VERSION ""

NS_ :

BS_:

BU_: TCM_Diesel ECM_Diesel BECMB_EPM TCM ECM Generic_BCM GWM _delete APIM BCM DCDC_VQM PAM TSTR PCM
VAL_TABLE_ TrlrAidSetup_D_Rq 3 "NotUsed" 2 "EndSetup" 1 "BeginSetup" 0 "Inactive" ;
VAL_TABLE_ IsaOffst_D_Stat 15 "Faulty" 14 "Null" 13 "Thirteen" 12 "Twelve" 11 "Eleven" 10 "Ten" 9 "Nine" 8 "Eight" 7 "Seven" 6 "Six" 5 "Five" 4 "Four" 3 "Three" 2 "Two" 1 "One" 0 "Zero" ;
VAL_TABLE_ IsaVLimUnit_D_Rq 3 "NoDataExists" 2 "Mph" 1 "Kph" 0 "Null" ;
VAL_TABLE_ ApaChime_D_Rq 7 "NotUsed2" 6 "NotUsed1" 5 "Warning_Chime" 4 "Finish_Chime" 3 "Stop_Now_Chime" 2 "Spot_Ready_Chime" 1 "Spot_Found_Chime" 0 "No_Chime" ;
VAL_TABLE_ IsaVLim_D_Rq 183 "NotUsed_3_to_72_toHexFC" 2 "LimitSpeed2_to_178_toHexB2" 255 "Faulty" 254 "NoDataExists" 253 "NotUsed_73" 182 "NotUsed_2" 181 "NotUsed_1" 180 "LimitSpeed_180_kph_mph" 179 "LimitSpeed_179_kph_mph" 1 "LimitSpeed_1_kph_mph" 0 "LimitSpeed_0_kph_mph" ;
VAL_TABLE_ SlMde_D_Stat 3 "NotUsed" 2 "Manual_Mode" 1 "Auto_Mode" 0 "Null" ;
VAL_TABLE_ SlMde_D_RqDsply 3 "NotUsed" 2 "ManualSpeed_LimiterSymbol" 1 "AutoSpeed_LimiterSymbol" 0 "NoSpeed_LimiterSymbol" ;
VAL_TABLE_ SlMde_D_Rq 3 "NotUsed" 2 "Manual_Mode" 1 "Auto_Mode" 0 "Null" ;
VAL_TABLE_ Faulty_FF 255 "Faulty" ;
VAL_TABLE_ TrnIpcDsplyRng_D_Stat 3 "NotUsed" 2 "Flash" 1 "On" 0 "Blank_No_Display" ;
VAL_TABLE_ NoYesNoDataFaulty 3 "Faulty" 2 "NoDataExists" 1 "Yes" 0 "No" ;
VAL_TABLE_ SidePrkSnsR4_D_Stat 15 "NotUsed" 14 "NotFullyScannedYet" 13 "NoObjectInSector" 12 "Zone12" 11 "Zone11" 10 "Zone10" 9 "Zone9" 8 "Zone8" 7 "Zone7" 6 "Zone6" 5 "Zone5" 4 "Zone4" 3 "Zone3" 2 "Zone2" 1 "Zone1" 0 "Off" ;
VAL_TABLE_ PtDrvMde_D_Rq 15 "Faulty" 14 "NotUsed11" 13 "NotUsed10" 12 "NotUsed9" 11 "NotUsed8" 10 "NotUsed7" 9 "NotUsed6" 8 "NotUsed5" 7 "NotUsed4" 6 "NotUsed3" 5 "NotUsed2" 4 "NotUsed1" 3 "TowHaulGradeAssist" 2 "SnowWet" 1 "Sport" 0 "Normal" ;
VAL_TABLE_ SteEffort_D_Stat 7 "NotUsed5" 6 "NotUsed4" 5 "NotUsed3" 4 "NotUsed2" 3 "NotUsed1" 2 "Comfort" 1 "Sport" 0 "Normal" ;
VAL_TABLE_ Null_Off_On 3 "NotUsed" 2 "On" 1 "Off" 0 "Null" ;
VAL_TABLE_ TrlrAidMsgTxt_D_Rq 31 "Message31" 30 "Message30" 29 "Message29" 28 "Message28" 27 "Message27" 26 "Message26" 25 "Message25" 24 "Message24" 23 "Message23" 22 "Message22" 21 "Message21" 20 "Message20" 19 "Message19" 18 "Message18" 17 "Message17" 16 "Message16" 15 "Message15" 14 "Message14" 13 "Message13" 12 "Message12" 11 "Message11" 10 "Message10" 9 "Message9" 8 "Message8" 7 "Message7" 6 "Message6" 5 "Message5" 4 "Message4" 3 "Message3" 2 "Message2" 1 "Message1" 0 "NoMessage" ;
VAL_TABLE_ Invalid_7F 127 "Invalid" ;
VAL_TABLE_ Faulty_1FFF 8191 "Faulty" ;
VAL_TABLE_ VehStab_D_Stat 15 "Faulty" 14 "NotUsed7" 13 "NotUsed6" 12 "NotUsed5" 11 "NotUsed4" 10 "NotUsed3" 9 "NotUsed2" 8 "NotUsed1" 7 "High_SSRA_no_OS" 6 "Straight" 5 "Post_Oversteer" 4 "Post_Transition" 3 "Countersteer" 2 "Understeer" 1 "Oversteer" 0 "Linear" ;
VAL_TABLE_ FohEng_D_Rq 3 "AutoEnable_ParkEnable" 2 "AutoDisable_ParkEnable" 1 "AutoEnable_ParkDisable" 0 "Disable_Stop" ;
VAL_TABLE_ DieslPrtc2_D_RqDsply 15 "NotUsed4" 14 "NotUsed3" 13 "NotUsed2" 12 "NotUsed1" 11 "OCR_ExhFilterClean_Stopped" 10 "OCR_ExhFilterCleaned" 9 "RgnOff_AtLimit" 8 "RgnOff_Overloaded" 7 "RgnOff_Loaded" 6 "Exhaust_Filter_Full" 5 "DPF_Overlimit" 4 "DPF_AtLimit" 3 "ExhFilter_Drive_Completed" 2 "Cleaning_Exhaust_Filter" 1 "DPF_Overloaded" 0 "DPF_Normal_Operation" ;
VAL_TABLE_ Null_Pers1_4_Vehicle 7 "Unused_2" 6 "Unused_1" 5 "Vehicle" 4 "PERS_4" 3 "PERS_3" 2 "PERS_2" 1 "PERS_1" 0 "Null" ;
VAL_TABLE_ PrkLckCtlEnbl_D_RqIpc 3 "Rq_Towing" 2 "Rq_Enable" 1 "Rq_Disable" 0 "Null" ;
VAL_TABLE_ PrkLckCtlUnlck_D_Stat 3 "Trans_And_Steer_Unlckd" 2 "Steering_Unlckd" 1 "Transmission_Unlckd" 0 "Null" ;
VAL_TABLE_ VehKeyActv_D_Stat 15 "NotUsed7" 14 "NotUsed6" 13 "NotUsed5" 12 "NotUsed4" 11 "NotUsed3" 10 "NotUsed2" 9 "NotUsed1" 8 "Key8Active" 7 "Key7Active" 6 "Key6Active" 5 "Key5Active" 4 "Key4Active" 3 "Key3Active" 2 "Key2Active" 1 "Key1Active" 0 "NoKeyActive" ;
VAL_TABLE_ VehLckInd_D_Rq 3 "NotUsed" 2 "On_Day" 1 "On_Night" 0 "Off" ;
VAL_TABLE_ PrkBrkDynmc_D_Allw 3 "NotUsed" 2 "EPB_ECD_NotPossible" 1 "EPB_ECD_Possible" 0 "Used_at_Start_Up" ;
VAL_TABLE_ TrnGearMsgTxt_D_Rq 31 "Message_31" 30 "Message_30" 29 "Message_29" 28 "Message_28" 27 "Message_27" 26 "Message_26" 25 "Message_25" 24 "Message_24" 23 "Message_23" 22 "Message_22" 21 "Message_21" 20 "Message_20" 19 "Message_19" 18 "Message_18" 17 "Message_17" 16 "Message_16" 15 "Message_15" 14 "Message_14" 13 "Message_13" 12 "Message_12" 11 "Message_11" 10 "Message_10" 9 "Message_9" 8 "Message_8" 7 "Message_7" 6 "Message_6" 5 "Message_5" 4 "Message_4" 3 "Message_3" 2 "Message_2" 1 "Message_1" 0 "NoMessage" ;
VAL_TABLE_ Off_On_Unknown_Invalid 3 "Invalid" 2 "Unknown" 1 "On" 0 "Off" ;
VAL_TABLE_ AutoLghtMde_D_Stat 3 "Not_Used" 2 "GFHB" 1 "AHBC" 0 "Manual" ;
VAL_TABLE_ GfhbDistr_D_Stat 7 "High_Beam_Classis" 6 "High_Beam_GFHB" 5 "GFHB_with_Vert_Adjustment" 4 "GFHB_with_Spot" 3 "Motorway" 2 "Low_Beam_GFHB" 1 "Low_Beam_Classic" 0 "Symmetric" ;
VAL_TABLE_ GfhbV_D 3 "Immediately" 2 "Fast" 1 "Medium" 0 "Slow" ;
VAL_TABLE_ GfhbLamp_D_Stat 3 "Both_On" 2 "Left_On_Right_Off" 1 "Right_On_Left_Off" 0 "Both_Off" ;
VAL_TABLE_ GfhbDistrChng_D_Stat 3 "Both_in_Transition" 2 "Left_in_Transition" 1 "Right_in_Transition" 0 "Both_Static" ;
VAL_TABLE_ NoData_Faulty_3E_3F 63 "Faulty" 62 "NoDataExists" ;
VAL_TABLE_ Unknown_Invalid_1FE_1FF 511 "Invalid" 510 "Unknown" ;
VAL_TABLE_ Invalid_0x0 0 "Invalid" ;
VAL_TABLE_ Unknown_Invalid_3E_3F 63 "Invalid" 62 "Unknown" ;
VAL_TABLE_ Faulty_1FF 511 "Faulty" ;
VAL_TABLE_ NoData_Faulty_1FFF_1FFE 8191 "Faulty" 8190 "NoDataExists" ;
VAL_TABLE_ AwdSys_D_Stat 3 "Faulty" 2 "NotUsed" 1 "_4x4_L_H_Active" 0 "_4x4_L_H_Inactive" ;
VAL_TABLE_ EmotiveType_D_Dsply 3 "EmotiveDisplay_3" 2 "EmotiveDisplay_2" 1 "EmotiveDisplay_1" 0 "Null" ;
VAL_TABLE_ AutoRgenTxt_B_RqDsply 1 "AutExhFilterCleanOFF" 0 "AutExhFilterCleanON" ;
VAL_TABLE_ AutoRgen_D_Rq 3 "NotUsed" 2 "AutExhFilterCleanOFF" 1 "AutExhFilterCleanON" 0 "No_Mode_Selected" ;
VAL_TABLE_ TrnSrvcRqd_B_Rq 1 "On" 0 "Off" ;
VAL_TABLE_ PlgOvrrdStrt_D_Cmd 3 "NotUsed" 2 "Override_Plug_Status" 1 "Dont_Override_Plug_Status" 0 "Null_State" ;
VAL_TABLE_ immoSecureIdleMode 3 "NotUsed2" 2 "NotUsed1" 1 "Active" 0 "Inactive" ;
VAL_TABLE_ SteMdule_D_Stat 7 "NotUsed" 6 "EPAS_Failure3" 5 "EPAS_Failure2" 4 "System_Failure" 3 "EPAS_Shutdown" 2 "Normal_Op_Full_Assist" 1 "Normal_Op_Limited_Assist" 0 "EPAS_Initialization" ;
VAL_TABLE_ Faulty_3FF 1023 "Faulty" ;
VAL_TABLE_ Invalid_F 15 "Invalid" ;
VAL_TABLE_ Invalid_1F 31 "Invalid" ;
VAL_TABLE_ NoData_Faulty_FFFFFE_FFFFFF 16777215 "Faulty" 16777214 "NoDataExists" ;
VAL_TABLE_ NoData_Faulty_FE_FF 255 "Faulty" 254 "NoDataExists" ;
VAL_TABLE_ PtRmtRprt_D_Rq 15 "NotUsed6" 14 "NotUsed5" 13 "NotUsed4" 12 "NotUsed3" 11 "NotUsed2" 10 "NotUsed1" 9 "Rprt_Rq_Chrg_Not_Occur" 8 "Rprt_Rq_SOC_1_Reached" 7 "Rprt_Rq_Battery_Temp" 6 "Rprt_Rq_Reduced_Perf" 5 "Rprt_Rq_Limited_Perf" 4 "Rprt_Rq_Charge_Fault" 3 "Rprt_Rq_Bulk_Charged" 2 "Rprt_Rq_Preconditioned" 1 "Rprt_Rq_Trip_Distance" 0 "No_Report_Request" ;
VAL_TABLE_ Invalid_NotReq_Req 0 "Invalid" 1 "Not_Requested" 2 "Requested" 3 "NotUsed" ;
VAL_TABLE_ Invalid_NoConflict_Conflict 7 "NotUsed5" 6 "NotUsed4" 5 "NotUsed3" 4 "NotUsed2" 3 "NotUsed1" 2 "Clonflict_Exists" 1 "No_Conflict" 0 "Invalid" ;
VAL_TABLE_ Inactive_NotReq_Req 0 "Inactive" 1 "Not_Requested" 2 "Requested" 3 "NotUsed" ;
VAL_TABLE_ PreCondStat_D_Dsply 7 "Reserved3" 6 "Reserved2" 5 "Reserved1" 4 "Faulted" 3 "Complete" 2 "In_Progress" 1 "Scheduled" 0 "Not_Scheduled" ;
VAL_TABLE_ BattElecPerf_D_Actl 7 "NotUsed" 6 "Hot_Batt_Severe_Lim_Perf" 5 "Hot_Batt_Reduced_Perf" 4 "Hot_Batt_Close_to_lim_Per" 3 "Cold_Batt_Severe_Lim_Perf" 2 "Cold_Batt_Reduced_Perf" 1 "Cold_Batt_Close_to_lim_Pe" 0 "Ok_no_message_displayed" ;
VAL_TABLE_ ChkPlgtoStrt_D_Dsply 3 "NotUsed" 2 "Is_VehicleUnplugged_Prompt" 1 "Check_Plug_to_start" 0 "No_Message_Display" ;
VAL_TABLE_ PwrFlowTxt_D_Dsply 15 "NotUsed7" 14 "NotUsed6" 13 "NotUsed5" 12 "NotUsed4" 11 "NotUsed3" 10 "NotUsed2" 9 "NotUsed1" 8 "Disp_Charge_Cmplt_Txt" 7 "Disp_Remote_Start_Txt" 6 "Disp_Eng_Drv_Txt" 5 "Disp_Elec_Drv_Txt" 4 "Disp_Idle_with_Chrg_Txt" 3 "Disp_Idle_Txt" 2 "Disp_Charg_HV_Batt_Txt" 1 "Disp_Hyb_Drive_Txt" 0 "No_Text" ;
VAL_TABLE_ EngOnMsg_D_Dsply 12 "Battery_Temperature" 11 "Hill_Decent_Control" 10 "Fuel_Maintenance" 9 "Oil_Maintenance" 8 "Normal_Operation" 7 "Low_Gear" 6 "Batt_Charging" 5 "Engine_Cold" 4 "Neutral_Gear" 3 "Heater_Setting" 2 "High_Speed" 1 "Acceleration" 0 "No_Display" 13 "Not_Used_States_0xD_0x1F" ;
VAL_TABLE_ PtDataKeyId_D_Stat 15 "NotUsed5" 14 "NotUsed4" 13 "NotUsed3" 12 "NotUsed2" 11 "NotUsed1" 10 "Tot_Veh_NUT" 9 "Cust_4_NUT" 8 "Cust_3_NUT" 7 "Cust_2_NUT" 6 "Cust_1_NUT" 5 "Tot_Veh_Stat" 4 "Cust_4_Stat" 3 "Cust_3_Stat" 2 "Cust_2_Stat" 1 "Cust_1_Stat" 0 "Null" ;
VAL_TABLE_ ChrgStat_D_Dsply 7 "NotUsed" 6 "Complete" 5 "Scheduled" 4 "In_Progress" 3 "Fault_Outside_Car" 2 "Fault_Inside_Car" 1 "Fault_Unknown_Location" 0 "Not_Ready" ;
VAL_TABLE_ TrnLvrV_D_Rq 3 "Full_Speed" 2 "Aggressive" 1 "Normal" 0 "Quiet" ;
VAL_TABLE_ FuelMaintMde_D_Rq 3 "Feature_Not_Present" 2 "Fuel_Maint_Req_Now" 1 "Fuel_Maint_Req_Soon" 0 "NoRequest" ;
VAL_TABLE_ FuelMaintMde_D_Dsply 3 "Feature_Not_Present" 2 "In_Fuel_Maint_Mode" 1 "Close_to_Fuel_Maint" 0 "OK" ;
VAL_TABLE_ DynoMde_B_Cmd 1 "Two_Wheel_Dyno" 0 "Normal_Operation" ;
VAL_TABLE_ HvacPrecondRecirc_D_Rq 3 "Last_User_Setting" 2 "Auto" 1 "Recirc" 0 "Outside" ;
VAL_TABLE_ HvacPrecondAC_D_Rq 3 "Last_User_Setting" 2 "Auto" 1 "On" 0 "Off" ;
VAL_TABLE_ HybMdeStat_D_Dsply 7 "NotUsed2" 6 "NotUsed1" 5 "EV_Override" 4 "Forced_EV_Mode" 3 "Forced_Charge_Sustain_Mode" 2 "Auto_Charge_Sustain_Mode" 1 "Auto_Charge_Deplete_Mode" 0 "Null_State" ;
VAL_TABLE_ PwFlowPlgBatt_D_Dsply 3 "NotUsed" 2 "Flow_from_Plug_to_Batt" 1 "Flow_from_Batt_to_Plug" 0 "No_Flow" ;
VAL_TABLE_ PwFlowEngMtr_D_Dsply 3 "NotUsed" 2 "Flow_from_Eng_to_Mtr" 1 "Flow_from_Mtr_to_Eng" 0 "No_Flow" ;
VAL_TABLE_ PwFlowEngFuel_D_Dsply 3 "NotUsed" 2 "Flow_from_Eng_to_Fuel" 1 "Flow_from_Fuel_to_Eng" 0 "No_Flow" ;
VAL_TABLE_ PwFlowMtrDrv_D_Dsply 3 "NotUsed" 2 "Flow_from_Mtr_to_Axle" 1 "Flow_from_Axle_to_Mtr" 0 "No_FLow" ;
VAL_TABLE_ PwFlowEngDrv_D_Dsply 3 "NotUsed" 2 "Flow_from_Eng_to_Axle" 1 "Flow_from_Axle_to_Eng" 0 "No_Flow" ;
VAL_TABLE_ PwFlowBattMtr_D_Dsply 3 "NotUsed" 2 "Flow_from_Batt_to_Mtr" 1 "Flow_from_Mtr_to_Batt" 0 "No_Flow" ;
VAL_TABLE_ Null_Override_Invalid 3 "NotUsed" 2 "Invalid" 1 "Override" 0 "Null" ;
VAL_TABLE_ HybMdeMsgTxt_D_Rq 7 "NotUsed2" 6 "NotUsed1" 5 "EV_Not_Avail_Message" 4 "EV_Mode_Message" 3 "Delayed_Discharge_Message" 2 "Override_Available_Message" 1 "AutoMode_Message" 0 "Null_NoMessage_Request" ;
VAL_TABLE_ HybMdeLimMsgTxt_D_Rq 3 "Limited_Low_Power_and_SOC" 2 "Limited_Low_SOC" 1 "Limited_Low_Power" 0 "Null" ;
VAL_TABLE_ CenterStackRing_D_Actl 3 "LimitedOn" 2 "On" 1 "Off" 0 "Null" ;
VAL_TABLE_ ConsTipUnitPt_D_Dsply 3 "NotUsed" 2 "FuelEconomy" 1 "Distance" 0 "Percentage" ;
VAL_TABLE_ ConsTipMsg1_D_Dsply 15 "NotUsed10" 14 "NotUsed9" 13 "NotUsed8" 12 "NotUsed7" 11 "NotUsed6" 10 "NotUsed5" 9 "NotUsed4" 8 "NotUsed3" 7 "NotUsed2" 6 "NotUsed1" 5 "ReduceIdleTime" 4 "ClimateUsage" 3 "VehicleSpeed" 2 "Deceleration" 1 "Acceleration" 0 "NoDisplay" ;
VAL_TABLE_ NoData_Faulty_FFFE_FFFF 65535 "Faulty" 65534 "NoDataExists" ;
VAL_TABLE_ NoData_Faulty_FFE_FFF 4095 "Faulty" 4094 "NoDataExists" ;
VAL_TABLE_ NoData_Faulty_3FE_3FF 1023 "Faulty" 1022 "NoDataExists" ;
VAL_TABLE_ ReFuelSysStat_D_Dsply 7 "NotUsed3" 6 "NotUsed2" 5 "NotUsed1" 4 "Refuel_Err" 3 "Close_Fuel_Door" 2 "Refuel_Ready" 1 "Wait_To_Fuel" 0 "Null" ;
VAL_TABLE_ OffOn_NotUsed 3 "NotUsed2" 2 "NotUsed1" 1 "On" 0 "Off" ;
VAL_TABLE_ DrQltyDrv_D_StatGsm 7 "Faulty" 6 "NoDataExists" 5 "NotUsed2" 4 "NotUsed1" 3 "ClosedDegraded" 2 "OpenDegraded" 1 "ClosedOkay" 0 "OpenOkay" ;
VAL_TABLE_ ChrgrInPwType_D_Actl 6 "NotUsed3" 5 "NotUsed2" 4 "NotUsed1" 3 "DC_Fast_Charging" 2 "AC_Level2_240v" 1 "AC_Level1_120v" 0 "EVSE_Not_Detected" ;
VAL_TABLE_ ChrgrSysFalt1_D_Stat 3 "NotUsed" 2 "Pass" 1 "Fail" 0 "NotDiagnoseYet" ;
VAL_TABLE_ PepsKeyActv_D_Stat 15 "NotUsed11" 14 "NotUsed10" 13 "NotUsed9" 12 "NotUsed8" 11 "NotUsed7" 10 "NotUsed6" 9 "NotUsed5" 8 "Key4Active" 7 "NotUsed4" 6 "NotUsed3" 5 "NotUsed2" 4 "Key3Active" 3 "NotUsed1" 2 "Key2Active" 1 "Key1Active" 0 "NoKeyActive" ;
VAL_TABLE_ CellRstrt_D_Rq 3 "NotUsed" 2 "RemoteCancel" 1 "RemoteStart" 0 "NoRequest" ;
VAL_TABLE_ CellChirp_D_Rq 7 "NotUsed3" 6 "NotUsed2" 5 "NotUsed1" 4 "Honk" 3 "ChirpHonk" 2 "Chirp2" 1 "Chirp1" 0 "NoRequest" ;
VAL_TABLE_ CellLock_D_Rq 7 "NotUsed3" 6 "NotUsed2" 5 "NotUsed1" 4 "TrunkRelPopGlassLgCargo" 3 "LockAllDoorsandTailgate" 2 "UnlockDriversDoor" 1 "UnlockAllDoorsandTailgate" 0 "NoRequest" ;
VAL_TABLE_ NoData_Faulty_7FE_7FF 2047 "Faulty" 2046 "NoDataExists" ;
VAL_TABLE_ EngIdlShutDwnTxt_D_Rq 3 "NotUsed" 2 "EngineShutdownOnPrevDrive" 1 "FeatureDisabledDueToFault" 0 "NoMessage" ;
VAL_TABLE_ DrvPerfMde 3 "Sport" 2 "Normal" 1 "NotUsed" 0 "NoModeSelected" ;
VAL_TABLE_ NoData_Fault_1FF_1FE 511 "Fault" 510 "NoDataExists" ;
VAL_TABLE_ NoData_Fault_FFE_FFF 4095 "Fault" 4094 "NoDataExists" ;
VAL_TABLE_ ValetMode_D_Stat 3 "Not used_3" 2 "On" 1 "Off" 0 "Null" ;
VAL_TABLE_ WeekdayEndHR_St 31 "Invalid" 30 "Unknown" 29 "Reserved_29" 28 "Reserved_28" 27 "Reserved_27" 26 "Reserved_26" 25 "Reserved_25" 24 "Reserved_24" ;
VAL_TABLE_ WeekdayEndMin_St 63 "Faulty" 62 "No_data_exists" 61 "Reserverd" 60 "Reserverd" ;
VAL_TABLE_ WeekdayStartHR_St 31 "Invalid" 30 "Unknown" 29 "Reserved_29" 28 "Reserved_28" 27 "Reserved_27" 26 "Reserved_26" 25 "Reserved_25" 24 "Reserved_24" ;
VAL_TABLE_ WeekdayStartMin_St 63 "Faulty" 62 "No_data_exists" 61 "Reserverd" 60 "Reserverd" ;
VAL_TABLE_ EngIdlShutDown_D_Stat 3 "Not_used" 2 "Engine_Shutdown" 1 "Initiated_Countdown" 0 "Normal_Operation" ;
VAL_TABLE_ StopStrtDrvMde_D_Indic 3 "NotUsed" 2 "StartStop_IndirectDeselect" 1 "StopStart_Deselected" 0 "StopStart_Selected" ;
VAL_TABLE_ StopStrtDrvMde_D_RqMnu 3 "NotUsed2" 2 "NotUsed1" 1 "StopStart_Deselected" 0 "StopStart_Selected" ;
VAL_TABLE_ StopStrtStdby_D_Indic 6 "NotUsed2" 5 "Telltale_Struck_Out" 4 "Telltale_Flashing_Amber" 3 "Telltale_On_Amber" 2 "Telltale_Flashing_Green" 1 "Telltale_On_Green" 0 "Telltale_Off" 7 "NotUsed3" ;
VAL_TABLE_ Quality_Faulty 3 "OK" 2 "Degraded" 1 "No_Data_Exists" 0 "Faulty" ;
VAL_TABLE_ TrnDtpCmd_D_Actl 7 "NotUsed4" 6 "NotUsed3" 5 "NotUsed2" 4 "Relatch" 3 "Deploy" 2 "Self_Test" 1 "No_Command" 0 "NotUsed1" ;
VAL_TABLE_ TrnGsmNtmState_D_Actl 3 "Faulty" 2 "Neutral_Tow_Mode" 1 "Car_Wash_Mode" 0 "None" ;
VAL_TABLE_ TrnTrcmPwmSig_D_Actl 15 "Faulty" 14 "NoDataExists" 13 "NotUsed5" 12 "NotUsed4" 11 "NotUsed3" 10 "NotUsed2" 9 "NotUsed1" 8 "Default_To_Park" 7 "Neutral_Tow" 6 "Car_Wash_Mode" 5 "Manual" 4 "Drive" 3 "Neutral" 2 "Reverse" 1 "Park" 0 "No_Gear" ;
VAL_TABLE_ RgenBrkDynoMde_B_Actl 1 "TwoWheelDyno" 0 "NormalOperation" ;
VAL_TABLE_ Fault_3FFF 16383 "Fault" ;
VAL_TABLE_ PrkBrkActv_D_RqTrnGear 3 "NotUsed2" 2 "RequestParkBrakeEngage" 1 "NoRequest" 0 "NotUsed1" ;
VAL_TABLE_ NoRequest_Request 1 "Request" 0 "NoRequest" ;
VAL_TABLE_ Fault_FFF_NoData 4094 "NoDataExists" 4095 "Fault" ;
VAL_TABLE_ Fault_3FF_NoData 1022 "NoDataExists" 1023 "Fault" ;
VAL_TABLE_ Foh_D_Stat 7 "Unused3" 6 "Unused2" 5 "Unused1" 4 "Stopping" 3 "Running" 2 "Starting" 1 "Prestart" 0 "Off" ;
VAL_TABLE_ FohFalt_D_Stat 15 "NotUsed4" 14 "NotUsed3" 13 "NotUsed2" 12 "NotUsed1" 11 "FuelTypeDoesNotMatchFOH" 10 "Lifecycle_ModeNotSet" 9 "AuxElectricCoolantPumpInop" 8 "TimeDelayAvoidExcessCycl" 7 "Fuel_Level_OutofRange" 6 "External_Fault" 5 "Internal_Fault" 4 "Voltage_limitation" 3 "Impact_Event" 2 "CoolantTemp_OutofRange" 1 "AmbientTemp_OutofRange" 0 "No_Disable" ;
VAL_TABLE_ FohRqRun_B_Rq 1 "SubmitRequest_toRun" 0 "DoesNotSubmitRequest_toRun" ;
VAL_TABLE_ OKLowVeryLow 3 "NotUsed" 2 "VeryLow" 1 "Low" 0 "OK" ;
VAL_TABLE_ Fault_1FF 511 "Fault" ;
VAL_TABLE_ NoMessage_DisplayMessage 1 "DisplayMessage" 0 "NoMessage" ;
VAL_TABLE_ EngineBrakeOff_Active 1 "Engine_Braking_Activated" 0 "Engine_Braking_Off" ;
VAL_TABLE_ NoEngineBrake_Brake 1 "Engine_Braking" 0 "No_Engine_Braking" ;
VAL_TABLE_ PlgActv_D_ActlChrgr 3 "Faulty" 2 "Not used_2" 1 "On_Plug__Connected_" 0 "Off_Plug__Disconnected_" ;
VAL_TABLE_ EngSrvcRqd_B_Rq 1 "Engine_Service_Required" 0 "No_engine_service_required" ;
VAL_TABLE_ WeekendEndHR_St 31 "Invalid" 30 "Unknown" 29 "Reserved_29" 28 "Reserved_28" 27 "Reserved_27" 26 "Reserved_26" 25 "Reserved_25" 24 "Reserved_24" ;
VAL_TABLE_ WeekendEndMin_St 63 "Faulty" 62 "No_data_exists" 61 "Reserverd" 60 "Reserverd" ;
VAL_TABLE_ WeekendStartHR_St 31 "Invalid" 30 "Unknown" 29 "Reserved_29" 28 "Reserved_28" 27 "Reserved_27" 26 "Reserved_26" 25 "Reserved_25" 24 "Reserved_24" ;
VAL_TABLE_ WeekendStartMin_St 63 "Faulty" 62 "No_data_exists" 61 "Reserverd" 60 "Reserverd" ;
VAL_TABLE_ NextUsg_Toggle_St 2 "Disabled" 1 "Enabled" 0 "Null" ;
VAL_TABLE_ NxtUsgDay_No_Actl 31 "Invalid" ;
VAL_TABLE_ NxtUsgHr_No_Actl 31 "Invalid" 30 "Unknown" ;
VAL_TABLE_ NxtUsgMin_No_Actl 63 "Invalid" 62 "Unknown" ;
VAL_TABLE_ NxtUsgMnth_No_Actl 15 "Invalid" ;
VAL_TABLE_ NxtUsgPreCndID_No_Actl 0 "Invalid" ;
VAL_TABLE_ NxtUsgYr_No_Actl 31 "Invalid" ;
VAL_TABLE_ PtRmtRprt_D_Stat 9 "In_Progress_Chrg_Not_Occur" 8 "In_Progress_SOC_1_Reached" 7 "In_Progress_Battery_Temp" 6 "In_Progress_Reduced_Perf" 5 "In_Progress_Limited_Perf" 4 "In_Progress_Charge_Fault" 3 "In_Progress_Bulk_Charged" 2 "In_Progress_Preconditioned" 1 "In_Progress_Trip_Distance" 0 "Not_In_Progress" ;
VAL_TABLE_ Allowed_Denied 1 "Denied" 0 "Allowed" ;
VAL_TABLE_ PrkAidMsgTxt_D_Rq 15 "NotUsed7" 14 "NotUsed6" 13 "NotUsed5" 12 "R_Sns_Inactive_Trlr_atch" 11 "Not_Avail_Trlr_attchd" 10 "Fail_Mode_no_Chime" 9 "Fail_Mode_with_Chime" 8 "NotUsed4" 7 "NotUsed3" 6 "Park_Sys_Alternate_Mode" 5 "R_Snsrs_On_F_Snsrs_On" 4 "NotUsed2" 3 "NotUsed1" 2 "R_Snsrs_Off_F_Snsrs_On" 1 "R_Snsrs_On_F_Snsrs_Off" 0 "All_Park_Sensors_Off" ;
VAL_TABLE_ PrkAidSns_D_Stat 15 "Zone_15" 14 "Zone_14" 13 "Zone_13" 12 "Zone_12" 11 "Zone_11" 10 "Zone_10" 9 "Zone_9" 8 "Zone_8" 7 "Zone_7" 6 "Zone_6" 5 "Zone_5" 4 "Zone_4" 3 "Zone_3" 2 "Zone_2" 1 "Zone_1" 0 "Off" ;
VAL_TABLE_ PrkAid_D_Falt 7 "NotUsed2" 6 "NotUsed1" 5 "Failure_Front_PSM_Sensors" 4 "No_Data_Exists" 3 "Failure_Rear_Sensors" 2 "Speaker_Fault" 1 "ECU_Fault" 0 "No_Fault" ;
VAL_TABLE_ OffOnNoDataFault 3 "Fault" 2 "No_Data_Exists" 1 "On" 0 "Off" ;
VAL_TABLE_ ApaSwtch_D_RqDrv 3 "Faulty" 2 "Stuck" 1 "Pressed" 0 "NotPressed" ;
VAL_TABLE_ ApaActvSd_D_Actl 3 "Dirver_Side" 2 "Passenger_Side" 1 "No_Side" 0 "Null" ;
VAL_TABLE_ ApaMdeStat_D_RqDrv 7 "Faulty" 6 "Off" 5 "NotUsed2" 4 "NotUsed1" 3 "POA" 2 "PPA" 1 "SAPP" 0 "Inactive" ;
VAL_TABLE_ ApaMde_D_Avail 15 "NotUsed7" 14 "NotUsed6" 13 "NotUsed5" 12 "NotUsed4" 11 "NotUsed3" 10 "NotUsed2" 9 "NotUsed1" 8 "PPA_POA" 7 "SAPP_POA" 6 "POA" 5 "PPA" 4 "SAPP" 3 "SAPP_PPA_POA" 2 "SAPP_PPA" 1 "None" 0 "Null" ;
VAL_TABLE_ ApaMde_D_Stat 7 "NotUsed3" 6 "NotUsed2" 5 "NotUsed1" 4 "POA" 3 "PPA" 2 "SAPP" 1 "Off" 0 "Null" ;
VAL_TABLE_ FrostWarn_D_Stat 3 "NotUsed" 2 "On_Amber" 1 "On_Red" 0 "Off" ;
VAL_TABLE_ SteWhlLckMsgTxt_D_Rq 3 "NotUsed" 2 "Message_2" 1 "Message_1" 0 "No_Message" ;
VAL_TABLE_ GearRvrse_D_Actl 7 "Fault" 6 "NotUsed_3" 5 "NotUsed_2" 4 "NotUsed_1" 3 "Active_confirmed" 2 "Active_not_confirmed" 1 "Inactive_confirmed" 0 "Inactive_not_confirmed" ;
VAL_TABLE_ DrTGate_D_Rq 3 "NotUsed" 2 "Closing" 1 "Opening" 0 "Not_Moving" ;
VAL_TABLE_ WndwSide_D_Stat 3 "BothWindow_Operating" 2 "RearWindow_Operating" 1 "FrontWindow_Operating" 0 "NoWindows_Operating" ;
VAL_TABLE_ DcacElPw_D_Rq 3 "NotUsed" 2 "AC_HighPower_Requested" 1 "AC_LowPower_Requested" 0 "AC_Power_NotRequested" ;
VAL_TABLE_ Null_Ack_Nack_NotUsed 3 "Not_Used" 2 "Nack" 1 "Ack" 0 "Null" ;
VAL_TABLE_ Null_Reset 1 "Reset" 0 "Null" ;
VAL_TABLE_ Unknown_FFFD_Invalid_NotSup 65535 "Not_Supported" 65534 "Invalid" 65533 "Unknown" ;
VAL_TABLE_ HvacBlwrFront_D_Stat 31 "Not_Used" 20 "Full_On" 19 "95_Percent" 18 "90_Percent" 17 "85_Percent" 16 "80_Percent" 15 "75_Percent" 14 "70_Percent" 13 "65_Percent" 12 "60_Percent" 11 "55_Percent" 10 "50_Percent" 9 "45_Percent" 8 "40_Percent" 7 "35_Percent" 6 "30_Percent" 5 "25_Percent" 4 "20_Percent" 3 "15_Percent" 2 "10_Percent" 1 "5_Percent" 0 "Off" ;
VAL_TABLE_ immoMsgTxt_D_Rq 15 "Immo_Msg_15" 14 "Immo_Msg_14" 13 "Immo_Msg_13" 12 "Immo_Msg_12" 11 "Immo_Msg_11" 10 "Immo_Msg_10" 9 "Immo_Msg_9" 8 "Immo_Msg_8" 7 "Immo_Msg_7" 6 "Immo_Msg_6" 5 "Immo_Msg_5" 4 "Immo_Msg_4" 3 "Immo_Msg_3" 2 "Immo_Msg_2" 1 "Immo_Msg_1" 0 "Immo_Msg_0_Null" ;
VAL_TABLE_ BattTracWarnLamp_B_Rq 1 "On" 0 "Off" ;
VAL_TABLE_ BattTracSrvcRqd_B_Rq 1 "On" 0 "Off" ;
VAL_TABLE_ HtrnWarnLamp_B_Dsply 1 "On" 0 "Off" ;
VAL_TABLE_ HtrnSrvcRqd_B_Dsply 1 "On" 0 "Off" ;
VAL_TABLE_ NtfyDrvTrgtDist_L_Rq 4095 "Trip_dist_alert_disabled" 0 "Inactive" ;
VAL_TABLE_ NtfyDrvSocLvl1_Pc_Rq 127 "TargetSOCNotificationAlert" 0 "Inactive" ;
VAL_TABLE_ PtWakeupActv1_B_Rq 1 "Wake_up_Powertrain_via_HW" 0 "Don_t_Wake_Up_Powertrain" ;
VAL_TABLE_ PreCondACSet_D_Actl 3 "Last_User_Setting" 2 "Auto" 1 "On" 0 "Off" ;
VAL_TABLE_ PreCondFanSet_D_Actl 15 "Not_used" 14 "Not_used" 13 "Not_used" 12 "Not_used" 11 "Not_used" 10 "Not_used" 9 "Last_user_setting" 8 "Auto" 7 "Speed_7" 6 "Speed_6" 5 "Speed_5" 4 "Speed_4" 3 "Speed_3" 2 "Speed_2" 1 "Speed_1" 0 "OFF" ;
VAL_TABLE_ PreCondID_No_Actl 0 "Invalid" ;
VAL_TABLE_ PreCondRecrcSet_D_Actl 3 "Last_User_Setting" 2 "Auto" 1 "Recirc" 0 "Outside/Fresh" ;
VAL_TABLE_ PreCondTeSet_Te_Actl 31 "HI" 1 "LO" 0 "Last_driver_setting" ;
VAL_TABLE_ PreCondTPRDef_D_Actl 3 "NotUsed" 2 "On" 1 "Off" 0 "Null" ;
VAL_TABLE_ PreCondModeSet_D_Actl 15 "Not_used" 14 "Not_used" 13 "Not_used" 12 "Not_used" 11 "LastUserSetting" 10 "Auto" 9 "Max_Defrost" 8 "Windshield_Panel_Floor" 7 "Windshield_Panel" 6 "Windshield_(Defrost)" 5 "Windshield_Floor" 4 "Floor" 3 "Panel_Floor" 2 "Panel_(Vent)" 1 "Max_A/C" 0 "Off" ;
VAL_TABLE_ ChargePortPwr_St 2 "LowPower" 1 "HighPower" 0 "Null" ;
VAL_TABLE_ ChargeProfIDPref_St 2 "Value" 1 "ChargeNow" 0 "Null" ;
VAL_TABLE_ ChrgGlobSched_D_Actl 3 "NotUsed" 2 "On" 1 "Off" 0 "Null" ;
VAL_TABLE_ ChrgLocEndHr_No_Actl 31 "Invalid" 30 "Unknown" ;
VAL_TABLE_ ChrgLocEndMin_No_Actl 63 "Invalid" 62 "Unknown" ;
VAL_TABLE_ ChrgLocProgram_D_Actl 7 "Not_used" 6 "Not_used" 5 "Not_used" 4 "Manual" 3 "TimeofUse" 2 "SmMet" 1 "ChargeImm" 0 "Null" ;
VAL_TABLE_ ChrgLocSchedCat_D_Actl 11 "Reserved" 10 "Window_10" 9 "Window_9" 8 "Window_8" 7 "Window_7" 6 "Window_6" 5 "Window_5" 4 "Window_4" 3 "Window_3" 2 "Window_2" 1 "Window_1" 0 "Null" ;
VAL_TABLE_ ChrgLocHsphs_D_Actl 7 "NotUsed3" 6 "NotUsed2" 5 "NotUsed1" 4 "SouthEast_Lat-_Long+" 3 "SouthWest_Lat-_Long-" 2 "NorthEast_Lat+_Long+" 1 "NorthWest_Lat+_Long-" 0 "NoDataExists" ;
VAL_TABLE_ FuelPumpPwr_D_Stat 7 "NotUsed3" 6 "NotUsed2" 5 "NotUsed1" 4 "Power_Off_Default" 3 "Power_Off_Command" 2 "Power_Off_Service" 1 "Power_Off_Impact" 0 "Power_On" ;
VAL_TABLE_ ChrgrRdyStat_D_Actl 7 "NotUsed5" 6 "NotUsed4" 5 "NotUsed3" 4 "NotUsed2" 3 "NotUsed1" 2 "ChargerFault" 1 "ChargerReady" 0 "NotReady" ;
VAL_TABLE_ PrmtrAlrmEvnt_D_Stat 15 "NotUsed" 14 "Trailer" 13 "Shock_Sensor" 12 "Post_Crash" 11 "Panic" 10 "Intrusion" 9 "Inclination" 8 "Ign_Tamper" 7 "LG_Door" 6 "Decklid" 5 "Hood" 4 "PR_Door" 3 "PF_Door" 2 "DR_Door" 1 "DF_Door" 0 "Null" ;
VAL_TABLE_ SecurityMsgTxt_D_Rq 3 "Message3" 2 "Message2" 1 "Message1" 0 "NoMessage" ;
VAL_TABLE_ BattChrgInhbt_D_Rq 3 "NotUsed" 2 "Disregard" 1 "Inhibit_Charging" 0 "Enable_Charging" ;
VAL_TABLE_ Fault_7FF_NoData 2047 "Fault" 2046 "NoDataExists" ;
VAL_TABLE_ Deactivate_Activate 1 "Activate" 0 "Deactivate" ;
VAL_TABLE_ PtcHtr_D_Cmd 3 "TurnOn" 2 "AutoMode" 1 "TurnOff" 0 "NoDecision_Initializing" ;
VAL_TABLE_ Fault_FFFFFF 16777215 "Fault" ;
VAL_TABLE_ TrnMsgTxt2_D_Rq 7 "NotUsed3" 6 "NotUsed2" 5 "NotUsed1" 4 "TransTooHot_LoudChime" 3 "PressBrake_LoudChime" 2 "PressBrake_SoftChime" 1 "PressBrake_NoChime" 0 "NoText_NoChime" ;
VAL_TABLE_ NoData_Fault_FFFE_FFFF 65535 "Fault" 65534 "NoDataExists" ;
VAL_TABLE_ EngOffTe_B_Dsply 1 "Eng_warm_engh_for_pd" 0 "Eng_not_warm_engh_for_pd" ;
VAL_TABLE_ DrvEffLvlIncDec_D_Cmd 3 "NotUsed" 2 "Decrease_Level_by_1" 1 "Increase_Level_by_1" 0 "Null_State" ;
VAL_TABLE_ Fault_FFFF_NoData_FFFE 65535 "Fault" 65534 "NoDataExists" ;
VAL_TABLE_ Fault_1FFF 8191 "Fault" ;
VAL_TABLE_ ElPw_D_StatStrtStop 15 "NotUsed6" 14 "NotUsed5" 13 "NotUsed4" 12 "NotUsed3" 11 "NotUsed2" 10 "NotUsed1" 9 "Supported_Level_4" 8 "Supported_Level_3" 7 "Supported_Level_2" 6 "Supported_Level_1" 5 "Limited_Support" 4 "Fault_Limited" 3 "LV_Event_in_Progress" 2 "Not_Supported_Imminent" 1 "Supported_All" 0 "Not_Supported" ;
VAL_TABLE_ ImpactEvntFdbck_D_Stat 3 "NotUsed" 2 "EventComplete" 1 "EventInProgress" 0 "Normal" ;
VAL_TABLE_ StopStrtIODTxt_D_Rq 31 "Message31" 30 "Message30" 29 "Message29" 28 "Message28" 27 "Message27" 26 "Message26" 25 "Message25" 24 "Message24" 23 "Message23" 22 "Message22" 21 "Message21" 20 "Message20" 19 "Message19" 18 "Message18" 17 "Message17" 16 "Message16" 15 "Message15" 14 "Message14" 13 "Message13" 12 "Message12" 11 "Message11" 10 "Message10" 9 "Message9" 8 "Message8" 7 "Message7" 6 "Message6" 5 "Message5" 4 "Message4" 3 "Message3" 2 "Message2" 1 "Message1" 0 "NoMessage" ;
VAL_TABLE_ NoData_Fault_7FFE_7FFF 32767 "Fault" 32766 "NoDataExists" ;
VAL_TABLE_ NoData_Fault_3E_3F 63 "Fault" 62 "NoDataExists" ;
VAL_TABLE_ DrvSte_D_Stat 15 "NotUsed10" 14 "NotUsed9" 13 "NotUsed8" 12 "NotUsed7" 11 "NotUsed6" 10 "NotUsed5" 9 "NotUsed4" 8 "NotUsed3" 7 "NotUsed2" 6 "NotUsed1" 5 "Request_Active" 4 "Ignition_Off" 3 "DSR_in_Normal_Idle_Mode" 2 "EPAS_Comm_Disturbed" 1 "DSR_Request_Not_Applicable" 0 "DSR_Deactivated" ;
VAL_TABLE_ Null_Open 1 "Open" 0 "Null" ;
VAL_TABLE_ HeadLghtHiFdbck_D_Stat 3 "NotUsed" 2 "Cancel" 1 "Hold" 0 "Allow_Change" ;
VAL_TABLE_ Backlit_LED_Status 15 "Unused3" 14 "Unused2" 13 "Unused1" 12 "Night_12" 11 "Night_11" 10 "Night_10" 9 "Night_9" 8 "Night_8" 7 "Night_7" 6 "Night_6" 5 "Night_5" 4 "Night_4" 3 "Night_3" 2 "Night_2" 1 "Night_1" 0 "Off" ;
VAL_TABLE_ Veh_Lock_Status 3 "UNLOCK_DRV" 2 "UNLOCK_ALL" 1 "LOCK_ALL" 0 "LOCK_DBL" ;
VAL_TABLE_ PrkLckCtlMsgTxt_D_Rq 3 "BTSI_DI_3" 2 "BTSI_DI_2" 1 "BTSI_DI_1" 0 "Null_BTSI_DI" ;
VAL_TABLE_ NoShift_Shift 1 "Shift" 0 "NoShift" ;
VAL_TABLE_ CcdMsgTxt_D_RqDsply 15 "Unused8" 14 "Unused7" 13 "Unused6" 12 "Unused5" 11 "Unused4" 10 "Unused3" 9 "Unused2" 8 "Unused1" 7 "Mode_Change_Unavailable" 6 "CCD_Temporarily_Off" 5 "CCD_Service_Required" 4 "Fault" 3 "Sport" 2 "Normal" 1 "Comfort" 0 "No_Mode_Selected" ;
VAL_TABLE_ CrashEvnt_D_Stat 3 "Invalid" 2 "Fuel_Cutoff_Event" 1 "Deploy_Event" 0 "No_Event" ;
VAL_TABLE_ ReducedGuard_D_Stat 3 "NotUsed" 2 "Alarm_On" 1 "Alarm_Off_Previously_On" 0 "Alarm_Off" ;
VAL_TABLE_ HvacPrecondBlwr_D_Rq 15 "NotUsed6" 14 "NotUsed5" 13 "NotUsed4" 12 "NotUsed3" 11 "NotUsed2" 10 "NotUsed1" 9 "Last_User_Setting" 8 "Auto" 7 "Speed7" 6 "Speed6" 5 "Speed5" 4 "Speed4" 3 "Speed3" 2 "Speed2" 1 "Speed1" 0 "Off" ;
VAL_TABLE_ HvacPrecondMode_D_Rq 15 "NotUsed4" 14 "NotUsed3" 13 "NotUsed2" 12 "NotUsed1" 11 "Last_User_Settings" 10 "Auto" 9 "Max_Defrost" 8 "Windshield_Panel_Floor" 7 "Windshield_Panel" 6 "Windshield" 5 "Windshield_Floor" 4 "Floor" 3 "Panel_Floor" 2 "Panel" 1 "MAX_AC" 0 "Off" ;
VAL_TABLE_ ButtonNotPressed 1 "Button_Pressed" 0 "Button_Not_Pressed" ;
VAL_TABLE_ Null_Pressed 1 "Pressed" 0 "Null" ;
VAL_TABLE_ FobComm_D_Stat 3 "NotUsed" 2 "RemEngStartOK" 1 "RemEngStartFail" 0 "Null" ;
VAL_TABLE_ PudLamp_D_Rq 3 "RAMP_DOWN" 2 "RAMP_UP" 1 "ON" 0 "OFF" ;
VAL_TABLE_ WndwGlbl_D_Cmd 7 "NotUsed3" 6 "NotUsed2" 5 "NotUsed1" 4 "GLEARN" 3 "GCLOSE" 2 "GOPEN" 1 "GSTOP" 0 "Null" ;
VAL_TABLE_ LockMsg 7 "MSG7" 6 "MSG6" 5 "MSG5" 4 "MSG4" 3 "MSG3" 2 "MSG2" 1 "MSG1" 0 "NO_WARNING" ;
VAL_TABLE_ ChildLockDisplay 3 "NOT_SUPPORTED" 2 "ERROR" 1 "CHILD_UNLOCK" 0 "CHILD_LOCK" ;
VAL_TABLE_ Null_Lock_Unlock 3 "Not Used" 2 "Unlock" 1 "Lock" 0 "Null" ;
VAL_TABLE_ NotDown_Down 1 "Down" 0 "Not_Down" ;
VAL_TABLE_ NotUp_Up 1 "Up" 0 "Not_Up" ;
VAL_TABLE_ Wiper 15 "NO_DATA_EXISTS" 14 "STALLED" 13 "RESERVED" 12 "AUTO_ADJUST" 11 "COURTESYWIPE" 10 "AUTO_HIGH" 9 "AUTO_LOW" 8 "WASH" 7 "MIST_FLICK" 6 "MAN_HIGH" 5 "MAN_LOW" 4 "MAN_INT_ON" 3 "MAN_INT_OFF" 2 "OFF_MOVING" 1 "AUTO_OFF" 0 "OFF" ;
VAL_TABLE_ Turn_switch 3 "Unused_Treat_As_Off" 2 "Right" 1 "Left" 0 "Off" ;
VAL_TABLE_ PrkLght_D_Stat 3 "Park_Both" 2 "Park_Right" 1 "Park_Left" 0 "Off" ;
VAL_TABLE_ LghtAmb_D_Sns 7 "No_Data_Exists" 6 "Unused2" 5 "Unused1" 4 "Tunnel_Off" 3 "Tunnel_On" 2 "Twilight" 1 "Light" 0 "Dark" ;
VAL_TABLE_ HeadLghtSwtch_D_Stat 3 "Autolamp" 2 "Headlamp" 1 "Parklamp" 0 "Off" ;
VAL_TABLE_ EmgcyBrkLamp_D_Rq 3 "NotUsed" 2 "Active_at_standstill" 1 "Active_at_speed" 0 "Inactive" ;
VAL_TABLE_ OpenPressedFault 3 "Fault" 2 "Unused" 1 "Pressed" 0 "Open" ;
VAL_TABLE_ GrllShtrPos_D_Cmd 15 "Fully_Open" 14 "Position14" 13 "Position13" 12 "Position12" 11 "Position11" 10 "Position10" 9 "Position9" 8 "Position8" 7 "Position7" 6 "Position6" 5 "Position5" 4 "Position4" 3 "Position3" 2 "Position2" 1 "Position1" 0 "Fully_Closed" ;
VAL_TABLE_ LifeCycMde_D_Actl 3 "Transport" 2 "NotUsed" 1 "Factory" 0 "Normal" ;
VAL_TABLE_ TrnMsgTxt_D_Rq 15 "Message_15" 14 "Message_14" 13 "Message_13" 12 "Message_12" 11 "Message_11" 10 "Message_10" 9 "Message_9" 8 "Message_8" 7 "Message_7" 6 "Message_6" 5 "Message_5" 4 "Message_4" 3 "Message_3" 2 "Message_2" 1 "Message_1" 0 "NoMessage" ;
VAL_TABLE_ DieslPrtcRgen_D_Rq 7 "Unused_2" 6 "Unused_1" 5 "Full_Regen_2" 4 "Full_Regen_1" 3 "HeatUp_3" 2 "HeatUp_2" 1 "HeatUp_1" 0 "Normal_Mode_NoRegen" ;
VAL_TABLE_ ClimtHeat_D_Rq 7 "NotUsed4" 6 "NotUsed3" 5 "NotUsed2" 4 "NotUsed1" 3 "Defrost_Defog" 2 "FastTempPullDownHeatingReq" 1 "OpportunisticHeatingReq" 0 "NoHeatingRequest" ;
VAL_TABLE_ TrnCapHlth_Actl 3 "Capacitor_OK" 2 "Degraded_Capacitor" 1 "Capacitor_State_Unknown" 0 "Capacitor_Fault" ;
VAL_TABLE_ TrnSecPrkStat_D_Actl 7 "Faulty" 6 "Fault_Released" 5 "Fault_Latched" 4 "Recouple_in_Progress" 3 "Mechanism_Released" 2 "RTP_in_Progress" 1 "Pending" 0 "Latched" ;
VAL_TABLE_ TrnGear_D_Actl 7 "Fault" 6 "NotUsed" 5 "Manual" 4 "Drive" 3 "Neutral" 2 "Reverse" 1 "Park" 0 "Transition_State" ;
VAL_TABLE_ TrnNtrlTowCmd_D_Actl 3 "NotUsed" 2 "Neutral_Tow_Entry" 1 "Car_Wash_Mode" 0 "Normal_Mode" ;
VAL_TABLE_ TrnValidGear_D_Cnfm 3 "Accept" 2 "Reject" 1 "Internal_Request" 0 "No_Command" ;
VAL_TABLE_ TrnGear_D_RqPt 7 "Fault" 6 "NotUsed" 5 "Manual" 4 "Drive" 3 "Neutral" 2 "Reverse" 1 "Park" 0 "No_Gear" ;
VAL_TABLE_ TrnValidGearRq_D_Stat 3 "Valid_Request" 2 "Valid_Degraded_Request" 1 "Invalid_Request" 0 "No_Request" ;
VAL_TABLE_ NoData_Fault_3FE_3FF 1023 "Fault" 1022 "NoDataExists" ;
VAL_TABLE_ ClimtCool_D_Rq 7 "NotUsed4" 6 "NotUsed3" 5 "NotUsed2" 4 "NotUsed1" 3 "Defrost_Defog" 2 "FastTempPullDownCoolReq" 1 "OpportunisticCoolingReq" 0 "NoCoolingRequest" ;
VAL_TABLE_ HtrnHvilOpen_B_Actl 1 "HVIL_is_Open" 0 "Normal_Operation" ;
VAL_TABLE_ EngFuelCutFull_B_Inhbt 1 "Inhibit_DFSO" 0 "Normal" ;
VAL_TABLE_ EngFuelCutFull_B_Rq 1 "FuelCutRequest" 0 "NormalOperation" ;
VAL_TABLE_ Fault_7FF 2047 "Fault" ;
VAL_TABLE_ EngStopFst_B_Rq 1 "FastEngineShutdown" 0 "NormalOperation" ;
VAL_TABLE_ EngStrtCold_B_Rq 1 "ExtremeColdStart" 0 "NormalStart" ;
VAL_TABLE_ Fault_FFF 4095 "Fault" ;
VAL_TABLE_ PrkBrkMsgTxt_D_Rq 15 "Message15" 14 "Message14" 13 "Message13" 12 "Message12" 11 "Message11" 10 "Message10" 9 "Message9" 8 "Message8" 7 "Message7" 6 "Message6" 5 "Message5" 4 "Message4" 3 "Message3" 2 "Message2" 1 "Message1" 0 "No_Message" ;
VAL_TABLE_ VehStrtStop_D_Rq 3 "NotUsed" 2 "Vehicle_Start_Request" 1 "Vehicle_Stop_Request" 0 "NoRequest" ;
VAL_TABLE_ HvacRec_D_RqMxBatt 15 "NotUsed5" 14 "NotUsed4" 13 "NotUsed3" 12 "NotUsed2" 11 "NotUsed1" 10 "No_Override" 9 "90Percent_RecircMax" 8 "80Percent_RecircMax" 7 "70Percent_RecircMax" 6 "60Percent_RecircMax" 5 "50Percent_RecircMax" 4 "40Percent_RecircMax" 3 "30Percent_RecircMax" 2 "20Percent_RecircMax" 1 "10Percent_RecircMax" 0 "0Percent_RecircFullOpen" ;
VAL_TABLE_ PrkBrkStatus 7 "GeneralFault_MaintenceMode" 6 "ECD_by_Brake_ECU_Active" 5 "EPB_Limphome_Active" 4 "Rear_Caliper_Open" 3 "RWU_By_EPB_Active" 2 "Rear_Caliper_Transition" 1 "Rear_Caliper_Closed" 0 "Not_Supported" ;
VAL_TABLE_ ElLoadCtl_D_Rq 7 "Unused3" 6 "Unused2" 5 "Unused1" 4 "HoldAllDrvrInvisibleLoads" 3 "StdDriverInvisibleLoadsOn" 2 "AllDriverInvisibleLoadsOn" 1 "All_Possible_Loads_Off" 0 "No_Request" ;
VAL_TABLE_ BattTracCool 3 "NotUsed" 2 "DCDC_Overtemperature" 1 "CoolingRequiredbyDCDC" 0 "NoCoolingRequiredbyDCDC" ;
VAL_TABLE_ NotReady_Active_Fault 3 "Fault" 2 "Active" 1 "Ready" 0 "Not_Ready" ;
VAL_TABLE_ Quality_Data 3 "OK" 2 "Not_Within_Specifications" 1 "Eval_In_Progress" 0 "Fault" ;
VAL_TABLE_ PwSrcULoFalt_D_Stat 3 "Fault_No_Output" 2 "Fault_Reduced_Output" 1 "Fault_NonSpecific" 0 "No_Fault" ;
VAL_TABLE_ Connect_Discon_Loose 1 "Loose_or_Disconnected" 0 "Connected" ;
VAL_TABLE_ DontCare_StartInhibit 1 "Start_Inhibit" 0 "Dont_Care" ;
VAL_TABLE_ BattULoChrg_D_Rq 3 "Not_Used" 2 "Charging_Requested" 1 "Chrg_Requested_HighCurrent" 0 "No_Request" ;
VAL_TABLE_ PwSysULoFalt_D_Stat 15 "Not_Used_6" 14 "LowBatterySOC" 13 "PSS_Shed2_Contin" 12 "Not_Used_4" 11 "Not_Used_3" 10 "Not_Used_2" 9 "BattMonitoringSensorFault" 8 "LowBattVoltDuringPwSrcOn" 7 "LowBatt2_PowerSaveMode" 6 "LowBatt1_Warning" 5 "Overvoltage" 4 "Fault_NoOutput" 3 "Fault_ReducedOutput" 2 "Fault_Nonspecific" 1 "Cluster_Proveout" 0 "No_Fault" ;
VAL_TABLE_ AccStopMde_D_Rq 3 "Stop_Mode_Active" 2 "EPBApplyOrBrakeReleaseWarn" 1 "Limit_Rolling_Speed" 0 "Stop_Mode_Not_Active" ;
VAL_TABLE_ EngFuelCutFull_B_Sched 1 "DFSO_Event_Scheduled" 0 "Normal" ;
VAL_TABLE_ Eng_D_Stat 3 "NotUsed" 2 "EngAutoStopped" 1 "EngOn" 0 "EngOff" ;
VAL_TABLE_ ElPw_D_Stat 7 "NotUsed_3" 6 "NotUsed_2" 5 "NotUsed_1" 4 "Fault_Limited" 3 "LV_Event_In_Progress" 2 "Not_Supported_Imminent" 1 "Supported" 0 "Not_Supported" ;
VAL_TABLE_ PwPckTq_D_Stat 3 "PwPckOn_TqAvailable" 2 "StartInPrgrss_TqNotAvail" 1 "PwPckOn_TqNotAvailable" 0 "PwPckOff_TqNotAvailable" ;
VAL_TABLE_ Fault_FF 255 "Fault" ;
VAL_TABLE_ ElCmprOverTe_D_Stat 3 "OverTempStop" 2 "OverTempWarning" 1 "Normal" 0 "Undefined" ;
VAL_TABLE_ Southern_Northern 3 "Fault" 2 "Northern" 1 "Southern" 0 "Invalid" ;
VAL_TABLE_ PsngrFrntDetct_D_Actl 3 "Unknown" 2 "Empty" 0 "Faulty" 1 "Occupied" ;
VAL_TABLE_ Normal_Mode1_2 3 "Undefined" 2 "Mode2" 1 "Mode1" 0 "Normal_Mode" ;
VAL_TABLE_ Fault_3FF 1023 "Fault" ;
VAL_TABLE_ VedsEvnt_6 5 "Unused_3" 4 "Unused_2" 3 "Unused_1" 2 "NotBelted" 1 "Belted" 0 "NoEvent" 7 "Fault" 6 "NotSupported" ;
VAL_TABLE_ VedsEvnt_5 7 "Fault" 6 "NotSupported" 5 "Unused_3" 4 "Unused_2" 3 "Unused_1" 2 "ChildNotDetected" 1 "ChildDetected" 0 "NoEvent" ;
VAL_TABLE_ VedsEvnt_4 7 "Fault" 6 "NotSupported" 5 "Unused_3" 4 "Unused_2" 3 "Unused_1" 2 "NotDeployed" 1 "Deployed" 0 "NoEvent" ;
VAL_TABLE_ VedsEvnt_3 0 "NoEvent" 255 "Fault" 254 "NotSupported" ;
VAL_TABLE_ VedsEvnt_2 7 "Fault" 6 "NotSupported" 5 "Unused_3" 4 "Unused_2" 3 "Unused_1" 2 "Yes" 1 "No" 0 "NoEvent" ;
VAL_TABLE_ VedsEvnt_1 7 "Fault" 6 "NotSupported" 5 "Unused" 4 "Rolllover" 3 "Rear" 2 "Side" 1 "Frontal" 0 "NoEvent" ;
VAL_TABLE_ Fault_F 15 "Fault" ;
VAL_TABLE_ Fault_1F 31 "Fault" ;
VAL_TABLE_ LockInhibit 1 "Inhibit" 0 "No_Inhibit" ;
VAL_TABLE_ DieslFuelBio_B_ActlDrv 1 "Biodiesel_User" 0 "Non_Biodiesel_User" ;
VAL_TABLE_ Invalid_FFF 4095 "Invalid" ;
VAL_TABLE_ Off_0x0 0 "Off" ;
VAL_TABLE_ TrnIpcDsplyRng_D_Actl 7 "Undefined_1" 6 "Range_6" 5 "Range_5" 4 "Range_4" 3 "Range_3" 2 "Range_2" 1 "Range_1" 0 "Undefined" ;
VAL_TABLE_ ParkAid_Chime 15 "Zone15_Chime" 14 "Zone14_Chime" 13 "Zone13_Chime" 12 "Zone12_Chime" 11 "Zone11_Chime" 10 "Zone10_Chime" 9 "Zone9_Chime" 8 "Zone8_Chime" 7 "Zone7_Chime" 6 "Zone6_Chime" 5 "Zone5_Chime" 4 "Zone4_Chime" 3 "Zone3_Chime" 2 "Zone2_Chime" 1 "Zone1_Chime" 0 "No_Chime" ;
VAL_TABLE_ Shed_Feature_Group_ID 14 "HtdMirr" 13 "HvacRearBlwr_Third" 12 "HvacRearBlwr_Second" 11 "HvacRearBlwr_First" 31 "All LSHED1 Features" 10 "Htd_Windscrn" 9 "SpltHtdBcklight_HtdMirr" 8 "HtdBcklight_HtdMirr" 7 "HtdCoolSeat_FrtDriver" 6 "HtdCoolSeat_FrtPass" 5 "HtdCoolSeat_RearPass" 4 "HtdCoolSeat_RearDriver" 3 "SmartTrlrTowBattCharge" 2 "Htd_StrWhl" 1 "Htd_Washer_Fluid" 0 "No_LSHED1_Features" 15 "Engine_Coolant_Fan" ;
VAL_TABLE_ CoolantFanStepAct 31 "Unused7" 30 "Unused6" 29 "Unused5" 28 "Unused4" 27 "Unused3" 26 "Unused2" 25 "Unused1" 23 "Step23" 22 "Step22" 21 "Step21" 20 "Step20" 19 "Step19" 18 "Step18" 17 "Step17" 16 "Step16" 15 "Step15" 14 "Step14" 13 "Step13" 12 "Step12" 11 "Step11" 10 "Step10" 9 "Step9" 8 "Step8" 7 "Step7" 6 "Step6" 5 "Step5" 4 "Step4" 3 "Step3" 2 "Step2" 1 "Step1" 24 "Max_Fan_Speed_Req" 0 "Fan_Cmd_Off" ;
VAL_TABLE_ Veh_Lock_Requestor 31 "Unused8" 30 "Unused7" 29 "Unused6" 28 "Unused5" 27 "Unused4" 26 "Unused3" 25 "Unused2" 24 "Unused1" 23 "Diagnostics" 22 "Console_Lock" 21 "Child_Lock" 20 "Double_Lock" 19 "Passive_Pasenger" 18 "Passive_Driver" 17 "Slam_Lock_Protect" 16 "SYNC" 15 "Passport" 14 "Passive_Smart_Unlock" 13 "Autorelock" 12 "RemoteStart" 0 "Null" 1 "Autolock" 11 "Smart_Unlock" 10 "Sliding_Door" 9 "Passive" 8 "Remote" 7 "Programming" 6 "Powerslide" 5 "Keypad" 4 "Key_Cylinder" 3 "Interior" 2 "Auto_Unlock" ;
VAL_TABLE_ EPAS_FAILURE 3 "SERVICE_POWER_STEERING_NOW" 2 "SERVICE_POWER_STEERING" 1 "POWER_STRG_ASSIST_FAULT" 0 "EPAS_OK_NO_MESSAGE" ;
VAL_TABLE_ Perimeter_Alarm_Mode 3 "Activated" 2 "Armed" 1 "Prearmed" 0 "Disarmed" ;
VAL_TABLE_ Invalid_FFFF 65535 "Invalid" ;
VAL_TABLE_ OilPressureWarning 1 "Low_Pressure_Lamp_On" 0 "Normal_Pressure_Lamp_Off" ;
VAL_TABLE_ MyKey_KeyTypeChangeReq 3 "Search_PE_BackupSlot" 2 "Clear_All_MyKeys" 1 "Request_New_MyKey" 0 "None" ;
VAL_TABLE_ MyKey_Key_Count 13 "Thirteen" 12 "Twelve" 11 "Eleven" 10 "Ten" 9 "Nine" 8 "Eight" 7 "Seven" 6 "Six" 5 "Five" 4 "Four" 3 "Three" 2 "Two" 1 "One" 0 "Zero" 15 "Invalid" 14 "Unlimited" ;
VAL_TABLE_ Shed_Level_Req 7 "Unused_2" 6 "Loads_On" 5 "SHED_ENG_OFF" 4 "SOON_ENG_OFF" 3 "SHED2_CONTIN" 2 "SHED2_TRANS" 1 "SHED1" 0 "NO_SHED" ;
VAL_TABLE_ BpedMove_D_Actl 3 "Unknown" 2 "DriverApplyingBrakePedal" 1 "NoAutonomousBrkPdlMovement" 0 "AutonomousBrkPedalMove" ;
VAL_TABLE_ Eastern_Western 0 "Invalid" 1 "Eastern" 2 "Western" 3 "Fault" ;
VAL_TABLE_ Off_On_Undefined_Fault 3 "Fault" 2 "Undefined" 1 "On" 0 "Off" ;
VAL_TABLE_ Invalid_1FF 511 "Invalid" ;
VAL_TABLE_ ChargeMode 7 "Undefined_2" 6 "Undefined_1" 5 "Battery_Identify" 4 "Battery_Refresh" 3 "SlowRegenAllowNoDischarge" 2 "Fast_Regen_Allowed" 1 "Slow_Regen_Allowed" 0 "Conventional_Charging" ;
VAL_TABLE_ Unknown_FFFE_Invalid_FFFF 65535 "Invalid" 65534 "Unknown" ;
VAL_TABLE_ eCallNotification 3 "Not_Used" 2 "Active" 1 "Normal" 0 "Not_Supported" ;
VAL_TABLE_ eCallConfirmation 7 "Unused_2" 6 "CallComplete_DTMF_Timeout" 5 "eCall_Configured_Off" 4 "Call_Unsuccessful" 3 "Call_Cancelled" 2 "Call_Completed" 1 "Call_In_Progress" 0 "Normal" ;
VAL_TABLE_ RKE_Filter_Ctrl 3 "Streaming" 2 "Filter" 1 "Not_Used" 0 "Null" ;
VAL_TABLE_ SAPPAngleControlStat5 1 "StrgColTorqueExceed_EAROn" 0 "ExternalSigContentOKforEAC" ;
VAL_TABLE_ Closed_Open_Active_Fault 3 "Fault" 2 "Active" 1 "Open" 0 "Closed" ;
VAL_TABLE_ SAPPAngleControlStat2 1 "Rel_ExtSteeringAngleReqx" 0 "NoRel_ExtSteeringAngleReqx" ;
VAL_TABLE_ SAPPAngleControlStat3 1 "EARactiveNoReverseEngage" 0 "ExternalSigContentOKforEAC" ;
VAL_TABLE_ RstrnImpactEvntStatus 7 "Invalid" 6 "Not_Used_4" 5 "Threshold_2_Exceeded" 4 "Not_Used_3" 3 "Threshold_1_Exceeded" 2 "Not_Used_2" 1 "Not_Used_1" 0 "Normal" ;
VAL_TABLE_ EDRTriggerEvntSync 1 "Threshold_Exceeded" 0 "Normal" ;
VAL_TABLE_ EngTeColdPrtct_D_Stats 3 "Undefined" 2 "OK_to_Drive" 1 "Engine_Warning" 0 "Normal_Operation" ;
VAL_TABLE_ HILL_DESC_MC 7 "Fault_Detected" 6 "Cooling_Down" 5 "Abort_Apply_Brakes" 4 "Active" 3 "Disabled" 2 "Enabled" 1 "Off_Road" 0 "Normal" ;
VAL_TABLE_ Closed_Ajar 1 "Ajar" 0 "Closed" ;
VAL_TABLE_ Quality_Factor 3 "OK" 2 "Not_Within_Specifications" 1 "No_Data_Exists" 0 "Faulty" ;
VAL_TABLE_ Null_Day_Night 3 "NotUsed" 2 "Night" 1 "Day" 0 "Null" ;
VAL_TABLE_ Null_Flash_High 3 "NotUsed" 2 "High" 1 "Flash_to_Pass" 0 "Null" ;
VAL_TABLE_ TrnShifMde_D_RqDrv 7 "Undefined" 6 "Tow_Haul_Range_Select" 5 "Overdrive_Cancel" 4 "Tow_haul" 3 "Sport_Tip" 2 "Sport" 1 "Range_Select" 0 "Normal" ;
VAL_TABLE_ GearPos_D_Actl 15 "Unknown" 14 "Reverse" 13 "Undefined_5" 12 "Undefined_4" 11 "Undefined_3" 10 "Undefined_2" 9 "Undefined_1" 8 "Eighth" 7 "Seventh" 6 "Sixth" 5 "Fifth" 4 "Fourth" 3 "Third" 2 "Second" 1 "First" 0 "Neutral" ;
VAL_TABLE_ OffOn_SlowFast_Flash 3 "Fast_Flash" 2 "Slow_Flash" 1 "On" 0 "Off" ;
VAL_TABLE_ AwdStat_D_RqDsply 31 "NotUsed9" 30 "NotUsed8" 29 "NotUsed7" 28 "NotUsed6" 27 "NotUsed5" 26 "NotUsed4" 25 "NotUsed3" 24 "NotUsed2" 23 "Out_of_4Low_Crawl" 22 "AWD_PTU_Oil_Changed" 21 "Change_AWD_PTU_Oil" 20 "Neutral_Tow_Disabled" 19 "Neutral_Tow_Enabled" 18 "AWD_OFF" 17 "_4x4_Off_Road_Speed" 16 "_4x4_Extreme_Off_Road_Mode" 15 "_4x4_Exiting_Off_Road" 14 "_4x4_Off_Road_Mode" 10 "_4x4_Locked_Temporarily" 9 "Shift_In_Progress" 13 "Blocked_Shift_Assist" 12 "_4x4_Auto_Restored" 11 "_4x4_Disabled_Temporarily" 7 "Out_of_4Low__Neutral" 6 "Out_of_4Low__Brake" 5 "Out_of_4Low__Speed" 4 "Into_4Low__Clutch" 3 "Into_4Low__Neutral" 2 "Into_4Low__Brake" 1 "Into_4Low__Speed" 0 "Normal__No_Message" 8 "Out_of_4Low__Clutch" ;
VAL_TABLE_ AngleReached 1 "RequestedAngleNotReached" 0 "RequestedAngleCanBeReached" ;
VAL_TABLE_ WhlDir 3 "Failed" 2 "Unknown" 1 "Backward" 0 "Forward" ;
VAL_TABLE_ VehVLimStat_D_Actl 7 "Undefined_3" 6 "Undefined_2" 5 "Undefined_1" 4 "ASL_Fault_Condition" 3 "Active_and_Limiting" 2 "Active_but_Not_Limiting" 1 "Standby" 0 "Off" ;
VAL_TABLE_ Unknown_Fault_1FE_1FF 511 "Fault" 510 "Unknown" ;
VAL_TABLE_ Fault_NoFault 1 "Fault" 0 "No_Fault" ;
VAL_TABLE_ TrnIpcDsplyMde_D_Actl 7 "Manual_3" 6 "Manual_2" 5 "Manual_1_Low" 4 "Sport" 3 "Drive" 2 "Neutral" 1 "Reverse" 0 "Park" ;
VAL_TABLE_ TrnIpcDsplyMde_D_Stat 3 "Reserved_Blank_No_Display" 2 "Flash" 1 "On" 0 "Blank_No_Display" ;
VAL_TABLE_ TrnIpcDsplyGear_D_Actl 9 "Reserved" 8 "_8th_Gear" 7 "_7th_Gear" 6 "_6th_Gear" 5 "_5th_Gear" 4 "_4th_Gear" 3 "_3rd_Gear" 2 "_2nd_Gear" 1 "_1st_Gear" 0 "Neutral" ;
VAL_TABLE_ Unknown_Fault_7FE_7FF 2047 "Fault" 2046 "Unknown" ;
VAL_TABLE_ TerrMde_D_Actl 7 "Fail_Safe_Default" 6 "Dynamic_Mode" 5 "Rock_Crawl_Mode" 4 "Mud_Ruts_Mode" 3 "Sand_Mode" 2 "Undefined" 1 "Low_Mu_Mode" 0 "Special_Operating_Mode_Off" ;
VAL_TABLE_ TerrMdeChng_D_Rdy 7 "Fault" 6 "Undefined_2" 5 "Undefined_1" 4 "ModeUnavailDrInputRqd" 3 "SpOpModes_NotSupported" 2 "ModeUnavailDynamicCond" 1 "Module_In_Initialization" 0 "Mode_Change_Available" ;
VAL_TABLE_ Unknown_Fault_FFFE_FFFF 65535 "Fault" 65534 "Unknown" ;
VAL_TABLE_ Invalid_FFFFFF 16777215 "Invalid" ;
VAL_TABLE_ AutoParkSpdExitCond 1 "SpeedLimitExceededEAROn" 0 "ExternalSigContentOKforEAC" ;
VAL_TABLE_ EngOilLvlDsply_D_Rq 15 "EngOil_LevelSys_CheckFault" 14 "Reserved_2" 13 "Reserved_1" 12 "Conditions_Unsuitable" 11 "Dipstick_Below_Minimum" 10 "Dipstick_Above_Maximum" 9 "Dipstick_Minimum" 8 "Dipstick_12_5_MinMaxRange" 7 "Dipstick_25_MinMaxRange" 6 "Dipstick_37_5_MinMaxRange" 5 "Dipstick_50_MinMaxRange" 4 "Dipstick_62_5_MinMaxRange" 3 "Dipstick_75_MinMaxRange" 2 "Dipstick_87_5_MinMaxRange" 1 "Dipstick_Maximum_Displayed" 0 "No_Message" ;
VAL_TABLE_ HdcMde_D_Actl 7 "Fault" 6 "Temporarily_Unavailable" 5 "NotEnabled_WrongGearSel" 4 "NotEnabled_SpdLimitExceed" 3 "Active_Braking" 2 "Not_Active_Braking" 1 "Off" 0 "Undefined" ;
VAL_TABLE_ GearLvrPos_D_Actl 15 "Fault" 14 "Unknown_Position" 13 "Undefined_Treat_as__Fault" 12 "Undefined_Treat_as_Fault" 11 "sixth" 10 "fifth" 9 "fourth" 8 "third" 7 "second" 6 "first" 5 "Low" 4 "Sport_DriveSport" 3 "Drive" 2 "Neutral" 1 "Reverse" 0 "Park" ;
VAL_TABLE_ EngTurboMde_D_Actl 3 "Fault" 2 "One_Turbo_Active" 1 "Two_Turbos_Active" 0 "Initializing" ;
VAL_TABLE_ EngPullUpPullDown 15 "Undefined_7" 14 "Undefined_6" 13 "Undefined_5" 12 "Undefined_4" 8 "Force_Pull_Down" 7 "Force_Pull_Up" 6 "PullDown_Inhibit_PullUp" 5 "Inhibit_Change" 4 "Inhibit_Pull_Up" 3 "Pull_Down" 2 "Inhibit_Pull_Down" 1 "Pull_Up" 0 "No_Request" 11 "Undefined_3" 10 "Undefined_2" 9 "Undefined_1" ;
VAL_TABLE_ EngMde_D_Rq 8 "VSC_Sets_Speed_Type_3" 7 "VSC_Sets_Speed_Type_2" 6 "VSC_Sets_Torque_Type_2" 5 "Dependability_Shutdown" 4 "Dependability_Follow" 3 "Start" 2 "VSC_Sets_Torque_Type_1" 1 "VSC_Sets_Speed_Type_1" 0 "Off" 15 "Undefined_7" 14 "Undefined_6" 13 "Undefined_5" 12 "Undefined_4" 11 "Undefined_3" 10 "Undefined_2" 9 "Undefined_1" ;
VAL_TABLE_ DrvHdcMsg_D_Rq 7 "Undefined" 6 "Speed_too_High" 5 "Temporarily_Unavailable" 4 "System_Fault" 3 "Select_Gear" 2 "Off" 1 "On" 0 "No_Message" ;
VAL_TABLE_ CcStat_D_Actl 7 "Undefined_2" 6 "Undefined_1" 5 "Active" 4 "Active_Que_Assist" 3 "Standby" 2 "Standby_Denied" 1 "Denied" 0 "Off" ;
VAL_TABLE_ BpedDrvAppl_D_Actl 3 "_Not_Allowed" 2 "Driver_Braking" 1 "Driver_Not_Braking" 0 "Not_Allowed" ;
VAL_TABLE_ AslIconDsply_D_Rq 3 "Not_Used" 2 "On_Active" 1 "On_Passive" 0 "Off" ;
VAL_TABLE_ Unknown_Fault_3E_3F 63 "Fault" 62 "Unknown" ;
VAL_TABLE_ AccEngStat_D_Actl 7 "Undefined_2" 6 "Undefined_1" 5 "ACCSoonCancel_due_Low_Spd" 4 "Shift_Down_Recommendation" 3 "Shift_Up_Recommendation" 2 "ACCNotAllowedToBeActivated" 1 "ACCStandby_due_Auto_Cancel" 0 "Normal_Operation" ;
VAL_TABLE_ NotPressed_Pressed 1 "Pressed" 0 "Not_Pressed" ;
VAL_TABLE_ TrnGear_D_RqDrv 31 "Fault" 30 "NotUsed_25" 29 "NotUsed_24" 28 "NotUsed_23" 27 "NotUsed_22" 26 "Return_to_Park" 25 "NotUsed_20" 24 "NotUsed_19" 23 "NotUsed_18" 22 "NotUsed_17" 21 "Return_To_Park" 20 "NotUsed_15" 19 "NotUsed_14" 18 "NotUsed_13" 17 "NotUsed_12" 16 "Manual" 15 "Not_Used11" 14 "Not_Used10" 13 "NotUsed_9" 12 "NotUsed_8" 11 "NotUsed_7" 10 "NotUsed_6" 9 "NotUsed_5" 8 "Drive" 7 "NotUsed_4" 6 "NotUsed_3" 5 "NotUsed_2" 4 "Neutral" 3 "NotUsed_1" 2 "Reverse" 1 "Park" 0 "No_Gear" ;
VAL_TABLE_ Open_Close 1 "Close" 0 "Open" ;
VAL_TABLE_ No_Crank_Req 1 "Crank_Request" 0 "No_Crank_Request" ;
VAL_TABLE_ DrvSlipCtlMde_D_Rq 3 "App_Specific_Off_Mode_3" 2 "App_Specific_Off_Mode_2" 1 "App_Specific_Off_Mode_1" 0 "Default_Mode" ;
VAL_TABLE_ NotQuiet_Quiet 1 "Quiet" 0 "Not_Quiet" ;
VAL_TABLE_ Remote_Device_Feedback 7 "Unused3" 6 "Unused2" 5 "Unused1" 4 "Shutdown" 3 "Running" 2 "Starting" 1 "Acknowledge" 0 "Null" ;
VAL_TABLE_ Remote_Start_Req 3 "Not_Used" 2 "Remote_Cancel" 1 "Remote_Start" 0 "No_Request" ;
VAL_TABLE_ Modulation_Ctrl 3 "Unused" 2 "FSK" 1 "ASK_FSK" 0 "ASK" ;
VAL_TABLE_ TrnManShif_D_IndDrv 7 "Undefined_3" 6 "Undefined_2" 5 "Shift_to_Neutral" 4 "Downshift_Recommendation" 3 "Upshift_Warning" 2 "Upshift_Performance" 1 "Upshift_Fuel_Economy" 0 "No_Indication" ;
VAL_TABLE_ Unlock_Lock 1 "Locked" 0 "Unlock" ;
VAL_TABLE_ DieslPrtc_D_RqDsply 7 "Unused_2" 6 "Unused_1" 5 "DPF_SOOT_Level3_Blocked" 4 "DPFSootLvl2_SevereOverload" 3 "DPFRegen_ExhFilterComplete" 2 "DPFRegen_CleanExhFilter" 1 "DPF_Soot_Level1_Overloaded" 0 "DPF_OK_Normal_Operation" ;
VAL_TABLE_ PE_BackupSlot_Status 3 "No_Valid_FOB_In_Slot" 2 "MyKey_FOB_In_Slot" 1 "Standard_FOB_In_Slot" 0 "Null" ;
VAL_TABLE_ Unknown_Fault_FFE_FFF 4095 "Fault" 4094 "Unknown" ;
VAL_TABLE_ Unknown_Fault_1FFE_1FFF 8191 "Fault" 8190 "Unknown" ;
VAL_TABLE_ TrnCnvtClu_D_Actl 3 "Transition_or_Micro_Slip" 2 "Lock_Up_Fixed" 1 "Lock_Up_Slip" 0 "No_Lock_Up" ;
VAL_TABLE_ InhibitNoinhibit 1 "Inhibit" 0 "No_Inibit" ;
VAL_TABLE_ DisableEnable 1 "Enable" 0 "Disable" ;
VAL_TABLE_ Unknown_Fault_7FFE_7FFF 32767 "Fault" 32766 "Unknown" ;
VAL_TABLE_ Litval_values 255 "Invalid" 254 "Unknown" 5 "Day" 4 "Twilight_4" 3 "Twilight_3" 2 "Twilight_2" 1 "Twilight_1" 0 "Night" ;
VAL_TABLE_ Dimming_Lvl 255 "Invalid" 254 "Unknown" 18 "Day_6" 17 "Day_5" 16 "Day_4" 15 "Day_3" 14 "Day_2" 13 "Day_1" 12 "Night_12" 11 "Night_11" 10 "Night_10" 9 "Night_9" 8 "Night_8" 7 "Night_7" 6 "Night_6" 5 "Night_5" 4 "Night_4" 3 "Night_3" 2 "Night_2" 1 "Night_1" 0 "Off" ;
VAL_TABLE_ NotOperating 1 "Operating" 0 "Not_Operating" ;
VAL_TABLE_ NotReady_Ready_Invalid 3 "Invalid" 2 "Not_Used" 1 "Ready" 0 "Not_Ready" ;
VAL_TABLE_ EngPtoMde_D_Actl 7 "Undefined" 6 "Split_Shaft_Stationary" 5 "Not_Used_2" 4 "PTO_Mobile" 3 "Not_Used_1" 2 "PTO_Stationary" 1 "BCP" 0 "Off" ;
VAL_TABLE_ ManRgen_D_Rq 3 "NotUsed2" 2 "NotUsed1" 1 "CustInitManExhFilterClean" 0 "No_Customer_Request" ;
VAL_TABLE_ Remote_Start_Status 3 "Invalid" 2 "Unknown" 1 "Remote" 0 "Null" ;
VAL_TABLE_ Lock_Subld 15 "Unused7" 14 "Unused6" 13 "Unused5" 12 "Unused4" 11 "Unused3" 10 "Unused2" 9 "Unused1" 8 "Customer_8" 7 "Customer_7" 6 "Customer_6" 5 "Customer_5" 4 "Customer_4" 3 "Customer_3" 2 "Customer_2" 1 "Customer_1" 0 "Null" ;
VAL_TABLE_ OFF_ON_Unknown_Invalid 1 "On" 0 "Off" 3 "Invalid" 2 "Unknown" ;
VAL_TABLE_ Brake_Fluid 3 "Invalid" 2 "Unknown" 1 "Low" 0 "OK" ;
VAL_TABLE_ Unknown_Invalid_FE_FF 255 "Invalid" 254 "Unknown" ;
VAL_TABLE_ Invalid_FF 255 "Invalid" ;
VAL_TABLE_ NotLow_Low 1 "Low" 0 "Not_Low" ;
VAL_TABLE_ Disabled_Enabled_Status 2 "Status" 3 "NotUsed" 1 "Enabled" 0 "Disabled" ;
VAL_TABLE_ Key_In_Ignition_Status 1 "In" 0 "Out" ;
VAL_TABLE_ Ignition_Status 0 "Unknown" 1 "Off" 15 "Invalid" 8 "Start" 4 "Run" 2 "Accessory" ;
VAL_TABLE_ Disabled_Enabled_Faulted 3 "Faulted" 2 "Unused" 1 "Enabled" 0 "Disabled" ;
VAL_TABLE_ Unknown_Fault_FE_FF 255 "Fault" 254 "Unknown" ;
VAL_TABLE_ Null_Unlock 1 "Unlock" 0 "Null" ;
VAL_TABLE_ Null_Active 1 "Active" 0 "Null" ;
VAL_TABLE_ HsaStat_D_Actl 7 "Undefined" 6 "Failed" 5 "SlowRelease" 4 "FastRelease" 3 "ActiveBrakePedalReleased" 2 "ActiveBrakePedalPressed" 1 "FindingGradient" 0 "Inactive" ;
VAL_TABLE_ Off_Auto_Manual 3 "Undefined" 2 "Manual" 1 "Automatic" 0 "Off" ;
VAL_TABLE_ HsaStat_D_Dsply 7 "NotUsed3" 6 "NotUsed2" 5 "NotUsed1" 4 "NotAvailable" 3 "SlowReleaseWithChime" 2 "SlowReleaseWithoutChime" 1 "Active" 0 "Inactive" ;
VAL_TABLE_ EngMsgTxt_D_Rq 3 "Undefined_2" 2 "Undefined_1" 1 "Power_Reduced_to_LowerTemp" 0 "No_Message" ;
VAL_TABLE_ PassRstrnInd_Req 3 "ABOnNotIllum_OffNotIllum" 2 "AirbagOnNot_Illum_OffIllum" 1 "AirbagOn_Illum_OffNotIllum" 0 "AirbagOn_Illum_Off_Illum" ;
VAL_TABLE_ GPS_dimension 2 "_3D" 1 "_2D" 0 "No_Fix" ;
VAL_TABLE_ GPS_Compass_dirctn 7 "NorthWest" 6 "West" 5 "SouthWest" 4 "South" 3 "SouthEast" 2 "East" 1 "NorthEast" 0 "North" ;
VAL_TABLE_ GPS_Actual_Infer 1 "Inferred_Position" 0 "Actual_Postition" ;
VAL_TABLE_ DrvHdcWarnInfo_D_Rq 3 "Undefined" 2 "Lamp_On_Continuously" 1 "Lamp_Flashing" 0 "Lamp_Off_Continuously" ;
VAL_TABLE_ DieslPrtcRgen_D_Actl 3 "Undefined" 2 "Regen_Level_2" 1 "Regen_Level_1" 0 "No_regen" ;
VAL_TABLE_ Off_On 1 "On" 0 "Off" ;
VAL_TABLE_ CcMde_D_Actl 7 "TapDownWaiting" 6 "TapUpWaiting" 5 "Resuming_Low" 4 "Resuming_High" 3 "Decelerating" 2 "Accelerating" 1 "Keeping_Speed" 0 "Not_Active" ;
VAL_TABLE_ InactiveActive 1 "Active" 0 "Inactive" ;
VAL_TABLE_ ManRgenTxt_D_RqDsply 7 "NotUsed3" 6 "NotUsed2" 5 "NotUsed1" 4 "Cleaning_Aborted_Stopped" 3 "Cleaning_Completed" 2 "Cleaning_In_Progress" 1 "Cleaning_Allowed" 0 "Cleaning_Not_Allowed" ;
VAL_TABLE_ Fault_FFFF 65535 "Fault" ;
VAL_TABLE_ Fault_7F 127 "Fault" ;
VAL_TABLE_ EngOilLvlWarn_D_Rq 7 "Undefined_3" 6 "Undefined_2" 5 "Undefined_1" 3 "Engine_Oil_High" 2 "Engine_Oil_Critical_Low" 1 "Engine_Oil_Low" 0 "No_Message" 4 "Engine_Oil_Critical_High" ;
VAL_TABLE_ UreaQltySys_D_RqDsply 7 "Undefined" 6 "ZZ_Overrides" 5 "EngineIdled" 4 "Engine_Idle_Upon_Refuel" 3 "SPEED_LIMITED_to_YY_mph" 2 "YY_MPH_MAX_UPON_Restart" 1 "CONTAMINATED_ExhFluid" 0 "NoQualityProblem" ;
VAL_TABLE_ Unknown_Invalid_1E_1F 31 "Invalid" 30 "Unknown" ;
VAL_TABLE_ Unknown_Invalid_3FFE_3FFF 16383 "Invalid" 16382 "Unknown" ;
VAL_TABLE_ NoYes 1 "Yes" 0 "No" ;
VAL_TABLE_ AwdRnge_D_Actl 7 "Unknown" 6 "High_Range_2wd" 5 "High_Range_Auto" 4 "High_Range_Locked" 3 "Neutral" 2 "Low_Range_2wd" 1 "Low_Range_Auto" 0 "Low_Range_Locked" ;
VAL_TABLE_ AwdLck_D_Stat 9 "Undefined" 8 "Under_External_Torque_Ctrl" 7 "Torque_Limited_by_Cmd" 6 "Fully_Locked_by_Cmd" 5 "Disabled" 4 "Warning" 3 "Fault" 2 "Inactive" 1 "Completely_Opened_by_Cmd" 0 "OK" ;
VAL_TABLE_ Unknown_Fault_3FE_3FF 1023 "Fault" 1022 "Unknown" ;
VAL_TABLE_ LockSwStat 3 "Invalid" 2 "Unlock" 1 "Lock" 0 "Null" ;
VAL_TABLE_ Null_Override 1 "Override" 0 "Null" ;
VAL_TABLE_ SAPPErrorCoding 32 "Error_32" 31 "Error_31" 30 "Error_30" 29 "Error_29" 28 "Error_28" 27 "Error_27" 26 "Error_26" 25 "Error_25" 24 "Error_24" 23 "Error_23" 22 "Error_22" 21 "Error_21" 20 "Error_20" 19 "Error_19" 18 "Error_18" 17 "Error_17" 16 "Error_16" 15 "Error_15" 14 "Error_14" 13 "Error_13" 12 "Error_12" 11 "Error_11" 10 "Error_10" 9 "Error_9" 8 "Error_8" 7 "Error_7" 6 "Error_6" 5 "Error_5" 4 "Error_4" 3 "Error_3" 2 "Error_2" 1 "Error_1" 0 "Not_Used" ;
VAL_TABLE_ Off_On_Flash 3 "Not_Used" 2 "Flash" 1 "On" 0 "Off" ;
VAL_TABLE_ immoTargetStatCoding 7 "Unused4" 6 "Unused3" 5 "Unused2" 4 "Unused1" 3 "DISABLED_RESET   " 2 "ENABLED_NONMOTIVE_START" 1 "ENABLED_MOTIVE_START" 0 "DISABLED" ;
VAL_TABLE_ BeltBuckle 3 "Unknown" 2 "Unbelted" 1 "Belted" 0 "Faulty" ;
VAL_TABLE_ RILReqCoding 3 "Not_Used" 2 "Plant_Mode" 1 "On" 0 "Off" ;
VAL_TABLE_ Update_Bit 1 "Fresh_data" 0 "Unchanged_data" ;
VAL_TABLE_ Tire_Pressure_Stat 4 "Alert" 15 "Not_Supported" 3 "Fault" 2 "Low" 1 "Normal" 0 "Unknown" ;
VAL_TABLE_ Tire_Pressure_System2 13 "Training_Complete" 12 "Train_InsideLeftRear_tire" 11 "Train_OutsideLeftRear_tire" 10 "Train_LeftRear_tire" 9 "Train_InsideRtRear_tire" 8 "Train_OutsideRtRear_tire" 7 "Train_RightRear_tire" 14 "Tires_not_trained" 6 "Train_RightFront_tire" 5 "Train_LeftFront_tire" 4 "Systm_Activ_Composite_Stat" 3 "Low_Composite_Stat" 2 "Sensr_Fault_Composite_Stat" 1 "Systm_Fault_Composite_Stat" 0 "Unknown_Composite_Stat" ;
VAL_TABLE_ EONV_CVS_MODE 4 "Ramp_Closed_Value_Position" 3 "Ramp_Open_Value_Position" 2 "Step_Closed_Value_Position" 1 "Step_Open_Value_Position" 0 "Hold_Value_Position" ;
VAL_TABLE_ Unknown_7FFF_7FFE_zzz 32767 "Invalid" 32766 "Unknown" ;
VAL_TABLE_ Turn_Seq 3 "Seq" 2 "On" 1 "Off" 0 "Null" ;
VAL_TABLE_ immoTarget2CmdCoding 7 "Unused4" 6 "Unused3" 5 "Unused2" 4 "Unused1" 3 "TARGET2_IDBLOCK2" 2 "TARGET2_IDBLOCK1" 1 "CHALLENGE" 0 "IDLE" ;
VAL_TABLE_ immoTargetCmdCoding 7 "Unused4" 6 "Unused3" 5 "Unused2" 4 "Unused1" 3 "TARGET1_IDBLOCK2" 2 "TARGET1_IDBLOCK1" 1 "CHALLENGE" 0 "IDLE" ;
VAL_TABLE_ immoSubTargetCmdCoding 7 "Unused3" 6 "Unused2" 5 "ECHO_TARGET1_IDBLOCK2" 4 "Unused1" 3 "RQST_TARGET1_IDBLOCK2" 2 "RQST_TARGET1_IDBLOCK1" 1 "RESPONSE" 0 "IDLE" ;
VAL_TABLE_ immoCtrlCmd2Coding 0 "IDLE" 1 "MOTIVE_START_RQST" 2 "NONMOTIVE_START_RQST" 3 "RQST_TARGET2_IDBLOCK1" 4 "RQST_TARGET2_IDBLOCK2" 5 "Unused" 6 "ECHO_TARGET2_IDBLOCK2" 7 "SHUTDOWN" ;
VAL_TABLE_ immoCtrlCmdCoding 0 "IDLE" 1 "MOTIVE_START_RQST" 2 "NONMOTIVE_START_RQST" 3 "RQST_TARGET1_IDBLOCK1" 4 "RQST_TARGET1_IDBLOCK2" 5 "Unused" 6 "ECHO_TARGET1_IDBLOCK2" 7 "SHUTDOWN" ;
VAL_TABLE_ Invalid_Active_Inactive 3 "Not_Used" 2 "Inactive" 1 "Active" 0 "Invalid" ;
VAL_TABLE_ Rvc_Zoom 7 "Unknown" 6 "Invalid" 5 "Zoom_Level_V" 4 "Zoom_Level_IV" 3 "Zoom_Level_III" 2 "Zoom_Level_II" 1 "Zoom_Level_I" 0 "Off" ;
VAL_TABLE_ NotPark 1 "Park" 0 "Not_Park" ;
VAL_TABLE_ PersOptIn 1 "OPTED_IN" 0 "NOT_OPTED_IN" ;
VAL_TABLE_ PersonalSetUp 3 "Non_Moveable_Person" 2 "Moveable_Person" 1 "Vehicle" 0 "Factory" ;
VAL_TABLE_ Full_Limited 1 "Limited" 0 "Full" ;
VAL_TABLE_ NoConflict_Conflict 1 "Conflict" 0 "No_Conflict" ;
VAL_TABLE_ Assoc_Confirm 0 "None" 7 "Associate" 6 "Keycode_Rejected" 5 "Keycode_Accepted" 4 "In_Progress" 3 "Erase" 2 "Duplicate" 1 "Disassociate" ;
VAL_TABLE_ Check_KeyCode 7 "Unused_2" 6 "Unused_1" 5 "Set_Keycode" 4 "RKE" 3 "Null" 2 "Key" 1 "Erase_KeyCode" 0 "Check_KeyCode" ;
VAL_TABLE_ Complete_Inprogress 3 "Unused" 2 "Null" 1 "InProgress" 0 "Complete" ;
VAL_TABLE_ Null_Pers1_4 7 "Unused_3" 6 "Unused_2" 5 "Unused_1" 4 "PERS_4" 3 "PERS_3" 2 "PERS_2" 1 "PERS_1" 0 "Null" ;
VAL_TABLE_ Pers1_4 7 "Unused_3" 6 "Unused_2" 5 "Unused_1" 4 "Vehicle" 3 "PERS_4" 2 "PERS_3" 1 "PERS_2" 0 "PERS_1" ;
VAL_TABLE_ Null_Query 7 "Unused_2" 6 "Unused_1" 5 "Copy" 4 "Restore" 3 "Upload" 2 "Set" 1 "Query" 0 "Null" ;
VAL_TABLE_ EngExhBrkMde_D_Actl 6 "ExhBrkDisable_NoError" 5 "ExhBrkActive_AUTO" 4 "ExhBrkActive_ON" 3 "ExhBrkRequest_AUTO" 2 "ExhBrkRequest_ON" 1 "ExhBrkNoRequest_OFF" 0 "ExhBrkUnavailable_Error" ;
VAL_TABLE_ UreaLvlTxt_D_RqDsply 11 "System_Error" 10 "Engine_Idled_See_Manual" 9 "Engine_Idled_Upon_Refuel" 8 "Speed_Limited_To_YY_mph" 7 "YYmph_Max_Upon_Restart" 6 "Speed_Limited_To_YY_mph" 5 "YYmph_Max_Upon_Restart" 4 "SpdLimtd_YYmph_In_XXmiles" 3 "ExFlRange_XXMiles_ScndWarn" 2 "Exh_Fluid_Range_XX_Miles" 1 "Exh_Fluid_Under_Half_Full" 0 "Exh_Fluid_Over_Half_Full" ;
VAL_TABLE_ CCOverridden 1 "Cruise_Overridden" 0 "Cruise_Req_Not_Overridden" ;
VAL_TABLE_ Ign_Key_Device_Type 15 "Invalid" 14 "Unknown" 3 "Key_Not_Prgrm_Read_Failure" 2 "Key_In_Ign_My_Key" 1 "Key_In_Ign_Standard_Key" 0 "Key_Read_In_Progress" ;
VAL_TABLE_ Off_No_Eff_Unknown_Invalid 3 "Invalid" 2 "Unknown" 1 "No_Effect" 0 "Off" ;
VAL_TABLE_ Null_Out 1 "Out" 0 "Null" ;
VAL_TABLE_ FUEL_SENSORS 1 "Dual_Sensors" 0 "Single_Sensor" ;

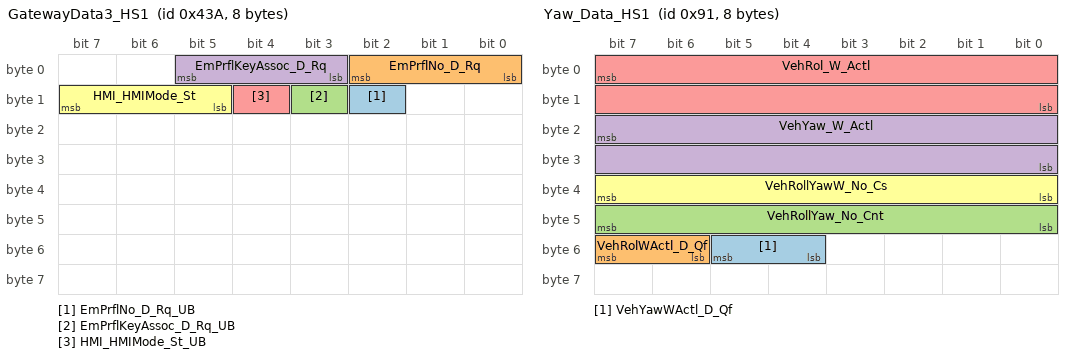
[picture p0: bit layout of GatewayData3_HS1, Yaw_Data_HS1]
BO_ 1082 GatewayData3_HS1: 8 GWM
 SG_ EmPrflNo_D_Rq_UB : 10|1@0+ (1,0) [0|1] "SED"  BCM
 SG_ EmPrflNo_D_Rq : 2|3@0+ (1,0) [0|7] "SED"  BCM
 SG_ EmPrflKeyAssoc_D_Rq_UB : 11|1@0+ (1,0) [0|1] "SED"  BCM
 SG_ EmPrflKeyAssoc_D_Rq : 5|3@0+ (1,0) [0|7] "SED"  BCM
 SG_ HMI_HMIMode_St_UB : 12|1@0+ (1,0) [0|1] "SED"  BCM
 SG_ HMI_HMIMode_St : 15|3@0+ (1,0) [0|7] "SED"  BCM

BO_ 1100 PowertrainData_9: 8 ECM_Diesel
 SG_ GrossTrainWeight_M_Est : 7|8@0+ (100,0) [0|25300] "kilogram"  GWM

BO_ 145 Yaw_Data_HS1: 8 GWM
 SG_ VehYawWActl_D_Qf : 53|2@0+ (1,0) [0|3] "SED" Vector__XXX
 SG_ VehRolWActl_D_Qf : 55|2@0+ (1,0) [0|3] "SED" Vector__XXX
 SG_ VehRollYaw_No_Cnt : 47|8@0+ (1,0) [0|255] "Unitless" Vector__XXX
 SG_ VehYaw_W_Actl : 23|16@0+ (0.0002,-6.5) [-6.5|6.6066] "rad/s"  APIM
 SG_ VehRol_W_Actl : 7|16@0+ (0.0002,-6.5) [-6.5|6.6066] "rad/s" Vector__XXX
 SG_ VehRollYawW_No_Cs : 39|8@0+ (1,0) [0|255] "Unitless" Vector__XXX

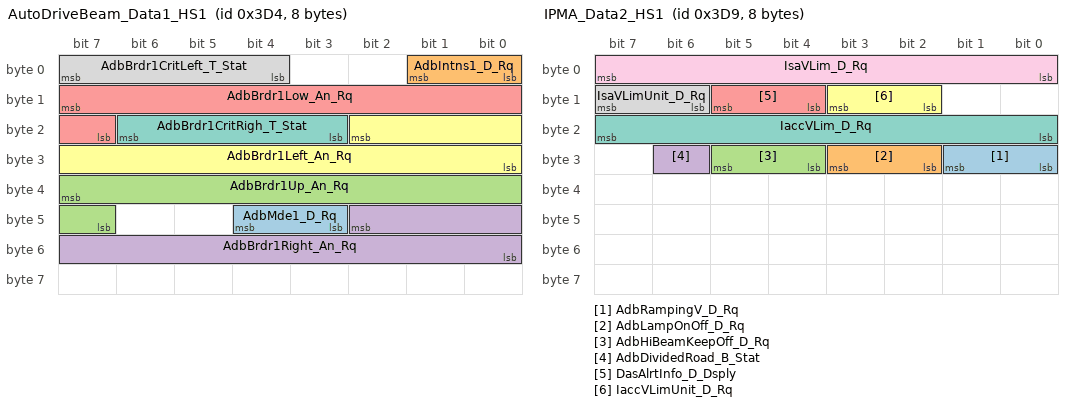
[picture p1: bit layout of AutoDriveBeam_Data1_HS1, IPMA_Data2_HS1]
BO_ 980 AutoDriveBeam_Data1_HS1: 8 GWM
 SG_ AdbMde1_D_Rq : 44|2@0+ (1,0) [0|3] "SED" Vector__XXX
 SG_ AdbIntns1_D_Rq : 1|2@0+ (1,0) [0|3] "SED" Vector__XXX
 SG_ AdbBrdr1Up_An_Rq : 39|9@0+ (0.02,-8) [-8|2.18] "degrees" Vector__XXX
 SG_ AdbBrdr1Right_An_Rq : 42|11@0+ (0.02,-20) [-20|20.9] "degrees" Vector__XXX
 SG_ AdbBrdr1Low_An_Rq : 15|9@0+ (0.02,-8) [-8|2.18] "degrees" Vector__XXX
 SG_ AdbBrdr1Left_An_Rq : 18|11@0+ (0.02,-20) [-20|20.9] "degrees" Vector__XXX
 SG_ AdbBrdr1CritRigh_T_Stat : 22|4@0+ (100,0) [0|1500] "millisecond" Vector__XXX
 SG_ AdbBrdr1CritLeft_T_Stat : 7|4@0+ (100,0) [0|1500] "millisecond" Vector__XXX

BO_ 985 IPMA_Data2_HS1: 8 GWM
 SG_ AdbRampingV_D_Rq : 25|2@0+ (1,0) [0|3] "SED" Vector__XXX
 SG_ AdbLampOnOff_D_Rq : 27|2@0+ (1,0) [0|3] "SED" Vector__XXX
 SG_ AdbHiBeamKeepOff_D_Rq : 29|2@0+ (1,0) [0|3] "SED" Vector__XXX
 SG_ AdbDividedRoad_B_Stat : 30|1@0+ (1,0) [0|1] "SED" Vector__XXX
 SG_ DasAlrtInfo_D_Dsply : 13|2@0+ (1,0) [0|3] "SED" Vector__XXX
 SG_ IaccVLimUnit_D_Rq : 11|2@0+ (1,0) [0|3] "SED" Vector__XXX
 SG_ IaccVLim_D_Rq : 23|8@0+ (1,0) [0|255] "SED" Vector__XXX
 SG_ IsaVLimUnit_D_Rq : 15|2@0+ (1,0) [0|3] "SED" Vector__XXX
 SG_ IsaVLim_D_Rq : 7|8@0+ (1,0) [0|255] "SED" Vector__XXX

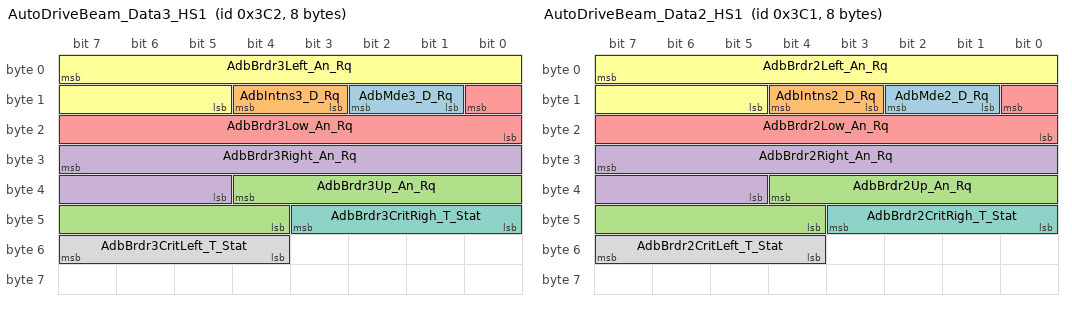
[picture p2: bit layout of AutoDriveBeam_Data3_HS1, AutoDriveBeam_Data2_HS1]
BO_ 962 AutoDriveBeam_Data3_HS1: 8 GWM
 SG_ AdbMde3_D_Rq : 10|2@0+ (1,0) [0|3] "SED" Vector__XXX
 SG_ AdbIntns3_D_Rq : 12|2@0+ (1,0) [0|3] "SED" Vector__XXX
 SG_ AdbBrdr3Up_An_Rq : 36|9@0+ (0.02,-8) [-8|2.18] "degrees" Vector__XXX
 SG_ AdbBrdr3Right_An_Rq : 31|11@0+ (0.02,-20) [-20|20.9] "degrees" Vector__XXX
 SG_ AdbBrdr3Low_An_Rq : 8|9@0+ (0.02,-8) [-8|2.18] "degrees" Vector__XXX
 SG_ AdbBrdr3Left_An_Rq : 7|11@0+ (0.02,-20) [-20|20.9] "degrees" Vector__XXX
 SG_ AdbBrdr3CritRigh_T_Stat : 43|4@0+ (100,0) [0|1500] "millisecond" Vector__XXX
 SG_ AdbBrdr3CritLeft_T_Stat : 55|4@0+ (100,0) [0|1500] "millisecond" Vector__XXX

BO_ 961 AutoDriveBeam_Data2_HS1: 8 GWM
 SG_ AdbMde2_D_Rq : 10|2@0+ (1,0) [0|3] "SED" Vector__XXX
 SG_ AdbIntns2_D_Rq : 12|2@0+ (1,0) [0|3] "SED" Vector__XXX
 SG_ AdbBrdr2Up_An_Rq : 36|9@0+ (0.02,-8) [-8|2.18] "degrees" Vector__XXX
 SG_ AdbBrdr2Right_An_Rq : 31|11@0+ (0.02,-20) [-20|20.9] "degrees" Vector__XXX
 SG_ AdbBrdr2Low_An_Rq : 8|9@0+ (0.02,-8) [-8|2.18] "degrees" Vector__XXX
 SG_ AdbBrdr2Left_An_Rq : 7|11@0+ (0.02,-20) [-20|20.9] "degrees" Vector__XXX
 SG_ AdbBrdr2CritRigh_T_Stat : 43|4@0+ (100,0) [0|1500] "millisecond" Vector__XXX
 SG_ AdbBrdr2CritLeft_T_Stat : 55|4@0+ (100,0) [0|1500] "millisecond" Vector__XXX

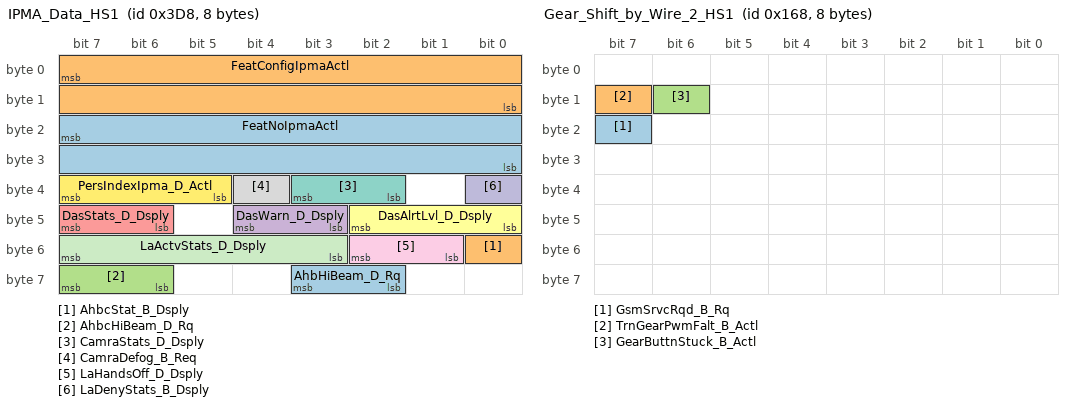
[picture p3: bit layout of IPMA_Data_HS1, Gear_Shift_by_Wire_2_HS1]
BO_ 984 IPMA_Data_HS1: 8 GWM
 SG_ AhbHiBeam_D_Rq : 59|2@0+ (1,0) [0|3] "SED" Vector__XXX
 SG_ AhbcStat_B_Dsply : 48|1@0+ (1,0) [0|1] "SED" Vector__XXX
 SG_ AhbcHiBeam_D_Rq : 63|2@0+ (1,0) [0|3] "SED" Vector__XXX
 SG_ DasWarn_D_Dsply : 44|2@0+ (1,0) [0|3] "SED" Vector__XXX
 SG_ DasStats_D_Dsply : 47|2@0+ (1,0) [0|3] "SED" Vector__XXX
 SG_ DasAlrtLvl_D_Dsply : 42|3@0+ (1,0) [0|7] "SED" Vector__XXX
 SG_ CamraStats_D_Dsply : 35|2@0+ (1,0) [0|3] "SED" Vector__XXX
 SG_ CamraDefog_B_Req : 36|1@0+ (1,0) [0|1] "SED" Vector__XXX
 SG_ LaHandsOff_D_Dsply : 50|2@0+ (1,0) [0|3] "SED" Vector__XXX
 SG_ LaDenyStats_B_Dsply : 32|1@0+ (1,0) [0|1] "SED" Vector__XXX
 SG_ LaActvStats_D_Dsply : 55|5@0+ (1,0) [0|31] "SED" Vector__XXX
 SG_ PersIndexIpma_D_Actl : 39|3@0+ (1,0) [0|7] "SED" Vector__XXX
 SG_ FeatNoIpmaActl : 23|16@0+ (1,0) [0|65535] "Number" Vector__XXX
 SG_ FeatConfigIpmaActl : 7|16@0+ (1,0) [0|65535] "Undefined" Vector__XXX

BO_ 945 Body_Info_7: 8 BCM
 SG_ KeyOffMde_D_Actl : 7|4@0+ (1,0) [0|15] "SED"  GWM

BO_ 523 Engine_Data_18: 8 ECM_Diesel
 SG_ VehUreaRnge3_L_DsplyMx : 31|16@0+ (1,0) [0|65535] "unitless"  GWM

BO_ 360 Gear_Shift_by_Wire_2_HS1: 8 Generic_BCM
 SG_ GsmSrvcRqd_B_Rq : 23|1@0+ (1,0) [0|1] "SED"  TCM,TCM_Diesel
 SG_ TrnGearPwmFalt_B_Actl : 15|1@0+ (1,0) [0|1] "SED"  TCM,TCM_Diesel
 SG_ GearButtnStuck_B_Actl : 14|1@0+ (1,0) [0|1] "SED"  TCM,TCM_Diesel

BO_ 1053 Torque_Request_HS1: 8 GWM
 SG_ VehStab_D_Stat : 23|4@0+ (1,0) [0|15] "SED" Vector__XXX

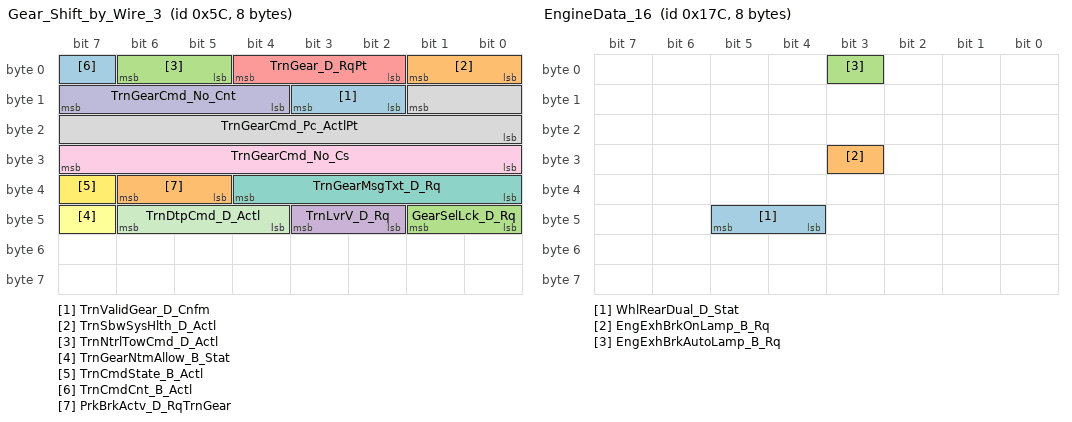
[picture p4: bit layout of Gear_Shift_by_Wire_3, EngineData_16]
BO_ 92 Gear_Shift_by_Wire_3: 8 TCM_Diesel
 SG_ TrnValidGear_D_Cnfm : 11|2@0+ (1,0) [0|3] "SED"  Generic_BCM
 SG_ TrnSbwSysHlth_D_Actl : 1|2@0+ (1,0) [0|3] "SED"  Generic_BCM
 SG_ TrnNtrlTowCmd_D_Actl : 6|2@0+ (1,0) [0|3] "SED"  Generic_BCM
 SG_ TrnLvrV_D_Rq : 43|2@0+ (1,0) [0|3] "SED"  Generic_BCM
 SG_ TrnGear_D_RqPt : 4|3@0+ (1,0) [0|7] "SED"  Generic_BCM
 SG_ TrnGearNtmAllow_B_Stat : 47|1@0+ (1,0) [0|1] "SED"  Generic_BCM
 SG_ TrnGearMsgTxt_D_Rq : 36|5@0+ (1,0) [0|31] "SED"  Generic_BCM
 SG_ TrnGearCmd_Pc_ActlPt : 9|10@0+ (0.1,0) [0|102.2] "percent duty cycle"  Generic_BCM
 SG_ TrnGearCmd_No_Cs : 31|8@0+ (1,0) [0|255] "Unitless"  Generic_BCM
 SG_ TrnGearCmd_No_Cnt : 15|4@0+ (1,0) [0|15] "Unitless"  Generic_BCM
 SG_ TrnDtpCmd_D_Actl : 46|3@0+ (1,0) [0|7] "SED"  Generic_BCM
 SG_ TrnCmdState_B_Actl : 39|1@0+ (1,0) [0|1] "SED"  Generic_BCM
 SG_ TrnCmdCnt_B_Actl : 7|1@0+ (1,0) [0|1] "unitless"  Generic_BCM
 SG_ PrkBrkActv_D_RqTrnGear : 38|2@0+ (1,0) [0|3] "SED"  Generic_BCM
 SG_ GearSelLck_D_Rq : 41|2@0+ (1,0) [0|3] "SED"  Generic_BCM

BO_ 381 EngineData_17: 8 ECM_Diesel
 SG_ WaterInFuel : 52|1@0+ (1,0) [0|1] "SED"  GWM
 SG_ GlowIndication : 51|1@0+ (1,0) [0|1] "SED"  GWM

BO_ 380 EngineData_16: 8 ECM_Diesel
 SG_ WhlRearDual_D_Stat : 45|2@0+ (1,0) [0|3] "SED"  GWM
 SG_ EngExhBrkOnLamp_B_Rq : 27|1@0+ (1,0) [0|1] "SED"  GWM
 SG_ EngExhBrkAutoLamp_B_Rq : 3|1@0+ (1,0) [0|1] "SED"  GWM

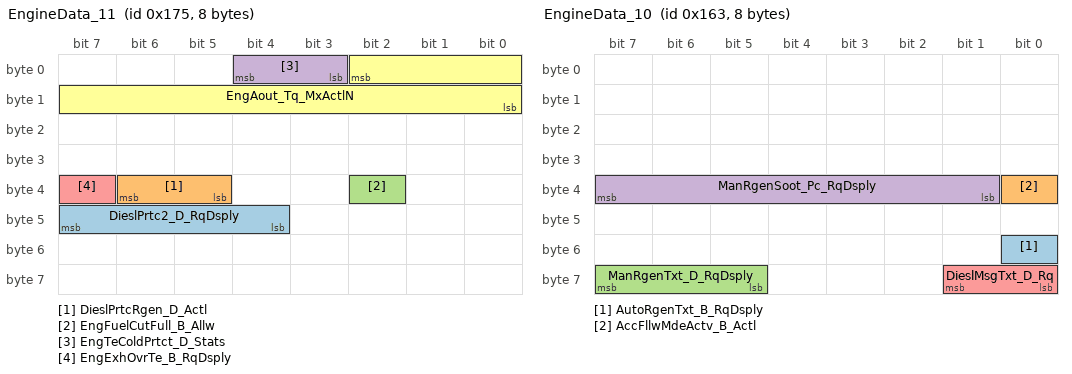
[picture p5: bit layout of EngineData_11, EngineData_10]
BO_ 373 EngineData_11: 8 ECM_Diesel
 SG_ DieslPrtc2_D_RqDsply : 47|4@0+ (1,0) [0|15] "SED"  GWM
 SG_ DieslPrtcRgen_D_Actl : 38|2@0+ (1,0) [0|3] "SED"  GWM
 SG_ EngFuelCutFull_B_Allw : 34|1@0+ (1,0) [0|1] "SED"  GWM
 SG_ EngTeColdPrtct_D_Stats : 4|2@0+ (1,0) [0|3] "SED"  GWM
 SG_ EngExhOvrTe_B_RqDsply : 39|1@0+ (1,0) [0|1] "SED"  GWM
 SG_ EngAout_Tq_MxActlN : 2|11@0+ (1,-500) [-500|1547] "Nm"  GWM

BO_ 355 EngineData_10: 8 ECM_Diesel
 SG_ AutoRgenTxt_B_RqDsply : 48|1@0+ (1,0) [0|1] "SED"  GWM
 SG_ AccFllwMdeActv_B_Actl : 32|1@0+ (1,0) [0|1] "SED"  GWM
 SG_ ManRgenTxt_D_RqDsply : 63|3@0+ (1,0) [0|7] "SED"  GWM
 SG_ ManRgenSoot_Pc_RqDsply : 39|7@0+ (1,0) [0|126] "%"  GWM
 SG_ DieslMsgTxt_D_Rq : 57|2@0+ (1,0) [0|3] "SED"  GWM

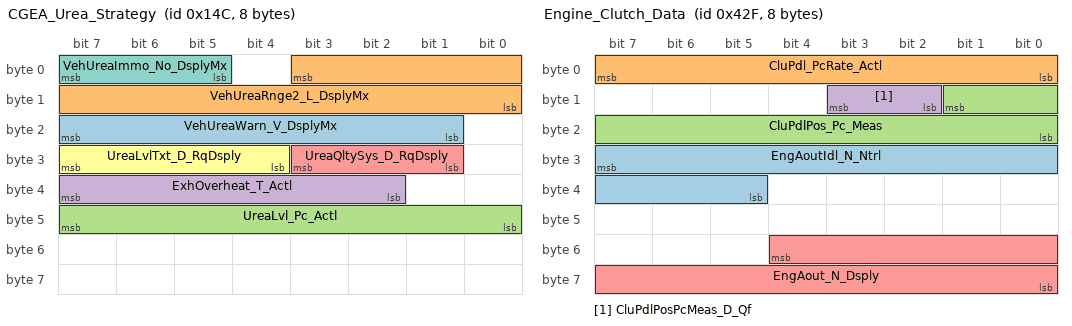
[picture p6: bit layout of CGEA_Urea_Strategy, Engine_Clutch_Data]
BO_ 332 CGEA_Urea_Strategy: 8 ECM_Diesel
 SG_ VehUreaWarn_V_DsplyMx : 23|7@0+ (1,0) [0|127] "km/h"  GWM
 SG_ VehUreaRnge2_L_DsplyMx : 3|12@0+ (1,0) [0|4095] "km"  GWM
 SG_ UreaLvl_Pc_Actl : 47|8@0+ (0.4,0) [0|102] "percent"  GWM
 SG_ ExhOverheat_T_Actl : 39|6@0+ (1,0) [0|63] "minute"  GWM
 SG_ UreaQltySys_D_RqDsply : 27|3@0+ (1,0) [0|7] "SED"  GWM
 SG_ UreaLvlTxt_D_RqDsply : 31|4@0+ (1,0) [0|15] "SED"  GWM
 SG_ VehUreaImmo_No_DsplyMx : 7|3@0+ (1,0) [0|7] "Counts"  GWM

BO_ 1827 TesterPhysicalReqBECMB_EPM: 8 TSTR
 SG_ TesterPhysicalReqBECMB_EPM : 7|64@0+ (1,0) [0|1.84467E+019] "unitless"  BECMB_EPM

BO_ 1458 BECMB_AutoSar_Network_Mgmt: 8 BECMB_EPM
 SG_ BECMB_AutoSar_Network_Mgmt : 7|64@0+ (1,0) [0|1.844674407371E+019] "unitless"  TCM_Diesel,APIM,BCM,ECM,PCM,TCM

BO_ 1110 Power_Stat: 8 BECMB_EPM
 SG_ RstrnMdulePw_D_Falt : 7|2@0+ (1,0) [0|3] "SED"  GWM

BO_ 1835 TesterPhysicalResBECMB_EPM: 8 BECMB_EPM
 SG_ TesterPhysicalResBECMB_EPM : 7|64@0+ (1,0) [0|1.84467E+019] "unitless"  TSTR

BO_ 1071 Engine_Clutch_Data: 8 ECM
 SG_ EngAoutIdl_N_Ntrl : 31|11@0+ (2,0) [0|4094] "rpm"  GWM
 SG_ CluPdl_PcRate_Actl : 7|8@0+ (0.04,-5) [-5|5.2] "%/ms"  GWM
 SG_ CluPdlPos_Pc_Meas : 9|10@0+ (0.1,0) [0|102.3] "%"  GWM
 SG_ CluPdlPosPcMeas_D_Qf : 11|2@0+ (1,0) [0|3] "SED"  GWM
 SG_ EngAout_N_Dsply : 52|13@0+ (2,0) [0|16382] "rpm"  GWM

BO_ 2017 TesterPhysicalReqTCM: 8 TSTR
 SG_ TesterPhysicalReqTCM : 7|64@0+ (1,0) [0|1.84467E+019] "unitless"  TCM_Diesel,TCM

BO_ 2025 TesterPhysicalResTCM: 8 TCM
 SG_ TesterPhysicalResTCM : 7|64@0+ (1,0) [0|1.84467E+019] "unitless"  TSTR

BO_ 1701 TCM_Rapid_Data_Response_2: 8 TCM
 SG_ UUDTTCMResponse2 : 7|64@0+ (1,0) [0|1.844674407371E+019] "unitless"  TSTR

BO_ 1700 TCM_Rapid_Data_Response_1: 8 TCM
 SG_ UUDTTCMResponse1 : 7|64@0+ (1,0) [0|1.844674407371E+019] "unitless"  TSTR

BO_ 561 TransGearData_2: 8 TCM
 SG_ TrnMsgTxt2_D_Rq : 39|3@0+ (1,0) [0|7] "SED"  GWM
 SG_ TrnMsgTxt_D_Rq : 23|4@0+ (1,0) [0|15] "SED"  GWM

BO_ 370 TransData_2: 8 TCM
 SG_ GearPos_D_Actl : 55|4@0+ (1,0) [0|15] "SED"  GWM

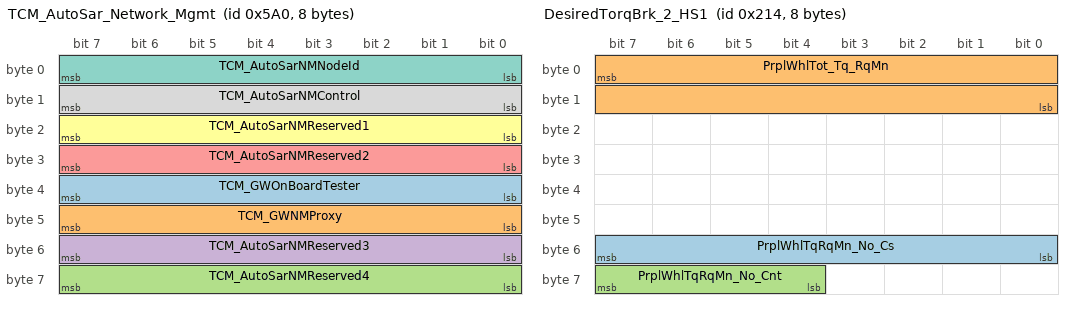
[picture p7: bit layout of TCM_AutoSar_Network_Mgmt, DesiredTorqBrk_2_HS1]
BO_ 1440 TCM_AutoSar_Network_Mgmt: 8 TCM
 SG_ TCM_GWOnBoardTester : 39|8@0+ (1,0) [0|255] "unitless"  APIM,BCM,ECM,GWM,BECMB_EPM
 SG_ TCM_GWNMProxy : 47|8@0+ (1,0) [0|255] "unitless"  APIM,BCM,ECM,GWM,BECMB_EPM
 SG_ TCM_AutoSarNMReserved4 : 63|8@0+ (1,0) [0|255] "unitless"  APIM,BCM,ECM,GWM,BECMB_EPM
 SG_ TCM_AutoSarNMReserved3 : 55|8@0+ (1,0) [0|255] "unitless"  APIM,BCM,ECM,GWM,BECMB_EPM
 SG_ TCM_AutoSarNMReserved2 : 31|8@0+ (1,0) [0|255] "unitless"  APIM,BCM,ECM,GWM,BECMB_EPM
 SG_ TCM_AutoSarNMReserved1 : 23|8@0+ (1,0) [0|255] "unitless"  APIM,BCM,ECM,GWM,BECMB_EPM
 SG_ TCM_AutoSarNMNodeId : 7|8@0+ (1,0) [0|255] "unitless"  APIM,BCM,ECM,GWM,BECMB_EPM
 SG_ TCM_AutoSarNMControl : 15|8@0+ (1,0) [0|255] "unitless"  GWM,APIM,BCM,ECM,BECMB_EPM

BO_ 330 TransData_3: 8 TCM
 SG_ TrnAout_W_ActlUnfilt : 22|15@0+ (0.1,0) [0|3276.5] "rad/s"  ECM_Diesel,GWM,ECM

BO_ 532 DesiredTorqBrk_2_HS1: 8 GWM
 SG_ PrplWhlTqRqMn_No_Cs : 55|8@0+ (1,0) [0|255] "Unitless"  ECM_Diesel,ECM,PCM
 SG_ PrplWhlTot_Tq_RqMn : 7|16@0+ (4,-131072) [-131072|131068] "Nm"  ECM_Diesel,ECM,PCM
 SG_ PrplWhlTqRqMn_No_Cnt : 63|4@0+ (1,0) [0|15] "Unitless"  ECM_Diesel,ECM,PCM

BO_ 1060 Powertrain_Data_4: 8 PCM
 SG_ SelDrvMdePt_D_Stat : 25|2@0+ (1,0) [0|3] "SED"  GWM
 SG_ BpedDrvMsgTxt_B_Dsply : 0|1@0+ (1,0) [0|1] "SED"  GWM

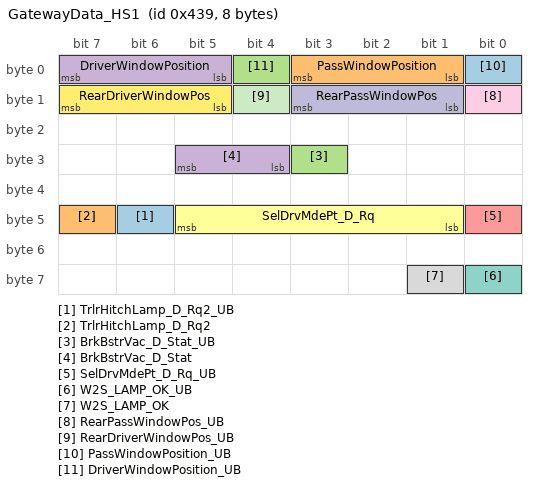
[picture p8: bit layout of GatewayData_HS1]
BO_ 1081 GatewayData_HS1: 8 GWM
 SG_ TrlrHitchLamp_D_Rq2_UB : 46|1@0+ (1,0) [0|1] "SED"  BCM
 SG_ TrlrHitchLamp_D_Rq2 : 47|1@0+ (1,0) [0|1] "SED"  BCM
 SG_ BrkBstrVac_D_Stat_UB : 27|1@0+ (1,0) [0|1] "SED" Vector__XXX
 SG_ BrkBstrVac_D_Stat : 29|2@0+ (1,0) [0|3] "SED" Vector__XXX
 SG_ SelDrvMdePt_D_Rq_UB : 40|1@0+ (1,0) [0|1] "SED"  ECM_Diesel,ECM,PCM
 SG_ SelDrvMdePt_D_Rq : 45|5@0+ (1,0) [0|31] "SED"  ECM_Diesel,ECM,PCM
 SG_ W2S_LAMP_OK_UB : 56|1@0+ (1,0) [0|1] "SED"  ECM_Diesel
 SG_ W2S_LAMP_OK : 57|1@0+ (1,0) [0|1] "SED"  ECM_Diesel
 SG_ RearPassWindowPos_UB : 8|1@0+ (1,0) [0|1] "SED"  BCM
 SG_ RearPassWindowPos : 11|3@0+ (1,0) [0|7] "SED"  BCM
 SG_ RearDriverWindowPos_UB : 12|1@0+ (1,0) [0|1] "SED"  BCM
 SG_ RearDriverWindowPos : 15|3@0+ (1,0) [0|7] "SED"  BCM
 SG_ PassWindowPosition_UB : 0|1@0+ (1,0) [0|1] "SED"  BCM
 SG_ PassWindowPosition : 3|3@0+ (1,0) [0|7] "SED"  BCM
 SG_ DriverWindowPosition_UB : 4|1@0+ (1,0) [0|1] "SED"  BCM
 SG_ DriverWindowPosition : 7|3@0+ (1,0) [0|7] "SED"  BCM

BO_TX_BU_ 92 : TCM,TCM_Diesel;
BO_TX_BU_ 1071 : ECM_Diesel,PCM,ECM;
BO_TX_BU_ 2025 : TCM_Diesel,TCM;
BO_TX_BU_ 1701 : TCM_Diesel,TCM;
BO_TX_BU_ 1700 : TCM_Diesel,TCM;
BO_TX_BU_ 561 : TCM_Diesel,TCM;
BO_TX_BU_ 370 : TCM_Diesel,TCM;
BO_TX_BU_ 1440 : TCM_Diesel,TCM;
BO_TX_BU_ 330 : TCM_Diesel,TCM;
BO_TX_BU_ 1060 : ECM,ECM_Diesel,PCM;

CM_ BU_ BECMB_EPM "EPM (Extended Power Module) ";
CM_ BU_ TCM "Transmission Control Module";
CM_ BU_ ECM "Diesel PCM";
CM_ BU_ GWM "Gateway Module CGEA1.3(Star Architecture)";
CM_ BU_ APIM "Accessory Protocol Interface Module, also known as MGM (Multimedia Gateway Module)
Note: Using CPM node id, Must be updated to GMRDB id's in 2007' (5/1/07)";
CM_ BU_ BCM "Body Ctrl. Mod., Smart Junction Box, SPDJB, GEM(Generic Electronic Mod.)";
CM_ BU_ DCDC_VQM "DC-DC Converter Ctrl. Mod. VSM Voltage Stability Mod.   Europe uses this module and it is called VQM.";
CM_ BU_ PAM "Parking Assist Control Module";
CM_ BU_ TSTR "Diagnostic Tester";
CM_ BU_ PCM "Powertrain Control Module";
CM_ SG_ 1082 HMI_HMIMode_St "Object ACU System Master.HMIMode
OR
Object NAV System Master.HMIMode

Refer Method HMIAudioMode in the SPSS";
CM_ SG_ 145 VehYaw_W_Actl "CCMGenSigTimeoutTime=1000";
CM_ SG_ 360 GsmSrvcRqd_B_Rq "Signal not transmitted on vehicles that do not have shift by wire.";
CM_ SG_ 360 TrnGearPwmFalt_B_Actl "Signal not transmitted on vehicles that do not have shift by wire.";
CM_ SG_ 360 GearButtnStuck_B_Actl "Signal not transmitted on vehicles that do not have shift by wire.";
CM_ SG_ 92 TrnValidGear_D_Cnfm "Signal not transmitted on vehicles that do not have shift by wire.";
CM_ SG_ 92 TrnSbwSysHlth_D_Actl "Signal not transmitted on vehicles that do not have shift by wire.";
CM_ SG_ 92 TrnNtrlTowCmd_D_Actl "Signal not transmitted on vehicles that do not have shift by wire.";
CM_ SG_ 92 TrnGear_D_RqPt "Signal not transmitted on vehicles that do not have shift by wire.";
CM_ SG_ 92 TrnGearNtmAllow_B_Stat "Signal not transmitted on vehicles that do not have shift by wire.";
CM_ SG_ 92 TrnGearMsgTxt_D_Rq "Signal not transmitted on vehicles that do not have shift by wire.";
CM_ SG_ 92 TrnGearCmd_Pc_ActlPt "Signal not transmitted on vehicles that do not have shift by wire.";
CM_ SG_ 92 TrnGearCmd_No_Cs "Signal not transmitted on vehicles that do not have shift by wire.";
CM_ SG_ 92 TrnGearCmd_No_Cnt "Signal not transmitted on vehicles that do not have shift by wire.";
CM_ SG_ 92 TrnDtpCmd_D_Actl "Signal not transmitted on vehicles that do not have shift by wire.";
CM_ SG_ 92 TrnCmdState_B_Actl "Signal not transmitted on vehicles that do not have shift by wire.";
CM_ SG_ 92 TrnCmdCnt_B_Actl "Signal not transmitted on vehicles that do not have shift by wire.";
CM_ SG_ 92 PrkBrkActv_D_RqTrnGear "Signal not transmitted on vehicles that do not have shift by wire.";
CM_ SG_ 373 EngFuelCutFull_B_Allw "Signal not transmitted on diesel variances.";
CM_ SG_ 373 EngAout_Tq_MxActlN "Signal not transmitted on diesel variances.";
CM_ SG_ 1071 EngAoutIdl_N_Ntrl "Signal Listed as Tx by ECM_D on P552
";
CM_ SG_ 1071 CluPdl_PcRate_Actl "Signal only transmitted by ECM_Diesel on P552";
CM_ SG_ 1071 CluPdlPos_Pc_Meas "Signal only transmitted by ECM_Diesel on P552.";
CM_ SG_ 1071 CluPdlPosPcMeas_D_Qf "Signal only transmitted by ECM_Diesel on P552
";
CM_ BO_ 532 "IC is NOT to use data in this message for displays, Used data from 415 instead.";
BA_DEF_ SG_  "U_UP375_MY19_Gas_Rx" ENUM  "No","Yes";
BA_DEF_ SG_  "U_UP375_MY19_Diesel_Rx" ENUM  "No","Yes";
BA_DEF_ SG_  "U_D568C_MY19_Gas_Rx" ENUM  "No","Yes";
BA_DEF_ SG_  "U_CD4_MY19_Diesel_Rx" ENUM  "No","Yes";
BA_DEF_ SG_  "U_CD4_MY19_Gas_Rx" ENUM  "No","Yes";
BA_DEF_ SG_  "U_CD4_MY19_Hev_Rx" ENUM  "No","Yes";
BA_DEF_ SG_  "U_CD4_MY19_Phev_Rx" ENUM  "No","Yes";
BA_DEF_ SG_  "U_V36X_MY19_Rx" ENUM  "No","Yes";
BA_DEF_ SG_  "U_UP375_MY19_Diesel_Tx" ENUM  "No","Yes";
BA_DEF_ SG_  "U_D568C_MY19_Gas_Tx" ENUM  "No","Yes";
BA_DEF_ SG_  "U_CD4_MY19_Diesel_Tx" ENUM  "No","Yes";
BA_DEF_ SG_  "U_CD4_MY19_Gas_Tx" ENUM  "No","Yes";
BA_DEF_ SG_  "U_CD4_MY19_Hev_Tx" ENUM  "No","Yes";
BA_DEF_ SG_  "U_CD4_MY19_Phev_Tx" ENUM  "No","Yes";
BA_DEF_ SG_  "U_V36X_MY19_Tx" ENUM  "No","Yes";
BA_DEF_ SG_  "GenSigTimeoutTime_ECM_HEVDSL" INT 0 100000;
BA_DEF_ SG_  "GenSigTimeoutTime_GFM2_DCGM" INT 0 100000;
BA_DEF_ SG_  "MetaData" ENUM  "No","Yes";
BA_DEF_ SG_  "U_UP375_MY18_Gas_Rx" ENUM  "No","Yes";
BA_DEF_ SG_  "U_UP375_MY18_Diesel_Rx" ENUM  "No","Yes";
BA_DEF_ SG_  "U_V36X_MY18_5_Gas_Rx" ENUM  "No","Yes";
BA_DEF_ SG_  "U_V36X_MY18_5_Hev_Rx" ENUM  "No","Yes";
BA_DEF_ SG_  "U_V36X_MY18_5_Gas_Tx" ENUM  "No","Yes";
BA_DEF_ SG_  "U_V36X_MY18_5_Hev_Tx" ENUM  "No","Yes";
BA_DEF_ SG_  "U_V36X_MY19_5_Diesel_Rx" ENUM  "No","Yes";
BA_DEF_ SG_  "U_V363E_N_MY19_5_20_Gas_Rx" ENUM  "No","Yes";
BA_DEF_ SG_  "U_V363E_N_MY19_5_20_Diesel_Rx" ENUM  "No","Yes";
BA_DEF_ SG_  "U_CD42_MY19_Diesel_Rx" ENUM  "No","Yes";
BA_DEF_ SG_  "U_V36X_MY19_5_Diesel_Tx" ENUM  "No","Yes";
BA_DEF_ SG_  "U_V363E_N_MY19_5_20_Gas_Tx" ENUM  "No","Yes";
BA_DEF_ SG_  "U_V363E_N_MY19_5_20_Diesel_Tx" ENUM  "No","Yes";
BA_DEF_ SG_  "U_CD42_MY19_Diesel_Tx" ENUM  "No","Yes";
BA_DEF_ SG_  "U_CD42_MY19_Gas_Tx" ENUM  "No","Yes";
BA_DEF_ SG_  "GenSigTimeoutTime_AWD_DLCM" INT 0 100000;
BA_DEF_ SG_  "U_U502_MY17_Gas_Rx" ENUM  "No","Yes";
BA_DEF_ SG_  "U_CD4_MY18_Diesel_Rx" ENUM  "No","Yes";
BA_DEF_ SG_  "U_CD4_MY18_Gas_Rx" ENUM  "No","Yes";
BA_DEF_ SG_  "U_CD4_MY18_Hev_Rx" ENUM  "No","Yes";
BA_DEF_ SG_  "U_CD4_MY18_Phev_Rx" ENUM  "No","Yes";
BA_DEF_ SG_  "U_S550_MY18_Gas_Rx" ENUM  "No","Yes";
BA_DEF_ SG_  "U_V408_MY18_Gas_Rx" ENUM  "No","Yes";
BA_DEF_ SG_  "U_V408_MY18_Diesel_Rx" ENUM  "No","Yes";
BA_DEF_ SG_  "U_V36X_MY18_5_Diesel_Rx" ENUM  "No","Yes";
BA_DEF_ SG_  "U_P552_MY18_5_Gas_Rx" ENUM  "No","Yes";
BA_DEF_ SG_  "U_P552_MY18_5_Diesel_Rx" ENUM  "No","Yes";
BA_DEF_ SG_  "U_U502_MY17_Gas_Tx" ENUM  "No","Yes";
BA_DEF_ SG_  "U_CD4_MY18_Diesel_Tx" ENUM  "No","Yes";
BA_DEF_ SG_  "U_CD4_MY18_Gas_Tx" ENUM  "No","Yes";
BA_DEF_ SG_  "U_CD4_MY18_Hev_Tx" ENUM  "No","Yes";
BA_DEF_ SG_  "U_CD4_MY18_Phev_Tx" ENUM  "No","Yes";
BA_DEF_ SG_  "U_S550_MY18_Gas_Tx" ENUM  "No","Yes";
BA_DEF_ SG_  "U_V408_MY18_Gas_Tx" ENUM  "No","Yes";
BA_DEF_ SG_  "U_V408_MY18_Diesel_Tx" ENUM  "No","Yes";
BA_DEF_ SG_  "U_V36X_MY18_5_Diesel_Tx" ENUM  "No","Yes";
BA_DEF_ SG_  "U_P552_MY18_5_Gas_Tx" ENUM  "No","Yes";
BA_DEF_ SG_  "U_P552_MY18_5_Diesel_Tx" ENUM  "No","Yes";
BA_DEF_ SG_  "GenSigTimeoutTime_ECM_Diesel" INT 0 100000;
BA_DEF_ SG_  "GenSigTimeoutTime_DCMR_ELSD" INT 0 100000;
BA_DEF_ SG_  "GenSigTimeoutTime_TCM_Diesel" INT 0 100000;
BA_DEF_ SG_  "U_P552_MY18_Gas_Rx" ENUM  "No","Yes";
BA_DEF_ SG_  "U_U55x_MY18_Gas_Rx" ENUM  "No","Yes";
BA_DEF_ SG_  "U_P552_MY18_Gas_Tx" ENUM  "No","Yes";
BA_DEF_ SG_  "U_U55x_MY18_Gas_Tx" ENUM  "No","Yes";
BA_DEF_ BO_  "FrameGatewayNetwork" STRING ;
BA_DEF_ SG_  "U_C489_MY17_Gas_Rx" ENUM  "No","Yes";
BA_DEF_ SG_  "U_CD43_MY17_Gas_Rx" ENUM  "No","Yes";
BA_DEF_ SG_  "U_P552_MY17_Gas_Rx" ENUM  "No","Yes";
BA_DEF_ SG_  "U_B515_MCA_MY17_Diesel_Rx" ENUM  "No","Yes";
BA_DEF_ SG_  "U_B515_MCA_MY17_Gas_Rx" ENUM  "No","Yes";
BA_DEF_ SG_  "U_C489_MY17_Gas_Tx" ENUM  "No","Yes";
BA_DEF_ SG_  "U_CD43_MY17_Gas_Tx" ENUM  "No","Yes";
BA_DEF_ SG_  "U_P552_MY17_Gas_Tx" ENUM  "No","Yes";
BA_DEF_ SG_  "U_B515_MCA_MY17_Diesel_Tx" ENUM  "No","Yes";
BA_DEF_ SG_  "U_B515_MCA_MY17_Gas_Tx" ENUM  "No","Yes";
BA_DEF_ SG_  "GenSigTimeoutTime_SOBDMD_AHCM_P" INT 0 100000;
BA_DEF_ SG_  "GenSigTimeoutTime_PACM" INT 0 100000;
BA_DEF_ SG_  "GenSigTimeoutTime_BECMB_EPM" INT 0 100000;
BA_DEF_ SG_  "U_B562LC_MY15_Diesel_Rx" ENUM  "No","Yes";
BA_DEF_ SG_  "U_B562LC_MY15_Gas_Rx" ENUM  "No","Yes";
BA_DEF_ SG_  "U_B479_MY17_Gas_Rx" ENUM  "No","Yes";
BA_DEF_ SG_  "U_CD4_MY17_Diesel_Rx" ENUM  "No","Yes";
BA_DEF_ SG_  "U_CD4_MY17_Gas_Rx" ENUM  "No","Yes";
BA_DEF_ SG_  "U_CD4_MY17_Hev_Rx" ENUM  "No","Yes";
BA_DEF_ SG_  "U_CD4_MY17_Phev_Rx" ENUM  "No","Yes";
BA_DEF_ SG_  "U_C489_MY16_Gas_Rx" ENUM  "No","Yes";
BA_DEF_ SG_  "U_CD42_MY16_Diesel_Rx" ENUM  "No","Yes";
BA_DEF_ SG_  "U_CD42_MY16_Gas_Rx" ENUM  "No","Yes";
BA_DEF_ SG_  "U_B562LC_MY15_Diesel_Tx" ENUM  "No","Yes";
BA_DEF_ SG_  "U_B562LC_MY15_Gas_Tx" ENUM  "No","Yes";
BA_DEF_ SG_  "U_CD4_MY17_Diesel_Tx" ENUM  "No","Yes";
BA_DEF_ SG_  "U_CD4_MY17_Gas_Tx" ENUM  "No","Yes";
BA_DEF_ SG_  "U_CD4_MY17_Hev_Tx" ENUM  "No","Yes";
BA_DEF_ SG_  "U_CD4_MY17_Phev_Tx" ENUM  "No","Yes";
BA_DEF_ SG_  "U_C489_MY16_Gas_Tx" ENUM  "No","Yes";
BA_DEF_ SG_  "U_CD42_MY16_Diesel_Tx" ENUM  "No","Yes";
BA_DEF_ SG_  "U_CD42_MY16_Gas_Tx" ENUM  "No","Yes";
BA_DEF_ SG_  "GenSigTimeoutTime_GFM2_UIM" INT 0 100000;
BA_DEF_ SG_  "U_CD42_MY15_Diesel_Rx" ENUM  "No","Yes";
BA_DEF_ SG_  "U_CD42_MY15_Gas_Rx" ENUM  "No","Yes";
BA_DEF_ SG_  "U_U502_MY16_Gas_Rx" ENUM  "No","Yes";
BA_DEF_ SG_  "U_CD4_MY15_Diesel_Rx" ENUM  "No","Yes";
BA_DEF_ SG_  "U_CD4_MY15_Gas_Rx" ENUM  "No","Yes";
BA_DEF_ SG_  "U_CD4_MY15_Hev_Rx" ENUM  "No","Yes";
BA_DEF_ SG_  "U_CD4_MY15_Phev_Rx" ENUM  "No","Yes";
BA_DEF_ SG_  "U_P558_MY17_Gas_Rx" ENUM  "No","Yes";
BA_DEF_ SG_  "U_P558_MY17_Diesel_Rx" ENUM  "No","Yes";
BA_DEF_ SG_  "U_V36X_MY16_5_Diesel_Rx" ENUM  "No","Yes";
BA_DEF_ SG_  "U_CD42_MY15_Diesel_Tx" ENUM  "No","Yes";
BA_DEF_ SG_  "U_CD42_MY15_Gas_Tx" ENUM  "No","Yes";
BA_DEF_ SG_  "U_U502_MY16_Gas_Tx" ENUM  "No","Yes";
BA_DEF_ SG_  "U_CD4_MY15_Diesel_Tx" ENUM  "No","Yes";
BA_DEF_ SG_  "U_CD4_MY15_Gas_Tx" ENUM  "No","Yes";
BA_DEF_ SG_  "U_CD4_MY15_Hev_Tx" ENUM  "No","Yes";
BA_DEF_ SG_  "U_CD4_MY15_Phev_Tx" ENUM  "No","Yes";
BA_DEF_ SG_  "U_P558_MY17_Gas_Tx" ENUM  "No","Yes";
BA_DEF_ SG_  "U_P558_MY17_Diesel_Tx" ENUM  "No","Yes";
BA_DEF_ SG_  "U_V36X_MY16_5_Diesel_Tx" ENUM  "No","Yes";
BA_DEF_ SG_  "GenSigTimeoutTime_HCM" INT 0 100000;
BA_DEF_ SG_  "GenSigTimeoutTime_TCM" INT 0 100000;
BA_DEF_ SG_  "GenSigTimeoutTime_ECM" INT 0 100000;
BA_DEF_ SG_  "GenSigTimeoutTime_AHCM_PTC" INT 0 100000;
BA_DEF_ SG_  "GenSigTimeoutTime_EONV" INT 0 100000;
BA_DEF_ SG_  "GenSigTimeoutTime_GENERIC" INT 0 100000;
BA_DEF_ SG_  "GenSigTimeoutTime_BECM" INT 0 100000;
BA_DEF_ SG_  "GenSigTimeoutTime_ECM_HEV" INT 0 100000;
BA_DEF_ SG_  "GenSigTimeoutTime_DCDC_HEV" INT 0 100000;
BA_DEF_ SG_  "GenSigTimeoutTime_SOBDMC_HPCM" INT 0 100000;
BA_DEF_ SG_  "GenSigTimeoutTime_DCDC_VSM" INT 0 100000;
BA_DEF_ SG_  "GenSigTimeoutTime_ICM" INT 0 100000;
BA_DEF_ SG_  "GenSigTimeoutTime_ACCM" INT 0 100000;
BA_DEF_ SG_  "GenSigTimeoutTime_GFM_CPLR" INT 0 100000;
BA_DEF_ SG_  "GenSigTimeoutTime_SOBDM_BCCM" INT 0 100000;
BA_DEF_ SG_  "GenSigTimeoutTime_AWD" INT 0 100000;
BA_DEF_ SG_  "Gateway_ID" INT 0 0;
BA_DEF_ SG_  "GenSigTimeoutTime_Generic_BCM" INT 0 100000;
BA_DEF_ SG_  "GenSigTimeoutTime_DCDC_VQM" INT 0 100000;
BA_DEF_ SG_  "GenSigTimeoutTime__delete" INT 0 100000;
BA_DEF_ SG_  "GenSigTimeoutTime_PAM" INT 0 100000;
BA_DEF_ SG_  "GenSigTimeoutTime_APIM" INT 0 100000;
BA_DEF_ SG_  "GenSigTimeoutTime_PCM" INT 0 100000;
BA_DEF_ SG_  "GenSigTimeoutTime_BCM" INT 0 100000;
BA_DEF_ SG_  "GenSigTimeoutTime_TSTR" INT 0 100000;
BA_DEF_ SG_  "GenSigTimeoutTime_GWM" INT 0 100000;
BA_DEF_  "BusType" STRING ;
BA_DEF_ BO_  "FrameGatewayMS1" HEX 0 1407;
BA_DEF_ BO_  "FrameGatewayHS3" HEX 0 1407;
BA_DEF_ BO_  "FrameGatewayHS2" HEX 0 1407;
BA_DEF_ BO_  "FrameGatewayHS1" HEX 0 1407;
BA_DEF_ BO_  "NetworkInitialization" ENUM  "No","Yes";
BA_DEF_ BO_  "FrameGatewayId" HEX 0 1407;
BA_DEF_ BO_  "EventRateOfChange" INT 10 10000;
BA_DEF_ BO_  "GenMsgStartDelayTime" INT 0 10000;
BA_DEF_ BO_  "GenMsgNrOfRepetition" INT 0 100;
BA_DEF_ BO_  "GenMsgDelayTime" INT 0 1000;
BA_DEF_ BO_  "GenMsgCycleTime" INT 0 100000;
BA_DEF_ BO_  "GenMsgSendType" ENUM  "FixedPeriodic","Event","EnabledPeriodic","NotUsed","NotUsed","EventPeriodic","NotUsed","NotUsed","NoMsgSendType";
BA_DEF_ SG_  "U_CD4_MY14_Phev_Tx" ENUM  "No","Yes";
BA_DEF_ SG_  "U_CD4_MY14_Hev_Tx" ENUM  "No","Yes";
BA_DEF_ SG_  "U_CD4_MY14_Gas_Tx" ENUM  "No","Yes";
BA_DEF_ SG_  "U_CD4_MY14_Diesel_Tx" ENUM  "No","Yes";
BA_DEF_ SG_  "U_CD43_MY16_Gas_Tx" ENUM  "No","Yes";
BA_DEF_ SG_  "U_UP375_MY15_Diesel_Tx" ENUM  "No","Yes";
BA_DEF_ SG_  "U_UP375_MY15_Gas_Tx" ENUM  "No","Yes";
BA_DEF_ SG_  "U_U502_MY15_Gas_Tx" ENUM  "No","Yes";
BA_DEF_ SG_  "U_B562LC_MY14_Gas_Tx" ENUM  "No","Yes";
BA_DEF_ SG_  "U_B562LC_MY14_Diesel_Tx" ENUM  "No","Yes";
BA_DEF_ SG_  "U_C489_MY14_Gas_Tx" ENUM  "No","Yes";
BA_DEF_ SG_  "U_S550_MY15_Gas_Tx" ENUM  "No","Yes";
BA_DEF_ SG_  "U_P552_MY15_Gas_Tx" ENUM  "No","Yes";
BA_DEF_ SG_  "U_CD42_MY14_Gas_Tx" ENUM  "No","Yes";
BA_DEF_ SG_  "U_CD42_MY14_Diesel_Tx" ENUM  "No","Yes";
BA_DEF_ SG_  "U_CD4_MY13_Phev_Tx" ENUM  "No","Yes";
BA_DEF_ SG_  "U_CD4_MY13_Hev_Tx" ENUM  "No","Yes";
BA_DEF_ SG_  "U_CD4_MY13_Gas_Tx" ENUM  "No","Yes";
BA_DEF_ SG_  "U_CD4_MY13_Diesel_Tx" ENUM  "No","Yes";
BA_DEF_ SG_  "U_CD4_MY14_Phev_Rx" ENUM  "No","Yes";
BA_DEF_ SG_  "U_CD4_MY14_Hev_Rx" ENUM  "No","Yes";
BA_DEF_ SG_  "U_CD4_MY14_Gas_Rx" ENUM  "No","Yes";
BA_DEF_ SG_  "U_CD4_MY14_Diesel_Rx" ENUM  "No","Yes";
BA_DEF_ SG_  "U_CD43_MY16_Gas_Rx" ENUM  "No","Yes";
BA_DEF_ SG_  "U_UP375_MY15_Diesel_Rx" ENUM  "No","Yes";
BA_DEF_ SG_  "U_UP375_MY15_Gas_Rx" ENUM  "No","Yes";
BA_DEF_ SG_  "U_B479_MY15_Gas_Rx" ENUM  "No","Yes";
BA_DEF_ SG_  "U_U502_MY15_Gas_Rx" ENUM  "No","Yes";
BA_DEF_ SG_  "U_B562LC_MY14_Gas_Rx" ENUM  "No","Yes";
BA_DEF_ SG_  "U_B562LC_MY14_Diesel_Rx" ENUM  "No","Yes";
BA_DEF_ SG_  "U_C489_MY14_Gas_Rx" ENUM  "No","Yes";
BA_DEF_ SG_  "U_S550_MY15_Gas_Rx" ENUM  "No","Yes";
BA_DEF_ SG_  "U_P552_MY15_Gas_Rx" ENUM  "No","Yes";
BA_DEF_ SG_  "U_CD42_MY14_Gas_Rx" ENUM  "No","Yes";
BA_DEF_ SG_  "U_CD42_MY14_Diesel_Rx" ENUM  "No","Yes";
BA_DEF_ SG_  "U_CD4_MY13_Phev_Rx" ENUM  "No","Yes";
BA_DEF_ SG_  "U_CD4_MY13_Hev_Rx" ENUM  "No","Yes";
BA_DEF_ SG_  "U_CD4_MY13_Gas_Rx" ENUM  "No","Yes";
BA_DEF_ SG_  "U_CD4_MY13_Diesel_Rx" ENUM  "No","Yes";
BA_DEF_ SG_  "ContentDependant" ENUM  "No","Yes";
BA_DEF_ SG_  "GenSigStartValue" INT 0 1000000000;
BA_DEF_ SG_  "UsedOnPgmDBC" ENUM  "No","Yes";
BA_DEF_ SG_  "CrossOver_LIN" ENUM  "No","Yes";
BA_DEF_ SG_  "CrossOver_InfoCAN" ENUM  "No","Yes";
BA_DEF_ SG_  "WakeupSignal" ENUM  "No","Yes";
BA_DEF_ SG_  "FMC_SIG_SSPEC" STRING ;
BA_DEF_ SG_  "GenSigMissingSourceValue" INT 0 1000000000;
BA_DEF_ SG_  "GenSigInactiveValue" INT 0 100000;
BA_DEF_ SG_  "GenSigSendType" ENUM  "Cyclic","OnWrite","vector_leerstring","OnChange","vector_leerstring","IfActive","vector_leerstring","NoSigSendType";
BA_DEF_ BO_  "NmAsrMessage" ENUM  "No","Yes";
BA_DEF_ BO_  "TpApplType" STRING ;
BA_DEF_ BO_  "DiagState" ENUM  "No","Yes";
BA_DEF_ BO_  "DiagRequest" ENUM  "No","Yes";
BA_DEF_ BO_  "DiagResponse" ENUM  "No","Yes";
BA_DEF_ BO_  "GenMsgILSupport" ENUM  "No","Yes";
BA_DEF_ BU_  "Terminator" ENUM  "No","Yes";
BA_DEF_ BU_  "NodeWakeUpTime" INT 0 1000;
BA_DEF_ BU_  "NodeStartUpTime" INT 0 1000;
BA_DEF_ BU_  "NmAsrNodeIdentifier" HEX 128 255;
BA_DEF_ BU_  "NmAsrNode" ENUM  "No","Yes";
BA_DEF_ BU_  "PowerType" ENUM  "Switched","Latched","Sleep","vector_leerstring","vector_leerstring";
BA_DEF_ BU_  "DiagNode" ENUM  "GGDS","GDS","NONE";
BA_DEF_ BU_  "EOL_SB_Flash" ENUM  "GGDS","GDS","NONE","vector_leerstring";
BA_DEF_ BU_  "NmNode" ENUM  "No","Yes";
BA_DEF_ BU_  "NmStationAddress" INT 0 255;
BA_DEF_ BU_  "ILUsed" ENUM  "No","Yes";
BA_DEF_ BU_  "NosPackage" ENUM  "None","I3_1","I3_2","1.0.1","RP","EuCD","Volcano";
BA_DEF_ BU_  "LIN_Master" ENUM  "No","Yes";
BA_DEF_ BU_  "PackageID" STRING ;
BA_DEF_ BU_  "GatewayECU" ENUM  "No","Yes";
BA_DEF_  "StarNetworkGwType" ENUM  "0=NotDefined","1=HS1","2=HS2","3=HS3","4=HS4","5=HS5","6=MS1";
BA_DEF_  "CMDB_Version" STRING ;
BA_DEF_  "NmType" STRING ;
BA_DEF_  "NetworkSpeed" ENUM  "500kBits/s","125kBit/s";
BA_DEF_  "NmAsrMessageCount" INT 128 128;
BA_DEF_  "NmAsrBaseAddress" HEX 1408 1408;
BA_DEF_  "DBName" STRING ;
BA_DEF_  "VersionDay" INT 1 31;
BA_DEF_  "Manufacturer" STRING ;
BA_DEF_  "VersionNumber" INT 0 10000;
BA_DEF_  "VersionMonth" INT 1 12;
BA_DEF_  "VersionYear" INT 2000 3000;
BA_DEF_  "NmBaseAddress" HEX 1280 1280;
BA_DEF_  "NmMessageCount" INT 0 128;
BA_DEF_DEF_  "U_UP375_MY19_Gas_Rx" "No";
BA_DEF_DEF_  "U_UP375_MY19_Diesel_Rx" "No";
BA_DEF_DEF_  "U_D568C_MY19_Gas_Rx" "No";
BA_DEF_DEF_  "U_CD4_MY19_Diesel_Rx" "No";
BA_DEF_DEF_  "U_CD4_MY19_Gas_Rx" "No";
BA_DEF_DEF_  "U_CD4_MY19_Hev_Rx" "No";
BA_DEF_DEF_  "U_CD4_MY19_Phev_Rx" "No";
BA_DEF_DEF_  "U_V36X_MY19_Rx" "No";
BA_DEF_DEF_  "U_UP375_MY19_Diesel_Tx" "No";
BA_DEF_DEF_  "U_D568C_MY19_Gas_Tx" "No";
BA_DEF_DEF_  "U_CD4_MY19_Diesel_Tx" "No";
BA_DEF_DEF_  "U_CD4_MY19_Gas_Tx" "No";
BA_DEF_DEF_  "U_CD4_MY19_Hev_Tx" "No";
BA_DEF_DEF_  "U_CD4_MY19_Phev_Tx" "No";
BA_DEF_DEF_  "U_V36X_MY19_Tx" "No";
BA_DEF_DEF_  "GenSigTimeoutTime_ECM_HEVDSL" 5000;
BA_DEF_DEF_  "GenSigTimeoutTime_GFM2_DCGM" 5000;
BA_DEF_DEF_  "MetaData" "No";
BA_DEF_DEF_  "U_UP375_MY18_Gas_Rx" "No";
BA_DEF_DEF_  "U_UP375_MY18_Diesel_Rx" "No";
BA_DEF_DEF_  "U_V36X_MY18_5_Gas_Rx" "No";
BA_DEF_DEF_  "U_V36X_MY18_5_Hev_Rx" "No";
BA_DEF_DEF_  "U_V36X_MY18_5_Gas_Tx" "No";
BA_DEF_DEF_  "U_V36X_MY18_5_Hev_Tx" "No";
BA_DEF_DEF_  "U_V36X_MY19_5_Diesel_Rx" "No";
BA_DEF_DEF_  "U_V363E_N_MY19_5_20_Gas_Rx" "No";
BA_DEF_DEF_  "U_V363E_N_MY19_5_20_Diesel_Rx" "No";
BA_DEF_DEF_  "U_CD42_MY19_Diesel_Rx" "No";
BA_DEF_DEF_  "U_V36X_MY19_5_Diesel_Tx" "No";
BA_DEF_DEF_  "U_V363E_N_MY19_5_20_Gas_Tx" "No";
BA_DEF_DEF_  "U_V363E_N_MY19_5_20_Diesel_Tx" "No";
BA_DEF_DEF_  "U_CD42_MY19_Diesel_Tx" "No";
BA_DEF_DEF_  "U_CD42_MY19_Gas_Tx" "No";
BA_DEF_DEF_  "GenSigTimeoutTime_AWD_DLCM" 5000;
BA_DEF_DEF_  "U_U502_MY17_Gas_Rx" "No";
BA_DEF_DEF_  "U_CD4_MY18_Diesel_Rx" "No";
BA_DEF_DEF_  "U_CD4_MY18_Gas_Rx" "No";
BA_DEF_DEF_  "U_CD4_MY18_Hev_Rx" "No";
BA_DEF_DEF_  "U_CD4_MY18_Phev_Rx" "No";
BA_DEF_DEF_  "U_S550_MY18_Gas_Rx" "No";
BA_DEF_DEF_  "U_V408_MY18_Gas_Rx" "No";
BA_DEF_DEF_  "U_V408_MY18_Diesel_Rx" "No";
BA_DEF_DEF_  "U_V36X_MY18_5_Diesel_Rx" "No";
BA_DEF_DEF_  "U_P552_MY18_5_Gas_Rx" "No";
BA_DEF_DEF_  "U_P552_MY18_5_Diesel_Rx" "No";
BA_DEF_DEF_  "U_U502_MY17_Gas_Tx" "No";
BA_DEF_DEF_  "U_CD4_MY18_Diesel_Tx" "No";
BA_DEF_DEF_  "U_CD4_MY18_Gas_Tx" "No";
BA_DEF_DEF_  "U_CD4_MY18_Hev_Tx" "No";
BA_DEF_DEF_  "U_CD4_MY18_Phev_Tx" "No";
BA_DEF_DEF_  "U_S550_MY18_Gas_Tx" "No";
BA_DEF_DEF_  "U_V408_MY18_Gas_Tx" "No";
BA_DEF_DEF_  "U_V408_MY18_Diesel_Tx" "No";
BA_DEF_DEF_  "U_V36X_MY18_5_Diesel_Tx" "No";
BA_DEF_DEF_  "U_P552_MY18_5_Gas_Tx" "No";
BA_DEF_DEF_  "U_P552_MY18_5_Diesel_Tx" "No";
BA_DEF_DEF_  "GenSigTimeoutTime_ECM_Diesel" 5000;
BA_DEF_DEF_  "GenSigTimeoutTime_DCMR_ELSD" 5000;
BA_DEF_DEF_  "GenSigTimeoutTime_TCM_Diesel" 5000;
BA_DEF_DEF_  "U_P552_MY18_Gas_Rx" "No";
BA_DEF_DEF_  "U_U55x_MY18_Gas_Rx" "No";
BA_DEF_DEF_  "U_P552_MY18_Gas_Tx" "No";
BA_DEF_DEF_  "U_U55x_MY18_Gas_Tx" "No";
BA_DEF_DEF_  "FrameGatewayNetwork" "NONE";
BA_DEF_DEF_  "U_C489_MY17_Gas_Rx" "No";
BA_DEF_DEF_  "U_CD43_MY17_Gas_Rx" "No";
BA_DEF_DEF_  "U_P552_MY17_Gas_Rx" "No";
BA_DEF_DEF_  "U_B515_MCA_MY17_Diesel_Rx" "No";
BA_DEF_DEF_  "U_B515_MCA_MY17_Gas_Rx" "No";
BA_DEF_DEF_  "U_C489_MY17_Gas_Tx" "No";
BA_DEF_DEF_  "U_CD43_MY17_Gas_Tx" "No";
BA_DEF_DEF_  "U_P552_MY17_Gas_Tx" "No";
BA_DEF_DEF_  "U_B515_MCA_MY17_Diesel_Tx" "No";
BA_DEF_DEF_  "U_B515_MCA_MY17_Gas_Tx" "No";
BA_DEF_DEF_  "GenSigTimeoutTime_SOBDMD_AHCM_P" 5000;
BA_DEF_DEF_  "GenSigTimeoutTime_PACM" 5000;
BA_DEF_DEF_  "GenSigTimeoutTime_BECMB_EPM" 5000;
BA_DEF_DEF_  "U_B562LC_MY15_Diesel_Rx" "No";
BA_DEF_DEF_  "U_B562LC_MY15_Gas_Rx" "No";
BA_DEF_DEF_  "U_B479_MY17_Gas_Rx" "No";
BA_DEF_DEF_  "U_CD4_MY17_Diesel_Rx" "No";
BA_DEF_DEF_  "U_CD4_MY17_Gas_Rx" "No";
BA_DEF_DEF_  "U_CD4_MY17_Hev_Rx" "No";
BA_DEF_DEF_  "U_CD4_MY17_Phev_Rx" "No";
BA_DEF_DEF_  "U_C489_MY16_Gas_Rx" "No";
BA_DEF_DEF_  "U_CD42_MY16_Diesel_Rx" "No";
BA_DEF_DEF_  "U_CD42_MY16_Gas_Rx" "No";
BA_DEF_DEF_  "U_B562LC_MY15_Diesel_Tx" "No";
BA_DEF_DEF_  "U_B562LC_MY15_Gas_Tx" "No";
BA_DEF_DEF_  "U_CD4_MY17_Diesel_Tx" "No";
BA_DEF_DEF_  "U_CD4_MY17_Gas_Tx" "No";
BA_DEF_DEF_  "U_CD4_MY17_Hev_Tx" "No";
BA_DEF_DEF_  "U_CD4_MY17_Phev_Tx" "No";
BA_DEF_DEF_  "U_C489_MY16_Gas_Tx" "No";
BA_DEF_DEF_  "U_CD42_MY16_Diesel_Tx" "No";
BA_DEF_DEF_  "U_CD42_MY16_Gas_Tx" "No";
BA_DEF_DEF_  "GenSigTimeoutTime_GFM2_UIM" 5000;
BA_DEF_DEF_  "U_CD42_MY15_Diesel_Rx" "No";
BA_DEF_DEF_  "U_CD42_MY15_Gas_Rx" "No";
BA_DEF_DEF_  "U_U502_MY16_Gas_Rx" "No";
BA_DEF_DEF_  "U_CD4_MY15_Diesel_Rx" "No";
BA_DEF_DEF_  "U_CD4_MY15_Gas_Rx" "No";
BA_DEF_DEF_  "U_CD4_MY15_Hev_Rx" "No";
BA_DEF_DEF_  "U_CD4_MY15_Phev_Rx" "No";
BA_DEF_DEF_  "U_P558_MY17_Gas_Rx" "No";
BA_DEF_DEF_  "U_P558_MY17_Diesel_Rx" "No";
BA_DEF_DEF_  "U_V36X_MY16_5_Diesel_Rx" "No";
BA_DEF_DEF_  "U_CD42_MY15_Diesel_Tx" "No";
BA_DEF_DEF_  "U_CD42_MY15_Gas_Tx" "No";
BA_DEF_DEF_  "U_U502_MY16_Gas_Tx" "No";
BA_DEF_DEF_  "U_CD4_MY15_Diesel_Tx" "No";
BA_DEF_DEF_  "U_CD4_MY15_Gas_Tx" "No";
BA_DEF_DEF_  "U_CD4_MY15_Hev_Tx" "No";
BA_DEF_DEF_  "U_CD4_MY15_Phev_Tx" "No";
BA_DEF_DEF_  "U_P558_MY17_Gas_Tx" "No";
BA_DEF_DEF_  "U_P558_MY17_Diesel_Tx" "No";
BA_DEF_DEF_  "U_V36X_MY16_5_Diesel_Tx" "No";
BA_DEF_DEF_  "GenSigTimeoutTime_HCM" 5000;
BA_DEF_DEF_  "GenSigTimeoutTime_TCM" 5000;
BA_DEF_DEF_  "GenSigTimeoutTime_ECM" 5000;
BA_DEF_DEF_  "GenSigTimeoutTime_AHCM_PTC" 5000;
BA_DEF_DEF_  "GenSigTimeoutTime_EONV" 5000;
BA_DEF_DEF_  "GenSigTimeoutTime_GENERIC" 5000;
BA_DEF_DEF_  "GenSigTimeoutTime_BECM" 5000;
BA_DEF_DEF_  "GenSigTimeoutTime_ECM_HEV" 5000;
BA_DEF_DEF_  "GenSigTimeoutTime_DCDC_HEV" 5000;
BA_DEF_DEF_  "GenSigTimeoutTime_SOBDMC_HPCM" 5000;
BA_DEF_DEF_  "GenSigTimeoutTime_DCDC_VSM" 5000;
BA_DEF_DEF_  "GenSigTimeoutTime_ICM" 5000;
BA_DEF_DEF_  "GenSigTimeoutTime_ACCM" 5000;
BA_DEF_DEF_  "GenSigTimeoutTime_GFM_CPLR" 5000;
BA_DEF_DEF_  "GenSigTimeoutTime_SOBDM_BCCM" 5000;
BA_DEF_DEF_  "GenSigTimeoutTime_AWD" 5000;
BA_DEF_DEF_  "Gateway_ID" 0;
BA_DEF_DEF_  "GenSigTimeoutTime_Generic_BCM" 5000;
BA_DEF_DEF_  "GenSigTimeoutTime_DCDC_VQM" 5000;
BA_DEF_DEF_  "GenSigTimeoutTime__delete" 5000;
BA_DEF_DEF_  "GenSigTimeoutTime_PAM" 5000;
BA_DEF_DEF_  "GenSigTimeoutTime_APIM" 5000;
BA_DEF_DEF_  "GenSigTimeoutTime_PCM" 5000;
BA_DEF_DEF_  "GenSigTimeoutTime_BCM" 5000;
BA_DEF_DEF_  "GenSigTimeoutTime_TSTR" 5000;
BA_DEF_DEF_  "GenSigTimeoutTime_GWM" 5000;
BA_DEF_DEF_  "BusType" "";
BA_DEF_DEF_  "FrameGatewayMS1" 0;
BA_DEF_DEF_  "FrameGatewayHS3" 0;
BA_DEF_DEF_  "FrameGatewayHS2" 0;
BA_DEF_DEF_  "FrameGatewayHS1" 0;
BA_DEF_DEF_  "NetworkInitialization" "No";
BA_DEF_DEF_  "FrameGatewayId" 0;
BA_DEF_DEF_  "EventRateOfChange" 10000;
BA_DEF_DEF_  "GenMsgStartDelayTime" 0;
BA_DEF_DEF_  "GenMsgNrOfRepetition" 1;
BA_DEF_DEF_  "GenMsgDelayTime" 20;
BA_DEF_DEF_  "GenMsgCycleTime" 0;
BA_DEF_DEF_  "GenMsgSendType" "NoMsgSendType";
BA_DEF_DEF_  "U_CD4_MY14_Phev_Tx" "No";
BA_DEF_DEF_  "U_CD4_MY14_Hev_Tx" "No";
BA_DEF_DEF_  "U_CD4_MY14_Gas_Tx" "No";
BA_DEF_DEF_  "U_CD4_MY14_Diesel_Tx" "No";
BA_DEF_DEF_  "U_CD43_MY16_Gas_Tx" "No";
BA_DEF_DEF_  "U_UP375_MY15_Diesel_Tx" "No";
BA_DEF_DEF_  "U_UP375_MY15_Gas_Tx" "No";
BA_DEF_DEF_  "U_U502_MY15_Gas_Tx" "No";
BA_DEF_DEF_  "U_B562LC_MY14_Gas_Tx" "No";
BA_DEF_DEF_  "U_B562LC_MY14_Diesel_Tx" "No";
BA_DEF_DEF_  "U_C489_MY14_Gas_Tx" "No";
BA_DEF_DEF_  "U_S550_MY15_Gas_Tx" "No";
BA_DEF_DEF_  "U_P552_MY15_Gas_Tx" "No";
BA_DEF_DEF_  "U_CD42_MY14_Gas_Tx" "No";
BA_DEF_DEF_  "U_CD42_MY14_Diesel_Tx" "No";
BA_DEF_DEF_  "U_CD4_MY13_Phev_Tx" "No";
BA_DEF_DEF_  "U_CD4_MY13_Hev_Tx" "No";
BA_DEF_DEF_  "U_CD4_MY13_Gas_Tx" "No";
BA_DEF_DEF_  "U_CD4_MY13_Diesel_Tx" "No";
BA_DEF_DEF_  "U_CD4_MY14_Phev_Rx" "No";
BA_DEF_DEF_  "U_CD4_MY14_Hev_Rx" "No";
BA_DEF_DEF_  "U_CD4_MY14_Gas_Rx" "No";
BA_DEF_DEF_  "U_CD4_MY14_Diesel_Rx" "No";
BA_DEF_DEF_  "U_CD43_MY16_Gas_Rx" "No";
BA_DEF_DEF_  "U_UP375_MY15_Diesel_Rx" "No";
BA_DEF_DEF_  "U_UP375_MY15_Gas_Rx" "No";
BA_DEF_DEF_  "U_B479_MY15_Gas_Rx" "No";
BA_DEF_DEF_  "U_U502_MY15_Gas_Rx" "No";
BA_DEF_DEF_  "U_B562LC_MY14_Gas_Rx" "No";
BA_DEF_DEF_  "U_B562LC_MY14_Diesel_Rx" "No";
BA_DEF_DEF_  "U_C489_MY14_Gas_Rx" "No";
BA_DEF_DEF_  "U_S550_MY15_Gas_Rx" "No";
BA_DEF_DEF_  "U_P552_MY15_Gas_Rx" "No";
BA_DEF_DEF_  "U_CD42_MY14_Gas_Rx" "No";
BA_DEF_DEF_  "U_CD42_MY14_Diesel_Rx" "No";
BA_DEF_DEF_  "U_CD4_MY13_Phev_Rx" "No";
BA_DEF_DEF_  "U_CD4_MY13_Hev_Rx" "No";
BA_DEF_DEF_  "U_CD4_MY13_Gas_Rx" "No";
BA_DEF_DEF_  "U_CD4_MY13_Diesel_Rx" "No";
BA_DEF_DEF_  "ContentDependant" "No";
BA_DEF_DEF_  "GenSigStartValue" 0;
BA_DEF_DEF_  "UsedOnPgmDBC" "Yes";
BA_DEF_DEF_  "CrossOver_LIN" "No";
BA_DEF_DEF_  "CrossOver_InfoCAN" "No";
BA_DEF_DEF_  "WakeupSignal" "No";
BA_DEF_DEF_  "FMC_SIG_SSPEC" "Unknown";
BA_DEF_DEF_  "GenSigMissingSourceValue" 0;
BA_DEF_DEF_  "GenSigInactiveValue" 0;
BA_DEF_DEF_  "GenSigSendType" "NoSigSendType";
BA_DEF_DEF_  "NmAsrMessage" "No";
BA_DEF_DEF_  "TpApplType" "";
BA_DEF_DEF_  "DiagState" "No";
BA_DEF_DEF_  "DiagRequest" "No";
BA_DEF_DEF_  "DiagResponse" "No";
BA_DEF_DEF_  "GenMsgILSupport" "Yes";
BA_DEF_DEF_  "Terminator" "No";
BA_DEF_DEF_  "NodeWakeUpTime" 10;
BA_DEF_DEF_  "NodeStartUpTime" 250;
BA_DEF_DEF_  "NmAsrNodeIdentifier" 128;
BA_DEF_DEF_  "NmAsrNode" "No";
BA_DEF_DEF_  "PowerType" "Switched";
BA_DEF_DEF_  "DiagNode" "GGDS";
BA_DEF_DEF_  "EOL_SB_Flash" "GGDS";
BA_DEF_DEF_  "NmNode" "No";
BA_DEF_DEF_  "NmStationAddress" 0;
BA_DEF_DEF_  "ILUsed" "Yes";
BA_DEF_DEF_  "NosPackage" "I3_1";
BA_DEF_DEF_  "LIN_Master" "No";
BA_DEF_DEF_  "PackageID" "08.05.00.00.71.xx.xx.rr.00.00";
BA_DEF_DEF_  "GatewayECU" "No";
BA_DEF_DEF_  "StarNetworkGwType" "0=NotDefined";
BA_DEF_DEF_  "CMDB_Version" "v11.01";
BA_DEF_DEF_  "NmType" "Ford-OSEK";
BA_DEF_DEF_  "NetworkSpeed" "500kBits/s";
BA_DEF_DEF_  "NmAsrMessageCount" 128;
BA_DEF_DEF_  "NmAsrBaseAddress" 1408;
BA_DEF_DEF_  "DBName" "";
BA_DEF_DEF_  "VersionDay" 1;
BA_DEF_DEF_  "Manufacturer" "Ford";
BA_DEF_DEF_  "VersionNumber" 1;
BA_DEF_DEF_  "VersionMonth" 1;
BA_DEF_DEF_  "VersionYear" 2011;
BA_DEF_DEF_  "NmBaseAddress" 1280;
BA_DEF_DEF_  "NmMessageCount" 128;
BA_ "VersionDay" 20;
BA_ "BusType" "CAN";
BA_ "VersionYear" 2018;
BA_ "VersionMonth" 3;
BA_ "CMDB_Version" "v13.09";
BA_ "StarNetworkGwType" 1;
BA_ "VersionNumber" 9;
BA_ "DBName" "HS1_CAN";
BA_ "NmStationAddress" BU_ TCM_Diesel 32;
BA_ "PowerType" BU_ TCM_Diesel 2;
BA_ "NmAsrNode" BU_ TCM_Diesel 1;
BA_ "NmAsrNodeIdentifier" BU_ TCM_Diesel 160;
BA_ "NodeStartUpTime" BU_ TCM_Diesel 1000;
BA_ "NodeWakeUpTime" BU_ TCM_Diesel 150;
BA_ "Terminator" BU_ ECM_Diesel 1;
BA_ "NmAsrNodeIdentifier" BU_ ECM_Diesel 149;
BA_ "NmAsrNode" BU_ ECM_Diesel 1;
BA_ "PowerType" BU_ ECM_Diesel 1;
BA_ "NmStationAddress" BU_ ECM_Diesel 21;
BA_ "NodeWakeUpTime" BU_ BECMB_EPM 70;
BA_ "NmStationAddress" BU_ BECMB_EPM 50;
BA_ "PowerType" BU_ BECMB_EPM 2;
BA_ "NmAsrNode" BU_ BECMB_EPM 1;
BA_ "NmAsrNodeIdentifier" BU_ BECMB_EPM 178;
BA_ "NosPackage" BU_ TCM 4;
BA_ "NmStationAddress" BU_ TCM 32;
BA_ "PowerType" BU_ TCM 2;
BA_ "NmAsrNode" BU_ TCM 1;
BA_ "NmAsrNodeIdentifier" BU_ TCM 160;
BA_ "NodeStartUpTime" BU_ TCM 1000;
BA_ "NodeWakeUpTime" BU_ TCM 150;
BA_ "Terminator" BU_ ECM 1;
BA_ "NmAsrNodeIdentifier" BU_ ECM 165;
BA_ "NmAsrNode" BU_ ECM 1;
BA_ "PowerType" BU_ ECM 1;
BA_ "NmStationAddress" BU_ ECM 37;
BA_ "NmStationAddress" BU_ Generic_BCM 1;
BA_ "PowerType" BU_ Generic_BCM 2;
BA_ "NmAsrNode" BU_ Generic_BCM 1;
BA_ "NmAsrNodeIdentifier" BU_ Generic_BCM 129;
BA_ "NodeStartUpTime" BU_ Generic_BCM 1000;
BA_ "NmStationAddress" BU_ GWM 30;
BA_ "PowerType" BU_ GWM 2;
BA_ "NmAsrNode" BU_ GWM 1;
BA_ "NmAsrNodeIdentifier" BU_ GWM 158;
BA_ "NodeStartUpTime" BU_ GWM 100;
BA_ "Terminator" BU_ GWM 1;
BA_ "GatewayECU" BU_ GWM 1;
BA_ "NosPackage" BU_ GWM 4;
BA_ "NmStationAddress" BU_ APIM 98;
BA_ "PowerType" BU_ APIM 2;
BA_ "NmAsrNode" BU_ APIM 1;
BA_ "NmAsrNodeIdentifier" BU_ APIM 226;
BA_ "NodeStartUpTime" BU_ APIM 1000;
BA_ "NodeWakeUpTime" BU_ APIM 200;
BA_ "NosPackage" BU_ APIM 4;
BA_ "NmStationAddress" BU_ BCM 1;
BA_ "PowerType" BU_ BCM 2;
BA_ "NmAsrNode" BU_ BCM 1;
BA_ "NmAsrNodeIdentifier" BU_ BCM 129;
BA_ "NodeStartUpTime" BU_ BCM 1000;
BA_ "NodeWakeUpTime" BU_ BCM 100;
BA_ "PackageID" BU_ BCM "08.06.00.00.81";
BA_ "LIN_Master" BU_ BCM 1;
BA_ "NosPackage" BU_ BCM 4;
BA_ "NmStationAddress" BU_ DCDC_VQM 56;
BA_ "PowerType" BU_ DCDC_VQM 1;
BA_ "NmStationAddress" BU_ PAM 10;
BA_ "NmStationAddress" BU_ PCM 21;
BA_ "PowerType" BU_ PCM 1;
BA_ "NmAsrNode" BU_ PCM 1;
BA_ "NmAsrNodeIdentifier" BU_ PCM 149;
BA_ "Terminator" BU_ PCM 1;
BA_ "NetworkInitialization" BO_ 1082 1;
BA_ "GenMsgSendType" BO_ 1082 5;
BA_ "GenMsgCycleTime" BO_ 1082 1000;
BA_ "NetworkInitialization" BO_ 1100 1;
BA_ "GenMsgSendType" BO_ 1100 5;
BA_ "GenMsgCycleTime" BO_ 1100 1000;
BA_ "GenMsgSendType" BO_ 145 1;
BA_ "FrameGatewayNetwork" BO_ 980 "HS2_CAN";
BA_ "FrameGatewayHS2" BO_ 980 980;
BA_ "FrameGatewayId" BO_ 980 980;
BA_ "FrameGatewayId" BO_ 985 985;
BA_ "FrameGatewayHS2" BO_ 985 985;
BA_ "FrameGatewayNetwork" BO_ 985 "HS2_CAN";
BA_ "NetworkInitialization" BO_ 985 1;
BA_ "FrameGatewayId" BO_ 962 962;
BA_ "FrameGatewayHS2" BO_ 962 962;
BA_ "FrameGatewayNetwork" BO_ 962 "HS2_CAN";
BA_ "FrameGatewayId" BO_ 961 961;
BA_ "FrameGatewayHS2" BO_ 961 961;
BA_ "FrameGatewayNetwork" BO_ 961 "HS2_CAN";
BA_ "FrameGatewayNetwork" BO_ 984 "HS2_CAN";
BA_ "FrameGatewayHS2" BO_ 984 984;
BA_ "FrameGatewayId" BO_ 984 984;
BA_ "NetworkInitialization" BO_ 984 1;
BA_ "GenMsgCycleTime" BO_ 945 1000;
BA_ "GenMsgSendType" BO_ 945 5;
BA_ "GenMsgCycleTime" BO_ 523 1000;
BA_ "GenMsgSendType" BO_ 523 0;
BA_ "FrameGatewayId" BO_ 360 360;
BA_ "FrameGatewayHS2" BO_ 360 360;
BA_ "FrameGatewayNetwork" BO_ 360 "HS2_CAN";
BA_ "FrameGatewayNetwork" BO_ 1053 "HS2_CAN";
BA_ "FrameGatewayHS2" BO_ 1053 1053;
BA_ "FrameGatewayId" BO_ 1053 1053;
BA_ "NetworkInitialization" BO_ 92 1;
BA_ "GenMsgSendType" BO_ 92 5;
BA_ "GenMsgCycleTime" BO_ 92 100;
BA_ "GenMsgCycleTime" BO_ 381 100;
BA_ "GenMsgSendType" BO_ 381 0;
BA_ "GenMsgCycleTime" BO_ 380 100;
BA_ "GenMsgSendType" BO_ 380 0;
BA_ "GenMsgDelayTime" BO_ 373 10;
BA_ "GenMsgCycleTime" BO_ 373 20;
BA_ "GenMsgSendType" BO_ 373 0;
BA_ "GenMsgCycleTime" BO_ 355 100;
BA_ "GenMsgSendType" BO_ 355 0;
BA_ "GenMsgCycleTime" BO_ 332 200;
BA_ "GenMsgSendType" BO_ 332 0;
BA_ "NetworkInitialization" BO_ 332 1;
BA_ "GenMsgILSupport" BO_ 1827 0;
BA_ "DiagRequest" BO_ 1827 1;
BA_ "GenMsgSendType" BO_ 1827 1;
BA_ "GenMsgDelayTime" BO_ 1827 0;
BA_ "GenMsgILSupport" BO_ 1458 0;
BA_ "NmAsrMessage" BO_ 1458 1;
BA_ "GenMsgSendType" BO_ 1458 1;
BA_ "GenMsgSendType" BO_ 1110 0;
BA_ "GenMsgCycleTime" BO_ 1110 1000;
BA_ "GenMsgILSupport" BO_ 1835 0;
BA_ "DiagResponse" BO_ 1835 1;
BA_ "GenMsgSendType" BO_ 1835 1;
BA_ "GenMsgDelayTime" BO_ 1835 0;
BA_ "GenMsgSendType" BO_ 1071 0;
BA_ "GenMsgCycleTime" BO_ 1071 30;
BA_ "GenMsgDelayTime" BO_ 1071 10;
BA_ "NetworkInitialization" BO_ 1071 1;
BA_ "GenMsgDelayTime" BO_ 2017 0;
BA_ "GenMsgSendType" BO_ 2017 1;
BA_ "DiagRequest" BO_ 2017 1;
BA_ "GenMsgILSupport" BO_ 2017 0;
BA_ "GenMsgDelayTime" BO_ 2025 0;
BA_ "GenMsgSendType" BO_ 2025 1;
BA_ "DiagResponse" BO_ 2025 1;
BA_ "GenMsgILSupport" BO_ 2025 0;
BA_ "GenMsgSendType" BO_ 1701 1;
BA_ "TpApplType" BO_ 1701 "DiagUUDTResponse";
BA_ "GenMsgILSupport" BO_ 1701 0;
BA_ "GenMsgSendType" BO_ 1700 1;
BA_ "TpApplType" BO_ 1700 "DiagUUDTResponse";
BA_ "GenMsgILSupport" BO_ 1700 0;
BA_ "GenMsgCycleTime" BO_ 561 100;
BA_ "GenMsgSendType" BO_ 561 0;
BA_ "NetworkInitialization" BO_ 561 1;
BA_ "GenMsgDelayTime" BO_ 370 10;
BA_ "GenMsgCycleTime" BO_ 370 30;
BA_ "GenMsgSendType" BO_ 370 0;
BA_ "GenMsgCycleTime" BO_ 1440 1000;
BA_ "GenMsgSendType" BO_ 1440 0;
BA_ "NmAsrMessage" BO_ 1440 1;
BA_ "GenMsgILSupport" BO_ 1440 0;
BA_ "GenMsgDelayTime" BO_ 330 0;
BA_ "GenMsgCycleTime" BO_ 330 10;
BA_ "GenMsgSendType" BO_ 330 0;
BA_ "NetworkInitialization" BO_ 532 1;
BA_ "FrameGatewayNetwork" BO_ 532 "HS2_CAN";
BA_ "FrameGatewayHS2" BO_ 532 532;
BA_ "FrameGatewayId" BO_ 532 532;
BA_ "GenMsgDelayTime" BO_ 532 10;
BA_ "NetworkInitialization" BO_ 1060 1;
BA_ "GenMsgCycleTime" BO_ 1060 100;
BA_ "GenMsgSendType" BO_ 1060 0;
BA_ "GenMsgCycleTime" BO_ 1081 1000;
BA_ "GenMsgSendType" BO_ 1081 5;
BA_ "NetworkInitialization" BO_ 1081 1;
BA_ "U_U55x_MY18_Gas_Rx" SG_ 1082 EmPrflNo_D_Rq_UB 1;
BA_ "U_CD4_MY19_Diesel_Rx" SG_ 1082 EmPrflNo_D_Rq_UB 1;
BA_ "U_CD4_MY19_Gas_Rx" SG_ 1082 EmPrflNo_D_Rq_UB 1;
BA_ "U_CD4_MY19_Hev_Rx" SG_ 1082 EmPrflNo_D_Rq_UB 1;
BA_ "U_CD4_MY19_Phev_Rx" SG_ 1082 EmPrflNo_D_Rq_UB 1;
BA_ "U_S550_MY18_Gas_Rx" SG_ 1082 EmPrflNo_D_Rq_UB 1;
BA_ "U_V408_MY18_Gas_Rx" SG_ 1082 EmPrflNo_D_Rq_UB 1;
BA_ "U_V408_MY18_Diesel_Rx" SG_ 1082 EmPrflNo_D_Rq_UB 1;
BA_ "U_V36X_MY19_Rx" SG_ 1082 EmPrflNo_D_Rq_UB 1;
BA_ "U_P552_MY18_5_Gas_Rx" SG_ 1082 EmPrflNo_D_Rq_UB 1;
BA_ "U_P552_MY18_5_Diesel_Rx" SG_ 1082 EmPrflNo_D_Rq_UB 1;
BA_ "U_V363E_N_MY19_5_20_Gas_Rx" SG_ 1082 EmPrflNo_D_Rq_UB 1;
BA_ "U_V363E_N_MY19_5_20_Diesel_Rx" SG_ 1082 EmPrflNo_D_Rq_UB 1;
BA_ "GenSigSendType" SG_ 1082 EmPrflNo_D_Rq 3;
BA_ "U_U55x_MY18_Gas_Rx" SG_ 1082 EmPrflNo_D_Rq 1;
BA_ "U_CD4_MY19_Diesel_Rx" SG_ 1082 EmPrflNo_D_Rq 1;
BA_ "U_CD4_MY19_Gas_Rx" SG_ 1082 EmPrflNo_D_Rq 1;
BA_ "U_CD4_MY19_Hev_Rx" SG_ 1082 EmPrflNo_D_Rq 1;
BA_ "U_CD4_MY19_Phev_Rx" SG_ 1082 EmPrflNo_D_Rq 1;
BA_ "U_S550_MY18_Gas_Rx" SG_ 1082 EmPrflNo_D_Rq 1;
BA_ "U_V408_MY18_Gas_Rx" SG_ 1082 EmPrflNo_D_Rq 1;
BA_ "U_V408_MY18_Diesel_Rx" SG_ 1082 EmPrflNo_D_Rq 1;
BA_ "U_V36X_MY19_Rx" SG_ 1082 EmPrflNo_D_Rq 1;
BA_ "U_P552_MY18_5_Gas_Rx" SG_ 1082 EmPrflNo_D_Rq 1;
BA_ "U_P552_MY18_5_Diesel_Rx" SG_ 1082 EmPrflNo_D_Rq 1;
BA_ "U_V363E_N_MY19_5_20_Gas_Rx" SG_ 1082 EmPrflNo_D_Rq 1;
BA_ "U_V363E_N_MY19_5_20_Diesel_Rx" SG_ 1082 EmPrflNo_D_Rq 1;
BA_ "U_U55x_MY18_Gas_Rx" SG_ 1082 EmPrflKeyAssoc_D_Rq_UB 1;
BA_ "U_CD4_MY19_Diesel_Rx" SG_ 1082 EmPrflKeyAssoc_D_Rq_UB 1;
BA_ "U_CD4_MY19_Gas_Rx" SG_ 1082 EmPrflKeyAssoc_D_Rq_UB 1;
BA_ "U_CD4_MY19_Hev_Rx" SG_ 1082 EmPrflKeyAssoc_D_Rq_UB 1;
BA_ "U_CD4_MY19_Phev_Rx" SG_ 1082 EmPrflKeyAssoc_D_Rq_UB 1;
BA_ "U_S550_MY18_Gas_Rx" SG_ 1082 EmPrflKeyAssoc_D_Rq_UB 1;
BA_ "U_V408_MY18_Gas_Rx" SG_ 1082 EmPrflKeyAssoc_D_Rq_UB 1;
BA_ "U_V408_MY18_Diesel_Rx" SG_ 1082 EmPrflKeyAssoc_D_Rq_UB 1;
BA_ "U_V36X_MY19_Rx" SG_ 1082 EmPrflKeyAssoc_D_Rq_UB 1;
BA_ "U_P552_MY18_5_Gas_Rx" SG_ 1082 EmPrflKeyAssoc_D_Rq_UB 1;
BA_ "U_P552_MY18_5_Diesel_Rx" SG_ 1082 EmPrflKeyAssoc_D_Rq_UB 1;
BA_ "U_V363E_N_MY19_5_20_Gas_Rx" SG_ 1082 EmPrflKeyAssoc_D_Rq_UB 1;
BA_ "U_V363E_N_MY19_5_20_Diesel_Rx" SG_ 1082 EmPrflKeyAssoc_D_Rq_UB 1;
BA_ "GenSigSendType" SG_ 1082 EmPrflKeyAssoc_D_Rq 3;
BA_ "U_U55x_MY18_Gas_Rx" SG_ 1082 EmPrflKeyAssoc_D_Rq 1;
BA_ "U_CD4_MY19_Diesel_Rx" SG_ 1082 EmPrflKeyAssoc_D_Rq 1;
BA_ "U_CD4_MY19_Gas_Rx" SG_ 1082 EmPrflKeyAssoc_D_Rq 1;
BA_ "U_CD4_MY19_Hev_Rx" SG_ 1082 EmPrflKeyAssoc_D_Rq 1;
BA_ "U_CD4_MY19_Phev_Rx" SG_ 1082 EmPrflKeyAssoc_D_Rq 1;
BA_ "U_S550_MY18_Gas_Rx" SG_ 1082 EmPrflKeyAssoc_D_Rq 1;
BA_ "U_V408_MY18_Gas_Rx" SG_ 1082 EmPrflKeyAssoc_D_Rq 1;
BA_ "U_V408_MY18_Diesel_Rx" SG_ 1082 EmPrflKeyAssoc_D_Rq 1;
BA_ "U_V36X_MY19_Rx" SG_ 1082 EmPrflKeyAssoc_D_Rq 1;
BA_ "U_P552_MY18_5_Gas_Rx" SG_ 1082 EmPrflKeyAssoc_D_Rq 1;
BA_ "U_P552_MY18_5_Diesel_Rx" SG_ 1082 EmPrflKeyAssoc_D_Rq 1;
BA_ "U_V363E_N_MY19_5_20_Gas_Rx" SG_ 1082 EmPrflKeyAssoc_D_Rq 1;
BA_ "U_V363E_N_MY19_5_20_Diesel_Rx" SG_ 1082 EmPrflKeyAssoc_D_Rq 1;
BA_ "U_U55x_MY18_Gas_Rx" SG_ 1082 HMI_HMIMode_St_UB 1;
BA_ "U_CD4_MY19_Diesel_Rx" SG_ 1082 HMI_HMIMode_St_UB 1;
BA_ "U_CD4_MY19_Gas_Rx" SG_ 1082 HMI_HMIMode_St_UB 1;
BA_ "U_CD4_MY19_Hev_Rx" SG_ 1082 HMI_HMIMode_St_UB 1;
BA_ "U_CD4_MY19_Phev_Rx" SG_ 1082 HMI_HMIMode_St_UB 1;
BA_ "U_S550_MY18_Gas_Rx" SG_ 1082 HMI_HMIMode_St_UB 1;
BA_ "U_V408_MY18_Gas_Rx" SG_ 1082 HMI_HMIMode_St_UB 1;
BA_ "U_V408_MY18_Diesel_Rx" SG_ 1082 HMI_HMIMode_St_UB 1;
BA_ "U_V36X_MY19_Rx" SG_ 1082 HMI_HMIMode_St_UB 1;
BA_ "U_P552_MY18_5_Gas_Rx" SG_ 1082 HMI_HMIMode_St_UB 1;
BA_ "U_P552_MY18_5_Diesel_Rx" SG_ 1082 HMI_HMIMode_St_UB 1;
BA_ "U_V363E_N_MY19_5_20_Gas_Rx" SG_ 1082 HMI_HMIMode_St_UB 1;
BA_ "U_V363E_N_MY19_5_20_Diesel_Rx" SG_ 1082 HMI_HMIMode_St_UB 1;
BA_ "GenSigSendType" SG_ 1082 HMI_HMIMode_St 3;
BA_ "WakeupSignal" SG_ 1082 HMI_HMIMode_St 1;
BA_ "CrossOver_InfoCAN" SG_ 1082 HMI_HMIMode_St 1;
BA_ "U_U55x_MY18_Gas_Rx" SG_ 1082 HMI_HMIMode_St 1;
BA_ "U_CD4_MY19_Diesel_Rx" SG_ 1082 HMI_HMIMode_St 1;
BA_ "U_CD4_MY19_Gas_Rx" SG_ 1082 HMI_HMIMode_St 1;
BA_ "U_CD4_MY19_Hev_Rx" SG_ 1082 HMI_HMIMode_St 1;
BA_ "U_CD4_MY19_Phev_Rx" SG_ 1082 HMI_HMIMode_St 1;
BA_ "U_S550_MY18_Gas_Rx" SG_ 1082 HMI_HMIMode_St 1;
BA_ "U_V408_MY18_Gas_Rx" SG_ 1082 HMI_HMIMode_St 1;
BA_ "U_V408_MY18_Diesel_Rx" SG_ 1082 HMI_HMIMode_St 1;
BA_ "U_V36X_MY19_Rx" SG_ 1082 HMI_HMIMode_St 1;
BA_ "U_P552_MY18_5_Gas_Rx" SG_ 1082 HMI_HMIMode_St 1;
BA_ "U_P552_MY18_5_Diesel_Rx" SG_ 1082 HMI_HMIMode_St 1;
BA_ "U_V363E_N_MY19_5_20_Gas_Rx" SG_ 1082 HMI_HMIMode_St 1;
BA_ "U_V363E_N_MY19_5_20_Diesel_Rx" SG_ 1082 HMI_HMIMode_St 1;
BA_ "GenSigStartValue" SG_ 1100 GrossTrainWeight_M_Est 254;
BA_ "U_CD4_MY17_Diesel_Rx" SG_ 1100 GrossTrainWeight_M_Est 1;
BA_ "U_U55x_MY18_Gas_Rx" SG_ 1100 GrossTrainWeight_M_Est 1;
BA_ "U_V408_MY18_Diesel_Rx" SG_ 1100 GrossTrainWeight_M_Est 1;
BA_ "U_CD42_MY19_Diesel_Rx" SG_ 1100 GrossTrainWeight_M_Est 1;
BA_ "U_U55x_MY18_Gas_Tx" SG_ 1100 GrossTrainWeight_M_Est 1;
BA_ "U_V36X_MY19_Tx" SG_ 1100 GrossTrainWeight_M_Est 1;
BA_ "MetaData" SG_ 145 VehYawWActl_D_Qf 1;
BA_ "GenSigStartValue" SG_ 145 VehYawWActl_D_Qf 1;
BA_ "MetaData" SG_ 145 VehRolWActl_D_Qf 1;
BA_ "GenSigStartValue" SG_ 145 VehRolWActl_D_Qf 1;
BA_ "MetaData" SG_ 145 VehRollYaw_No_Cnt 1;
BA_ "U_UP375_MY18_Gas_Rx" SG_ 145 VehYaw_W_Actl 1;
BA_ "U_UP375_MY18_Diesel_Rx" SG_ 145 VehYaw_W_Actl 1;
BA_ "U_V36X_MY18_5_Gas_Rx" SG_ 145 VehYaw_W_Actl 1;
BA_ "U_V36X_MY18_5_Hev_Rx" SG_ 145 VehYaw_W_Actl 1;
BA_ "U_V36X_MY19_5_Diesel_Rx" SG_ 145 VehYaw_W_Actl 1;
BA_ "U_V408_MY18_Gas_Rx" SG_ 145 VehYaw_W_Actl 1;
BA_ "U_V408_MY18_Diesel_Rx" SG_ 145 VehYaw_W_Actl 1;
BA_ "U_V36X_MY18_5_Diesel_Rx" SG_ 145 VehYaw_W_Actl 1;
BA_ "U_U55x_MY18_Gas_Rx" SG_ 145 VehYaw_W_Actl 1;
BA_ "U_C489_MY17_Gas_Rx" SG_ 145 VehYaw_W_Actl 1;
BA_ "U_CD43_MY17_Gas_Rx" SG_ 145 VehYaw_W_Actl 1;
BA_ "U_CD42_MY16_Diesel_Rx" SG_ 145 VehYaw_W_Actl 1;
BA_ "U_CD42_MY16_Gas_Rx" SG_ 145 VehYaw_W_Actl 1;
BA_ "U_CD42_MY15_Diesel_Rx" SG_ 145 VehYaw_W_Actl 1;
BA_ "U_CD42_MY15_Gas_Rx" SG_ 145 VehYaw_W_Actl 1;
BA_ "U_U502_MY16_Gas_Rx" SG_ 145 VehYaw_W_Actl 1;
BA_ "U_V36X_MY16_5_Diesel_Rx" SG_ 145 VehYaw_W_Actl 1;
BA_ "U_CD4_MY14_Phev_Rx" SG_ 145 VehYaw_W_Actl 1;
BA_ "U_CD4_MY14_Hev_Rx" SG_ 145 VehYaw_W_Actl 1;
BA_ "U_CD4_MY14_Gas_Rx" SG_ 145 VehYaw_W_Actl 1;
BA_ "U_CD4_MY14_Diesel_Rx" SG_ 145 VehYaw_W_Actl 1;
BA_ "U_CD43_MY16_Gas_Rx" SG_ 145 VehYaw_W_Actl 1;
BA_ "U_C489_MY14_Gas_Rx" SG_ 145 VehYaw_W_Actl 1;
BA_ "U_CD4_MY13_Phev_Rx" SG_ 145 VehYaw_W_Actl 1;
BA_ "U_CD4_MY13_Hev_Rx" SG_ 145 VehYaw_W_Actl 1;
BA_ "U_CD4_MY13_Gas_Rx" SG_ 145 VehYaw_W_Actl 1;
BA_ "U_CD4_MY13_Diesel_Rx" SG_ 145 VehYaw_W_Actl 1;
BA_ "GenSigStartValue" SG_ 145 VehYaw_W_Actl 65534;
BA_ "GenSigStartValue" SG_ 145 VehRol_W_Actl 65534;
BA_ "GenSigSendType" SG_ 145 VehRol_W_Actl 1;
BA_ "MetaData" SG_ 145 VehRollYawW_No_Cs 1;
BA_ "GenSigStartValue" SG_ 980 AdbBrdr1Up_An_Rq 510;
BA_ "GenSigStartValue" SG_ 980 AdbBrdr1Right_An_Rq 2046;
BA_ "GenSigStartValue" SG_ 980 AdbBrdr1Low_An_Rq 510;
BA_ "GenSigStartValue" SG_ 980 AdbBrdr1Left_An_Rq 2046;
BA_ "GenSigStartValue" SG_ 985 IaccVLimUnit_D_Rq 3;
BA_ "U_V408_MY18_Diesel_Rx" SG_ 985 IaccVLimUnit_D_Rq 1;
BA_ "GenSigStartValue" SG_ 985 IaccVLim_D_Rq 254;
BA_ "U_V408_MY18_Diesel_Rx" SG_ 985 IaccVLim_D_Rq 1;
BA_ "U_CD4_MY18_Diesel_Rx" SG_ 985 IsaVLimUnit_D_Rq 1;
BA_ "U_V408_MY18_Diesel_Rx" SG_ 985 IsaVLimUnit_D_Rq 1;
BA_ "U_V36X_MY18_5_Diesel_Rx" SG_ 985 IsaVLimUnit_D_Rq 1;
BA_ "U_V36X_MY19_5_Diesel_Rx" SG_ 985 IsaVLimUnit_D_Rq 1;
BA_ "U_V363E_N_MY19_5_20_Gas_Rx" SG_ 985 IsaVLimUnit_D_Rq 1;
BA_ "U_V363E_N_MY19_5_20_Diesel_Rx" SG_ 985 IsaVLimUnit_D_Rq 1;
BA_ "GenSigStartValue" SG_ 985 IsaVLim_D_Rq 254;
BA_ "U_CD4_MY18_Diesel_Rx" SG_ 985 IsaVLim_D_Rq 1;
BA_ "U_V408_MY18_Diesel_Rx" SG_ 985 IsaVLim_D_Rq 1;
BA_ "U_V36X_MY18_5_Diesel_Rx" SG_ 985 IsaVLim_D_Rq 1;
BA_ "U_V36X_MY19_5_Diesel_Rx" SG_ 985 IsaVLim_D_Rq 1;
BA_ "U_V363E_N_MY19_5_20_Gas_Rx" SG_ 985 IsaVLim_D_Rq 1;
BA_ "U_V363E_N_MY19_5_20_Diesel_Rx" SG_ 985 IsaVLim_D_Rq 1;
BA_ "GenSigStartValue" SG_ 962 AdbBrdr3Up_An_Rq 400;
BA_ "GenSigStartValue" SG_ 962 AdbBrdr3Right_An_Rq 1000;
BA_ "GenSigStartValue" SG_ 962 AdbBrdr3Low_An_Rq 400;
BA_ "GenSigStartValue" SG_ 962 AdbBrdr3Left_An_Rq 1000;
BA_ "GenSigStartValue" SG_ 961 AdbBrdr2Up_An_Rq 400;
BA_ "GenSigStartValue" SG_ 961 AdbBrdr2Right_An_Rq 1000;
BA_ "GenSigStartValue" SG_ 961 AdbBrdr2Low_An_Rq 400;
BA_ "GenSigStartValue" SG_ 961 AdbBrdr2Left_An_Rq 1000;
BA_ "CrossOver_InfoCAN" SG_ 984 AhbcHiBeam_D_Rq 1;
BA_ "CrossOver_InfoCAN" SG_ 984 DasWarn_D_Dsply 1;
BA_ "CrossOver_InfoCAN" SG_ 984 DasStats_D_Dsply 1;
BA_ "CrossOver_InfoCAN" SG_ 984 DasAlrtLvl_D_Dsply 1;
BA_ "CrossOver_InfoCAN" SG_ 984 CamraStats_D_Dsply 1;
BA_ "CrossOver_InfoCAN" SG_ 984 CamraDefog_B_Req 1;
BA_ "CrossOver_InfoCAN" SG_ 984 LaHandsOff_D_Dsply 1;
BA_ "CrossOver_InfoCAN" SG_ 984 LaDenyStats_B_Dsply 1;
BA_ "CrossOver_InfoCAN" SG_ 984 LaActvStats_D_Dsply 1;
BA_ "GenSigStartValue" SG_ 984 PersIndexIpma_D_Actl 4;
BA_ "CrossOver_InfoCAN" SG_ 984 PersIndexIpma_D_Actl 1;
BA_ "CrossOver_InfoCAN" SG_ 984 FeatNoIpmaActl 1;
BA_ "CrossOver_InfoCAN" SG_ 984 FeatConfigIpmaActl 1;
BA_ "U_V36X_MY18_5_Hev_Tx" SG_ 945 KeyOffMde_D_Actl 1;
BA_ "U_V36X_MY18_5_Gas_Tx" SG_ 945 KeyOffMde_D_Actl 1;
BA_ "U_V363E_N_MY19_5_20_Diesel_Tx" SG_ 945 KeyOffMde_D_Actl 1;
BA_ "U_V363E_N_MY19_5_20_Gas_Tx" SG_ 945 KeyOffMde_D_Actl 1;
BA_ "U_V36X_MY19_5_Diesel_Tx" SG_ 945 KeyOffMde_D_Actl 1;
BA_ "U_P552_MY18_5_Diesel_Tx" SG_ 945 KeyOffMde_D_Actl 1;
BA_ "U_P552_MY18_5_Gas_Tx" SG_ 945 KeyOffMde_D_Actl 1;
BA_ "U_V36X_MY18_5_Diesel_Tx" SG_ 945 KeyOffMde_D_Actl 1;
BA_ "U_V408_MY18_Diesel_Tx" SG_ 945 KeyOffMde_D_Actl 1;
BA_ "U_V408_MY18_Gas_Tx" SG_ 945 KeyOffMde_D_Actl 1;
BA_ "U_S550_MY18_Gas_Tx" SG_ 945 KeyOffMde_D_Actl 1;
BA_ "U_U55x_MY18_Gas_Tx" SG_ 945 KeyOffMde_D_Actl 1;
BA_ "U_P552_MY18_Gas_Tx" SG_ 945 KeyOffMde_D_Actl 1;
BA_ "GenSigSendType" SG_ 945 KeyOffMde_D_Actl 3;
BA_ "CrossOver_InfoCAN" SG_ 523 VehUreaRnge3_L_DsplyMx 1;
BA_ "CrossOver_InfoCAN" SG_ 360 GsmSrvcRqd_B_Rq 1;
BA_ "ContentDependant" SG_ 360 GsmSrvcRqd_B_Rq 1;
BA_ "U_U55x_MY18_Gas_Rx" SG_ 360 GsmSrvcRqd_B_Rq 1;
BA_ "CrossOver_InfoCAN" SG_ 360 TrnGearPwmFalt_B_Actl 1;
BA_ "ContentDependant" SG_ 360 TrnGearPwmFalt_B_Actl 1;
BA_ "U_CD4_MY13_Hev_Rx" SG_ 360 TrnGearPwmFalt_B_Actl 1;
BA_ "U_CD43_MY16_Gas_Rx" SG_ 360 TrnGearPwmFalt_B_Actl 1;
BA_ "U_CD4_MY14_Gas_Rx" SG_ 360 TrnGearPwmFalt_B_Actl 1;
BA_ "U_CD4_MY14_Hev_Rx" SG_ 360 TrnGearPwmFalt_B_Actl 1;
BA_ "U_CD4_MY17_Gas_Rx" SG_ 360 TrnGearPwmFalt_B_Actl 1;
BA_ "U_CD4_MY17_Hev_Rx" SG_ 360 TrnGearPwmFalt_B_Actl 1;
BA_ "U_C489_MY17_Gas_Rx" SG_ 360 TrnGearPwmFalt_B_Actl 1;
BA_ "U_CD42_MY16_Gas_Rx" SG_ 360 TrnGearPwmFalt_B_Actl 1;
BA_ "U_CD43_MY17_Gas_Rx" SG_ 360 TrnGearPwmFalt_B_Actl 1;
BA_ "U_U55x_MY18_Gas_Rx" SG_ 360 TrnGearPwmFalt_B_Actl 1;
BA_ "U_CD4_MY18_Gas_Rx" SG_ 360 TrnGearPwmFalt_B_Actl 1;
BA_ "U_V408_MY18_Gas_Rx" SG_ 360 TrnGearPwmFalt_B_Actl 1;
BA_ "CrossOver_InfoCAN" SG_ 360 GearButtnStuck_B_Actl 1;
BA_ "ContentDependant" SG_ 360 GearButtnStuck_B_Actl 1;
BA_ "U_CD4_MY13_Hev_Rx" SG_ 360 GearButtnStuck_B_Actl 1;
BA_ "U_CD43_MY16_Gas_Rx" SG_ 360 GearButtnStuck_B_Actl 1;
BA_ "U_CD4_MY14_Gas_Rx" SG_ 360 GearButtnStuck_B_Actl 1;
BA_ "U_CD4_MY14_Hev_Rx" SG_ 360 GearButtnStuck_B_Actl 1;
BA_ "U_CD4_MY17_Gas_Rx" SG_ 360 GearButtnStuck_B_Actl 1;
BA_ "U_CD4_MY17_Hev_Rx" SG_ 360 GearButtnStuck_B_Actl 1;
BA_ "U_C489_MY17_Gas_Rx" SG_ 360 GearButtnStuck_B_Actl 1;
BA_ "U_CD42_MY16_Gas_Rx" SG_ 360 GearButtnStuck_B_Actl 1;
BA_ "U_CD43_MY17_Gas_Rx" SG_ 360 GearButtnStuck_B_Actl 1;
BA_ "U_U55x_MY18_Gas_Rx" SG_ 360 GearButtnStuck_B_Actl 1;
BA_ "U_CD4_MY18_Gas_Rx" SG_ 360 GearButtnStuck_B_Actl 1;
BA_ "U_V408_MY18_Gas_Rx" SG_ 360 GearButtnStuck_B_Actl 1;
BA_ "U_CD42_MY19_Diesel_Rx" SG_ 360 GearButtnStuck_B_Actl 1;
BA_ "U_U55x_MY18_Gas_Rx" SG_ 1053 VehStab_D_Stat 1;
BA_ "U_CD43_MY17_Gas_Rx" SG_ 1053 VehStab_D_Stat 1;
BA_ "U_CD42_MY16_Gas_Rx" SG_ 1053 VehStab_D_Stat 1;
BA_ "U_CD42_MY16_Diesel_Rx" SG_ 1053 VehStab_D_Stat 1;
BA_ "U_CD4_MY17_Gas_Rx" SG_ 1053 VehStab_D_Stat 1;
BA_ "U_CD43_MY16_Gas_Rx" SG_ 1053 VehStab_D_Stat 1;
BA_ "GenSigStartValue" SG_ 1053 VehStab_D_Stat 14;
BA_ "GenSigSendType" SG_ 92 TrnValidGear_D_Cnfm 3;
BA_ "ContentDependant" SG_ 92 TrnValidGear_D_Cnfm 1;
BA_ "U_CD43_MY16_Gas_Tx" SG_ 92 TrnValidGear_D_Cnfm 1;
BA_ "U_CD4_MY14_Gas_Tx" SG_ 92 TrnValidGear_D_Cnfm 1;
BA_ "U_CD4_MY14_Hev_Tx" SG_ 92 TrnValidGear_D_Cnfm 1;
BA_ "U_CD4_MY17_Gas_Tx" SG_ 92 TrnValidGear_D_Cnfm 1;
BA_ "U_CD4_MY17_Hev_Tx" SG_ 92 TrnValidGear_D_Cnfm 1;
BA_ "U_C489_MY17_Gas_Tx" SG_ 92 TrnValidGear_D_Cnfm 1;
BA_ "U_CD42_MY16_Gas_Tx" SG_ 92 TrnValidGear_D_Cnfm 1;
BA_ "U_CD43_MY17_Gas_Tx" SG_ 92 TrnValidGear_D_Cnfm 1;
BA_ "U_P552_MY17_Gas_Tx" SG_ 92 TrnValidGear_D_Cnfm 1;
BA_ "U_P552_MY18_Gas_Tx" SG_ 92 TrnValidGear_D_Cnfm 1;
BA_ "U_U55x_MY18_Gas_Tx" SG_ 92 TrnValidGear_D_Cnfm 1;
BA_ "GenSigSendType" SG_ 92 TrnSbwSysHlth_D_Actl 3;
BA_ "GenSigStartValue" SG_ 92 TrnSbwSysHlth_D_Actl 1;
BA_ "ContentDependant" SG_ 92 TrnSbwSysHlth_D_Actl 1;
BA_ "U_CD4_MY13_Diesel_Rx" SG_ 92 TrnSbwSysHlth_D_Actl 1;
BA_ "U_CD4_MY13_Hev_Rx" SG_ 92 TrnSbwSysHlth_D_Actl 1;
BA_ "U_CD4_MY13_Phev_Rx" SG_ 92 TrnSbwSysHlth_D_Actl 1;
BA_ "U_CD42_MY15_Diesel_Rx" SG_ 92 TrnSbwSysHlth_D_Actl 1;
BA_ "U_CD4_MY14_Diesel_Rx" SG_ 92 TrnSbwSysHlth_D_Actl 1;
BA_ "U_CD4_MY14_Hev_Rx" SG_ 92 TrnSbwSysHlth_D_Actl 1;
BA_ "U_CD4_MY14_Phev_Rx" SG_ 92 TrnSbwSysHlth_D_Actl 1;
BA_ "U_CD4_MY17_Diesel_Rx" SG_ 92 TrnSbwSysHlth_D_Actl 1;
BA_ "U_CD4_MY17_Hev_Rx" SG_ 92 TrnSbwSysHlth_D_Actl 1;
BA_ "U_CD4_MY17_Phev_Rx" SG_ 92 TrnSbwSysHlth_D_Actl 1;
BA_ "U_CD42_MY16_Diesel_Rx" SG_ 92 TrnSbwSysHlth_D_Actl 1;
BA_ "U_CD42_MY16_Gas_Rx" SG_ 92 TrnSbwSysHlth_D_Actl 1;
BA_ "U_P552_MY17_Gas_Tx" SG_ 92 TrnSbwSysHlth_D_Actl 1;
BA_ "U_P552_MY18_Gas_Tx" SG_ 92 TrnSbwSysHlth_D_Actl 1;
BA_ "U_U55x_MY18_Gas_Tx" SG_ 92 TrnSbwSysHlth_D_Actl 1;
BA_ "GenSigSendType" SG_ 92 TrnNtrlTowCmd_D_Actl 3;
BA_ "ContentDependant" SG_ 92 TrnNtrlTowCmd_D_Actl 1;
BA_ "U_CD43_MY16_Gas_Tx" SG_ 92 TrnNtrlTowCmd_D_Actl 1;
BA_ "U_CD4_MY14_Gas_Tx" SG_ 92 TrnNtrlTowCmd_D_Actl 1;
BA_ "U_CD4_MY14_Hev_Tx" SG_ 92 TrnNtrlTowCmd_D_Actl 1;
BA_ "U_CD4_MY17_Gas_Tx" SG_ 92 TrnNtrlTowCmd_D_Actl 1;
BA_ "U_CD4_MY17_Hev_Tx" SG_ 92 TrnNtrlTowCmd_D_Actl 1;
BA_ "U_C489_MY17_Gas_Tx" SG_ 92 TrnNtrlTowCmd_D_Actl 1;
BA_ "U_CD42_MY16_Gas_Tx" SG_ 92 TrnNtrlTowCmd_D_Actl 1;
BA_ "U_CD43_MY17_Gas_Tx" SG_ 92 TrnNtrlTowCmd_D_Actl 1;
BA_ "U_P552_MY17_Gas_Tx" SG_ 92 TrnNtrlTowCmd_D_Actl 1;
BA_ "U_P552_MY18_Gas_Tx" SG_ 92 TrnNtrlTowCmd_D_Actl 1;
BA_ "U_U55x_MY18_Gas_Tx" SG_ 92 TrnNtrlTowCmd_D_Actl 1;
BA_ "GenSigStartValue" SG_ 92 TrnLvrV_D_Rq 1;
BA_ "U_CD4_MY13_Gas_Tx" SG_ 92 TrnLvrV_D_Rq 1;
BA_ "U_CD4_MY13_Hev_Tx" SG_ 92 TrnLvrV_D_Rq 1;
BA_ "U_CD42_MY15_Gas_Tx" SG_ 92 TrnLvrV_D_Rq 1;
BA_ "U_C489_MY14_Gas_Tx" SG_ 92 TrnLvrV_D_Rq 1;
BA_ "U_CD43_MY16_Gas_Tx" SG_ 92 TrnLvrV_D_Rq 1;
BA_ "U_CD4_MY14_Gas_Tx" SG_ 92 TrnLvrV_D_Rq 1;
BA_ "U_CD4_MY14_Hev_Tx" SG_ 92 TrnLvrV_D_Rq 1;
BA_ "U_CD4_MY17_Gas_Tx" SG_ 92 TrnLvrV_D_Rq 1;
BA_ "U_CD4_MY17_Hev_Tx" SG_ 92 TrnLvrV_D_Rq 1;
BA_ "U_C489_MY17_Gas_Tx" SG_ 92 TrnLvrV_D_Rq 1;
BA_ "U_CD42_MY16_Gas_Tx" SG_ 92 TrnLvrV_D_Rq 1;
BA_ "U_CD43_MY17_Gas_Tx" SG_ 92 TrnLvrV_D_Rq 1;
BA_ "U_P552_MY17_Gas_Tx" SG_ 92 TrnLvrV_D_Rq 1;
BA_ "U_P552_MY18_Gas_Tx" SG_ 92 TrnLvrV_D_Rq 1;
BA_ "U_U55x_MY18_Gas_Tx" SG_ 92 TrnLvrV_D_Rq 1;
BA_ "GenSigSendType" SG_ 92 TrnGear_D_RqPt 3;
BA_ "ContentDependant" SG_ 92 TrnGear_D_RqPt 1;
BA_ "U_CD43_MY16_Gas_Tx" SG_ 92 TrnGear_D_RqPt 1;
BA_ "U_CD4_MY14_Gas_Tx" SG_ 92 TrnGear_D_RqPt 1;
BA_ "U_CD4_MY14_Hev_Tx" SG_ 92 TrnGear_D_RqPt 1;
BA_ "U_CD4_MY17_Gas_Tx" SG_ 92 TrnGear_D_RqPt 1;
BA_ "U_CD4_MY17_Hev_Tx" SG_ 92 TrnGear_D_RqPt 1;
BA_ "U_C489_MY17_Gas_Tx" SG_ 92 TrnGear_D_RqPt 1;
BA_ "U_CD42_MY16_Gas_Tx" SG_ 92 TrnGear_D_RqPt 1;
BA_ "U_CD43_MY17_Gas_Tx" SG_ 92 TrnGear_D_RqPt 1;
BA_ "U_P552_MY17_Gas_Tx" SG_ 92 TrnGear_D_RqPt 1;
BA_ "U_P552_MY18_Gas_Tx" SG_ 92 TrnGear_D_RqPt 1;
BA_ "U_U55x_MY18_Gas_Tx" SG_ 92 TrnGear_D_RqPt 1;
BA_ "GenSigSendType" SG_ 92 TrnGearNtmAllow_B_Stat 3;
BA_ "CrossOver_InfoCAN" SG_ 92 TrnGearNtmAllow_B_Stat 1;
BA_ "ContentDependant" SG_ 92 TrnGearNtmAllow_B_Stat 1;
BA_ "U_CD43_MY16_Gas_Tx" SG_ 92 TrnGearNtmAllow_B_Stat 1;
BA_ "U_CD4_MY14_Gas_Tx" SG_ 92 TrnGearNtmAllow_B_Stat 1;
BA_ "U_CD4_MY14_Hev_Tx" SG_ 92 TrnGearNtmAllow_B_Stat 1;
BA_ "U_CD4_MY17_Gas_Tx" SG_ 92 TrnGearNtmAllow_B_Stat 1;
BA_ "U_CD4_MY17_Hev_Tx" SG_ 92 TrnGearNtmAllow_B_Stat 1;
BA_ "U_C489_MY17_Gas_Tx" SG_ 92 TrnGearNtmAllow_B_Stat 1;
BA_ "U_CD42_MY16_Gas_Tx" SG_ 92 TrnGearNtmAllow_B_Stat 1;
BA_ "U_CD43_MY17_Gas_Tx" SG_ 92 TrnGearNtmAllow_B_Stat 1;
BA_ "U_P552_MY17_Gas_Tx" SG_ 92 TrnGearNtmAllow_B_Stat 1;
BA_ "U_P552_MY18_Gas_Tx" SG_ 92 TrnGearNtmAllow_B_Stat 1;
BA_ "U_U55x_MY18_Gas_Tx" SG_ 92 TrnGearNtmAllow_B_Stat 1;
BA_ "GenSigSendType" SG_ 92 TrnGearMsgTxt_D_Rq 3;
BA_ "CrossOver_InfoCAN" SG_ 92 TrnGearMsgTxt_D_Rq 1;
BA_ "ContentDependant" SG_ 92 TrnGearMsgTxt_D_Rq 1;
BA_ "U_CD43_MY16_Gas_Tx" SG_ 92 TrnGearMsgTxt_D_Rq 1;
BA_ "U_CD4_MY14_Gas_Tx" SG_ 92 TrnGearMsgTxt_D_Rq 1;
BA_ "U_CD4_MY14_Hev_Tx" SG_ 92 TrnGearMsgTxt_D_Rq 1;
BA_ "U_CD4_MY17_Gas_Tx" SG_ 92 TrnGearMsgTxt_D_Rq 1;
BA_ "U_CD4_MY17_Hev_Tx" SG_ 92 TrnGearMsgTxt_D_Rq 1;
BA_ "U_C489_MY17_Gas_Tx" SG_ 92 TrnGearMsgTxt_D_Rq 1;
BA_ "U_CD42_MY16_Gas_Tx" SG_ 92 TrnGearMsgTxt_D_Rq 1;
BA_ "U_CD43_MY17_Gas_Tx" SG_ 92 TrnGearMsgTxt_D_Rq 1;
BA_ "U_P552_MY17_Gas_Tx" SG_ 92 TrnGearMsgTxt_D_Rq 1;
BA_ "U_P552_MY18_Gas_Tx" SG_ 92 TrnGearMsgTxt_D_Rq 1;
BA_ "U_U55x_MY18_Gas_Tx" SG_ 92 TrnGearMsgTxt_D_Rq 1;
BA_ "ContentDependant" SG_ 92 TrnGearCmd_Pc_ActlPt 1;
BA_ "U_CD43_MY16_Gas_Tx" SG_ 92 TrnGearCmd_Pc_ActlPt 1;
BA_ "U_CD4_MY14_Gas_Tx" SG_ 92 TrnGearCmd_Pc_ActlPt 1;
BA_ "U_CD4_MY14_Hev_Tx" SG_ 92 TrnGearCmd_Pc_ActlPt 1;
BA_ "U_CD4_MY17_Gas_Tx" SG_ 92 TrnGearCmd_Pc_ActlPt 1;
BA_ "U_CD4_MY17_Hev_Tx" SG_ 92 TrnGearCmd_Pc_ActlPt 1;
BA_ "U_C489_MY17_Gas_Tx" SG_ 92 TrnGearCmd_Pc_ActlPt 1;
BA_ "U_CD42_MY16_Gas_Tx" SG_ 92 TrnGearCmd_Pc_ActlPt 1;
BA_ "U_CD43_MY17_Gas_Tx" SG_ 92 TrnGearCmd_Pc_ActlPt 1;
BA_ "U_P552_MY17_Gas_Tx" SG_ 92 TrnGearCmd_Pc_ActlPt 1;
BA_ "U_P552_MY18_Gas_Tx" SG_ 92 TrnGearCmd_Pc_ActlPt 1;
BA_ "U_U55x_MY18_Gas_Tx" SG_ 92 TrnGearCmd_Pc_ActlPt 1;
BA_ "ContentDependant" SG_ 92 TrnGearCmd_No_Cs 1;
BA_ "U_CD43_MY16_Gas_Tx" SG_ 92 TrnGearCmd_No_Cs 1;
BA_ "U_CD4_MY14_Gas_Tx" SG_ 92 TrnGearCmd_No_Cs 1;
BA_ "U_CD4_MY14_Hev_Tx" SG_ 92 TrnGearCmd_No_Cs 1;
BA_ "U_CD4_MY17_Gas_Tx" SG_ 92 TrnGearCmd_No_Cs 1;
BA_ "U_CD4_MY17_Hev_Tx" SG_ 92 TrnGearCmd_No_Cs 1;
BA_ "U_C489_MY17_Gas_Tx" SG_ 92 TrnGearCmd_No_Cs 1;
BA_ "U_CD42_MY16_Gas_Tx" SG_ 92 TrnGearCmd_No_Cs 1;
BA_ "U_CD43_MY17_Gas_Tx" SG_ 92 TrnGearCmd_No_Cs 1;
BA_ "U_P552_MY17_Gas_Tx" SG_ 92 TrnGearCmd_No_Cs 1;
BA_ "U_P552_MY18_Gas_Tx" SG_ 92 TrnGearCmd_No_Cs 1;
BA_ "U_U55x_MY18_Gas_Tx" SG_ 92 TrnGearCmd_No_Cs 1;
BA_ "ContentDependant" SG_ 92 TrnGearCmd_No_Cnt 1;
BA_ "U_CD43_MY16_Gas_Tx" SG_ 92 TrnGearCmd_No_Cnt 1;
BA_ "U_CD4_MY14_Gas_Tx" SG_ 92 TrnGearCmd_No_Cnt 1;
BA_ "U_CD4_MY14_Hev_Tx" SG_ 92 TrnGearCmd_No_Cnt 1;
BA_ "U_CD4_MY17_Gas_Tx" SG_ 92 TrnGearCmd_No_Cnt 1;
BA_ "U_CD4_MY17_Hev_Tx" SG_ 92 TrnGearCmd_No_Cnt 1;
BA_ "U_C489_MY17_Gas_Tx" SG_ 92 TrnGearCmd_No_Cnt 1;
BA_ "U_CD42_MY16_Gas_Tx" SG_ 92 TrnGearCmd_No_Cnt 1;
BA_ "U_CD43_MY17_Gas_Tx" SG_ 92 TrnGearCmd_No_Cnt 1;
BA_ "U_P552_MY17_Gas_Tx" SG_ 92 TrnGearCmd_No_Cnt 1;
BA_ "U_P552_MY18_Gas_Tx" SG_ 92 TrnGearCmd_No_Cnt 1;
BA_ "U_U55x_MY18_Gas_Tx" SG_ 92 TrnGearCmd_No_Cnt 1;
BA_ "WakeupSignal" SG_ 92 TrnDtpCmd_D_Actl 1;
BA_ "GenSigStartValue" SG_ 92 TrnDtpCmd_D_Actl 1;
BA_ "ContentDependant" SG_ 92 TrnDtpCmd_D_Actl 1;
BA_ "U_CD43_MY16_Gas_Tx" SG_ 92 TrnDtpCmd_D_Actl 1;
BA_ "U_CD4_MY14_Gas_Tx" SG_ 92 TrnDtpCmd_D_Actl 1;
BA_ "U_CD4_MY14_Hev_Tx" SG_ 92 TrnDtpCmd_D_Actl 1;
BA_ "U_CD4_MY17_Gas_Tx" SG_ 92 TrnDtpCmd_D_Actl 1;
BA_ "U_CD4_MY17_Hev_Tx" SG_ 92 TrnDtpCmd_D_Actl 1;
BA_ "U_C489_MY17_Gas_Tx" SG_ 92 TrnDtpCmd_D_Actl 1;
BA_ "U_CD42_MY16_Gas_Tx" SG_ 92 TrnDtpCmd_D_Actl 1;
BA_ "U_CD43_MY17_Gas_Tx" SG_ 92 TrnDtpCmd_D_Actl 1;
BA_ "U_P552_MY17_Gas_Tx" SG_ 92 TrnDtpCmd_D_Actl 1;
BA_ "U_P552_MY18_Gas_Tx" SG_ 92 TrnDtpCmd_D_Actl 1;
BA_ "U_U55x_MY18_Gas_Tx" SG_ 92 TrnDtpCmd_D_Actl 1;
BA_ "GenSigSendType" SG_ 92 TrnCmdState_B_Actl 3;
BA_ "ContentDependant" SG_ 92 TrnCmdState_B_Actl 1;
BA_ "U_CD43_MY16_Gas_Tx" SG_ 92 TrnCmdState_B_Actl 1;
BA_ "U_CD4_MY14_Gas_Tx" SG_ 92 TrnCmdState_B_Actl 1;
BA_ "U_CD4_MY14_Hev_Tx" SG_ 92 TrnCmdState_B_Actl 1;
BA_ "U_CD4_MY17_Gas_Tx" SG_ 92 TrnCmdState_B_Actl 1;
BA_ "U_CD4_MY17_Hev_Tx" SG_ 92 TrnCmdState_B_Actl 1;
BA_ "U_C489_MY17_Gas_Tx" SG_ 92 TrnCmdState_B_Actl 1;
BA_ "U_CD42_MY16_Gas_Tx" SG_ 92 TrnCmdState_B_Actl 1;
BA_ "U_CD43_MY17_Gas_Tx" SG_ 92 TrnCmdState_B_Actl 1;
BA_ "U_P552_MY17_Gas_Tx" SG_ 92 TrnCmdState_B_Actl 1;
BA_ "U_P552_MY18_Gas_Tx" SG_ 92 TrnCmdState_B_Actl 1;
BA_ "U_U55x_MY18_Gas_Tx" SG_ 92 TrnCmdState_B_Actl 1;
BA_ "GenSigSendType" SG_ 92 TrnCmdCnt_B_Actl 3;
BA_ "ContentDependant" SG_ 92 TrnCmdCnt_B_Actl 1;
BA_ "U_CD43_MY16_Gas_Tx" SG_ 92 TrnCmdCnt_B_Actl 1;
BA_ "U_CD4_MY14_Gas_Tx" SG_ 92 TrnCmdCnt_B_Actl 1;
BA_ "U_CD4_MY14_Hev_Tx" SG_ 92 TrnCmdCnt_B_Actl 1;
BA_ "U_CD4_MY17_Gas_Tx" SG_ 92 TrnCmdCnt_B_Actl 1;
BA_ "U_CD4_MY17_Hev_Tx" SG_ 92 TrnCmdCnt_B_Actl 1;
BA_ "U_C489_MY17_Gas_Tx" SG_ 92 TrnCmdCnt_B_Actl 1;
BA_ "U_CD42_MY16_Gas_Tx" SG_ 92 TrnCmdCnt_B_Actl 1;
BA_ "U_CD43_MY17_Gas_Tx" SG_ 92 TrnCmdCnt_B_Actl 1;
BA_ "U_P552_MY17_Gas_Tx" SG_ 92 TrnCmdCnt_B_Actl 1;
BA_ "U_P552_MY18_Gas_Tx" SG_ 92 TrnCmdCnt_B_Actl 1;
BA_ "U_U55x_MY18_Gas_Tx" SG_ 92 TrnCmdCnt_B_Actl 1;
BA_ "GenSigSendType" SG_ 92 PrkBrkActv_D_RqTrnGear 3;
BA_ "GenSigStartValue" SG_ 92 PrkBrkActv_D_RqTrnGear 1;
BA_ "ContentDependant" SG_ 92 PrkBrkActv_D_RqTrnGear 1;
BA_ "U_CD43_MY16_Gas_Tx" SG_ 92 PrkBrkActv_D_RqTrnGear 1;
BA_ "U_CD4_MY14_Gas_Tx" SG_ 92 PrkBrkActv_D_RqTrnGear 1;
BA_ "U_CD4_MY14_Hev_Tx" SG_ 92 PrkBrkActv_D_RqTrnGear 1;
BA_ "U_CD4_MY17_Gas_Tx" SG_ 92 PrkBrkActv_D_RqTrnGear 1;
BA_ "U_CD4_MY17_Hev_Tx" SG_ 92 PrkBrkActv_D_RqTrnGear 1;
BA_ "U_C489_MY17_Gas_Tx" SG_ 92 PrkBrkActv_D_RqTrnGear 1;
BA_ "U_CD42_MY16_Gas_Tx" SG_ 92 PrkBrkActv_D_RqTrnGear 1;
BA_ "U_CD43_MY17_Gas_Tx" SG_ 92 PrkBrkActv_D_RqTrnGear 1;
BA_ "U_P552_MY17_Gas_Tx" SG_ 92 PrkBrkActv_D_RqTrnGear 1;
BA_ "U_P552_MY18_Gas_Tx" SG_ 92 PrkBrkActv_D_RqTrnGear 1;
BA_ "U_U55x_MY18_Gas_Tx" SG_ 92 PrkBrkActv_D_RqTrnGear 1;
BA_ "GenSigSendType" SG_ 92 GearSelLck_D_Rq 3;
BA_ "U_CD43_MY16_Gas_Tx" SG_ 92 GearSelLck_D_Rq 1;
BA_ "U_CD4_MY17_Gas_Tx" SG_ 92 GearSelLck_D_Rq 1;
BA_ "U_CD4_MY17_Hev_Tx" SG_ 92 GearSelLck_D_Rq 1;
BA_ "U_C489_MY17_Gas_Tx" SG_ 92 GearSelLck_D_Rq 1;
BA_ "U_CD43_MY17_Gas_Tx" SG_ 92 GearSelLck_D_Rq 1;
BA_ "U_P552_MY17_Gas_Tx" SG_ 92 GearSelLck_D_Rq 1;
BA_ "U_P552_MY18_Gas_Tx" SG_ 92 GearSelLck_D_Rq 1;
BA_ "U_U55x_MY18_Gas_Tx" SG_ 92 GearSelLck_D_Rq 1;
BA_ "U_B515_MCA_MY17_Diesel_Tx" SG_ 381 WaterInFuel 1;
BA_ "U_CD42_MY16_Diesel_Tx" SG_ 381 WaterInFuel 1;
BA_ "U_V36X_MY16_5_Diesel_Tx" SG_ 381 WaterInFuel 1;
BA_ "U_P558_MY17_Diesel_Tx" SG_ 381 WaterInFuel 1;
BA_ "U_CD4_MY17_Diesel_Tx" SG_ 381 WaterInFuel 1;
BA_ "U_CD4_MY14_Diesel_Tx" SG_ 381 WaterInFuel 1;
BA_ "U_UP375_MY15_Diesel_Tx" SG_ 381 WaterInFuel 1;
BA_ "U_CD42_MY15_Diesel_Tx" SG_ 381 WaterInFuel 1;
BA_ "U_CD4_MY13_Diesel_Tx" SG_ 381 WaterInFuel 1;
BA_ "CrossOver_InfoCAN" SG_ 381 WaterInFuel 1;
BA_ "U_B515_MCA_MY17_Diesel_Tx" SG_ 381 GlowIndication 1;
BA_ "U_CD42_MY16_Diesel_Tx" SG_ 381 GlowIndication 1;
BA_ "U_V36X_MY16_5_Diesel_Tx" SG_ 381 GlowIndication 1;
BA_ "U_P558_MY17_Diesel_Tx" SG_ 381 GlowIndication 1;
BA_ "U_CD4_MY17_Diesel_Tx" SG_ 381 GlowIndication 1;
BA_ "U_CD4_MY14_Diesel_Tx" SG_ 381 GlowIndication 1;
BA_ "U_UP375_MY15_Diesel_Tx" SG_ 381 GlowIndication 1;
BA_ "U_CD42_MY15_Diesel_Tx" SG_ 381 GlowIndication 1;
BA_ "U_CD4_MY13_Diesel_Tx" SG_ 381 GlowIndication 1;
BA_ "CrossOver_InfoCAN" SG_ 381 GlowIndication 1;
BA_ "U_P558_MY17_Diesel_Tx" SG_ 380 WhlRearDual_D_Stat 1;
BA_ "U_P558_MY17_Diesel_Rx" SG_ 380 WhlRearDual_D_Stat 1;
BA_ "U_P558_MY17_Diesel_Tx" SG_ 380 EngExhBrkOnLamp_B_Rq 1;
BA_ "CrossOver_InfoCAN" SG_ 380 EngExhBrkOnLamp_B_Rq 1;
BA_ "U_P558_MY17_Diesel_Tx" SG_ 380 EngExhBrkAutoLamp_B_Rq 1;
BA_ "CrossOver_InfoCAN" SG_ 380 EngExhBrkAutoLamp_B_Rq 1;
BA_ "U_V36X_MY16_5_Diesel_Tx" SG_ 373 DieslPrtc2_D_RqDsply 1;
BA_ "U_P558_MY17_Diesel_Tx" SG_ 373 DieslPrtc2_D_RqDsply 1;
BA_ "U_CD42_MY16_Diesel_Tx" SG_ 373 DieslPrtcRgen_D_Actl 1;
BA_ "U_V36X_MY16_5_Diesel_Tx" SG_ 373 DieslPrtcRgen_D_Actl 1;
BA_ "U_P558_MY17_Diesel_Tx" SG_ 373 DieslPrtcRgen_D_Actl 1;
BA_ "U_CD4_MY17_Diesel_Tx" SG_ 373 DieslPrtcRgen_D_Actl 1;
BA_ "U_CD4_MY14_Diesel_Tx" SG_ 373 DieslPrtcRgen_D_Actl 1;
BA_ "U_UP375_MY15_Diesel_Tx" SG_ 373 DieslPrtcRgen_D_Actl 1;
BA_ "U_V36X_MY16_5_Diesel_Rx" SG_ 373 DieslPrtcRgen_D_Actl 1;
BA_ "U_P558_MY17_Diesel_Rx" SG_ 373 DieslPrtcRgen_D_Actl 1;
BA_ "U_UP375_MY15_Diesel_Rx" SG_ 373 DieslPrtcRgen_D_Actl 1;
BA_ "CrossOver_InfoCAN" SG_ 373 DieslPrtcRgen_D_Actl 1;
BA_ "U_V36X_MY16_5_Diesel_Tx" SG_ 373 EngFuelCutFull_B_Allw 1;
BA_ "U_P558_MY17_Diesel_Tx" SG_ 373 EngFuelCutFull_B_Allw 1;
BA_ "U_CD4_MY17_Phev_Tx" SG_ 373 EngFuelCutFull_B_Allw 1;
BA_ "U_CD4_MY17_Hev_Tx" SG_ 373 EngFuelCutFull_B_Allw 1;
BA_ "U_CD4_MY14_Phev_Tx" SG_ 373 EngFuelCutFull_B_Allw 1;
BA_ "U_CD4_MY14_Hev_Tx" SG_ 373 EngFuelCutFull_B_Allw 1;
BA_ "U_CD4_MY13_Phev_Tx" SG_ 373 EngFuelCutFull_B_Allw 1;
BA_ "U_CD4_MY13_Hev_Tx" SG_ 373 EngFuelCutFull_B_Allw 1;
BA_ "U_CD4_MY17_Phev_Rx" SG_ 373 EngFuelCutFull_B_Allw 1;
BA_ "U_CD4_MY17_Hev_Rx" SG_ 373 EngFuelCutFull_B_Allw 1;
BA_ "U_CD4_MY14_Phev_Rx" SG_ 373 EngFuelCutFull_B_Allw 1;
BA_ "U_CD4_MY14_Hev_Rx" SG_ 373 EngFuelCutFull_B_Allw 1;
BA_ "U_CD4_MY13_Phev_Rx" SG_ 373 EngFuelCutFull_B_Allw 1;
BA_ "U_CD4_MY13_Hev_Rx" SG_ 373 EngFuelCutFull_B_Allw 1;
BA_ "ContentDependant" SG_ 373 EngFuelCutFull_B_Allw 1;
BA_ "CrossOver_InfoCAN" SG_ 373 EngFuelCutFull_B_Allw 1;
BA_ "U_P558_MY17_Diesel_Tx" SG_ 373 EngTeColdPrtct_D_Stats 1;
BA_ "CrossOver_InfoCAN" SG_ 373 EngTeColdPrtct_D_Stats 1;
BA_ "U_B515_MCA_MY17_Diesel_Tx" SG_ 373 EngExhOvrTe_B_RqDsply 1;
BA_ "U_CD42_MY16_Diesel_Tx" SG_ 373 EngExhOvrTe_B_RqDsply 1;
BA_ "U_V36X_MY16_5_Diesel_Tx" SG_ 373 EngExhOvrTe_B_RqDsply 1;
BA_ "U_P558_MY17_Diesel_Tx" SG_ 373 EngExhOvrTe_B_RqDsply 1;
BA_ "U_CD4_MY17_Diesel_Tx" SG_ 373 EngExhOvrTe_B_RqDsply 1;
BA_ "U_CD4_MY14_Diesel_Tx" SG_ 373 EngExhOvrTe_B_RqDsply 1;
BA_ "U_UP375_MY15_Diesel_Tx" SG_ 373 EngExhOvrTe_B_RqDsply 1;
BA_ "CrossOver_InfoCAN" SG_ 373 EngExhOvrTe_B_RqDsply 1;
BA_ "U_V36X_MY16_5_Diesel_Tx" SG_ 373 EngAout_Tq_MxActlN 1;
BA_ "U_P558_MY17_Diesel_Tx" SG_ 373 EngAout_Tq_MxActlN 1;
BA_ "U_CD4_MY17_Phev_Tx" SG_ 373 EngAout_Tq_MxActlN 1;
BA_ "U_CD4_MY17_Hev_Tx" SG_ 373 EngAout_Tq_MxActlN 1;
BA_ "U_CD4_MY14_Phev_Tx" SG_ 373 EngAout_Tq_MxActlN 1;
BA_ "U_CD4_MY14_Hev_Tx" SG_ 373 EngAout_Tq_MxActlN 1;
BA_ "U_UP375_MY15_Diesel_Tx" SG_ 373 EngAout_Tq_MxActlN 1;
BA_ "U_CD4_MY13_Phev_Tx" SG_ 373 EngAout_Tq_MxActlN 1;
BA_ "U_CD4_MY13_Hev_Tx" SG_ 373 EngAout_Tq_MxActlN 1;
BA_ "U_V36X_MY16_5_Diesel_Rx" SG_ 373 EngAout_Tq_MxActlN 1;
BA_ "U_P558_MY17_Diesel_Rx" SG_ 373 EngAout_Tq_MxActlN 1;
BA_ "U_CD4_MY17_Phev_Rx" SG_ 373 EngAout_Tq_MxActlN 1;
BA_ "U_CD4_MY17_Hev_Rx" SG_ 373 EngAout_Tq_MxActlN 1;
BA_ "U_CD4_MY14_Phev_Rx" SG_ 373 EngAout_Tq_MxActlN 1;
BA_ "U_CD4_MY14_Hev_Rx" SG_ 373 EngAout_Tq_MxActlN 1;
BA_ "U_UP375_MY15_Diesel_Rx" SG_ 373 EngAout_Tq_MxActlN 1;
BA_ "U_CD4_MY13_Phev_Rx" SG_ 373 EngAout_Tq_MxActlN 1;
BA_ "U_CD4_MY13_Hev_Rx" SG_ 373 EngAout_Tq_MxActlN 1;
BA_ "ContentDependant" SG_ 373 EngAout_Tq_MxActlN 1;
BA_ "CrossOver_InfoCAN" SG_ 373 EngAout_Tq_MxActlN 1;
BA_ "U_B515_MCA_MY17_Diesel_Tx" SG_ 355 AccFllwMdeActv_B_Actl 1;
BA_ "U_CD42_MY16_Diesel_Tx" SG_ 355 AccFllwMdeActv_B_Actl 1;
BA_ "U_V36X_MY16_5_Diesel_Tx" SG_ 355 AccFllwMdeActv_B_Actl 1;
BA_ "U_P558_MY17_Diesel_Tx" SG_ 355 AccFllwMdeActv_B_Actl 1;
BA_ "U_CD4_MY17_Diesel_Tx" SG_ 355 AccFllwMdeActv_B_Actl 1;
BA_ "U_CD4_MY14_Diesel_Tx" SG_ 355 AccFllwMdeActv_B_Actl 1;
BA_ "U_UP375_MY15_Diesel_Tx" SG_ 355 AccFllwMdeActv_B_Actl 1;
BA_ "U_CD42_MY15_Diesel_Tx" SG_ 355 AccFllwMdeActv_B_Actl 1;
BA_ "U_CD4_MY13_Diesel_Tx" SG_ 355 AccFllwMdeActv_B_Actl 1;
BA_ "U_CD42_MY16_Diesel_Rx" SG_ 355 AccFllwMdeActv_B_Actl 1;
BA_ "U_V36X_MY16_5_Diesel_Rx" SG_ 355 AccFllwMdeActv_B_Actl 1;
BA_ "U_CD4_MY17_Diesel_Rx" SG_ 355 AccFllwMdeActv_B_Actl 1;
BA_ "U_CD4_MY14_Diesel_Rx" SG_ 355 AccFllwMdeActv_B_Actl 1;
BA_ "U_CD42_MY15_Diesel_Rx" SG_ 355 AccFllwMdeActv_B_Actl 1;
BA_ "CrossOver_InfoCAN" SG_ 355 AccFllwMdeActv_B_Actl 1;
BA_ "U_V36X_MY16_5_Diesel_Tx" SG_ 355 ManRgenTxt_D_RqDsply 1;
BA_ "U_P558_MY17_Diesel_Tx" SG_ 355 ManRgenTxt_D_RqDsply 1;
BA_ "U_UP375_MY15_Diesel_Tx" SG_ 355 ManRgenTxt_D_RqDsply 1;
BA_ "CrossOver_InfoCAN" SG_ 355 ManRgenTxt_D_RqDsply 1;
BA_ "U_V36X_MY16_5_Diesel_Tx" SG_ 355 ManRgenSoot_Pc_RqDsply 1;
BA_ "U_P558_MY17_Diesel_Tx" SG_ 355 ManRgenSoot_Pc_RqDsply 1;
BA_ "U_UP375_MY15_Diesel_Tx" SG_ 355 ManRgenSoot_Pc_RqDsply 1;
BA_ "CrossOver_InfoCAN" SG_ 355 ManRgenSoot_Pc_RqDsply 1;
BA_ "U_V36X_MY16_5_Diesel_Tx" SG_ 355 DieslMsgTxt_D_Rq 1;
BA_ "U_P558_MY17_Diesel_Tx" SG_ 355 DieslMsgTxt_D_Rq 1;
BA_ "CrossOver_InfoCAN" SG_ 332 VehUreaWarn_V_DsplyMx 1;
BA_ "U_UP375_MY19_Diesel_Tx" SG_ 332 VehUreaWarn_V_DsplyMx 1;
BA_ "U_P558_MY17_Diesel_Tx" SG_ 332 VehUreaWarn_V_DsplyMx 1;
BA_ "U_V36X_MY16_5_Diesel_Tx" SG_ 332 VehUreaWarn_V_DsplyMx 1;
BA_ "U_V408_MY18_Diesel_Tx" SG_ 332 VehUreaWarn_V_DsplyMx 1;
BA_ "U_V36X_MY19_Tx" SG_ 332 VehUreaWarn_V_DsplyMx 1;
BA_ "U_P552_MY18_5_Diesel_Tx" SG_ 332 VehUreaWarn_V_DsplyMx 1;
BA_ "U_V363E_N_MY19_5_20_Gas_Tx" SG_ 332 VehUreaWarn_V_DsplyMx 1;
BA_ "U_V363E_N_MY19_5_20_Diesel_Tx" SG_ 332 VehUreaWarn_V_DsplyMx 1;
BA_ "U_CD42_MY19_Diesel_Tx" SG_ 332 VehUreaWarn_V_DsplyMx 1;
BA_ "CrossOver_InfoCAN" SG_ 332 VehUreaRnge2_L_DsplyMx 1;
BA_ "U_P558_MY17_Diesel_Tx" SG_ 332 UreaLvl_Pc_Actl 1;
BA_ "U_P558_MY17_Diesel_Tx" SG_ 332 ExhOverheat_T_Actl 1;
BA_ "U_V36X_MY16_5_Diesel_Tx" SG_ 332 UreaQltySys_D_RqDsply 1;
BA_ "U_P558_MY17_Diesel_Tx" SG_ 332 UreaQltySys_D_RqDsply 1;
BA_ "U_UP375_MY15_Diesel_Tx" SG_ 332 UreaQltySys_D_RqDsply 1;
BA_ "CrossOver_InfoCAN" SG_ 332 UreaQltySys_D_RqDsply 1;
BA_ "U_V36X_MY16_5_Diesel_Tx" SG_ 332 UreaLvlTxt_D_RqDsply 1;
BA_ "U_P558_MY17_Diesel_Tx" SG_ 332 UreaLvlTxt_D_RqDsply 1;
BA_ "U_UP375_MY15_Diesel_Tx" SG_ 332 UreaLvlTxt_D_RqDsply 1;
BA_ "CrossOver_InfoCAN" SG_ 332 UreaLvlTxt_D_RqDsply 1;
BA_ "U_V36X_MY16_5_Diesel_Tx" SG_ 332 VehUreaImmo_No_DsplyMx 1;
BA_ "U_P558_MY17_Diesel_Tx" SG_ 332 VehUreaImmo_No_DsplyMx 1;
BA_ "U_UP375_MY15_Diesel_Tx" SG_ 332 VehUreaImmo_No_DsplyMx 1;
BA_ "CrossOver_InfoCAN" SG_ 332 VehUreaImmo_No_DsplyMx 1;
BA_ "GenSigSendType" SG_ 1827 TesterPhysicalReqBECMB_EPM 3;
BA_ "U_CD4_MY17_Diesel_Rx" SG_ 1827 TesterPhysicalReqBECMB_EPM 1;
BA_ "U_CD4_MY17_Gas_Rx" SG_ 1827 TesterPhysicalReqBECMB_EPM 1;
BA_ "U_CD4_MY17_Hev_Rx" SG_ 1827 TesterPhysicalReqBECMB_EPM 1;
BA_ "U_CD4_MY17_Phev_Rx" SG_ 1827 TesterPhysicalReqBECMB_EPM 1;
BA_ "U_P558_MY17_Gas_Rx" SG_ 1827 TesterPhysicalReqBECMB_EPM 1;
BA_ "U_P558_MY17_Diesel_Rx" SG_ 1827 TesterPhysicalReqBECMB_EPM 1;
BA_ "U_C489_MY17_Gas_Rx" SG_ 1827 TesterPhysicalReqBECMB_EPM 1;
BA_ "U_CD43_MY17_Gas_Rx" SG_ 1827 TesterPhysicalReqBECMB_EPM 1;
BA_ "U_U55x_MY18_Gas_Rx" SG_ 1827 TesterPhysicalReqBECMB_EPM 1;
BA_ "GenSigSendType" SG_ 1458 BECMB_AutoSar_Network_Mgmt 3;
BA_ "U_CD4_MY17_Diesel_Tx" SG_ 1458 BECMB_AutoSar_Network_Mgmt 1;
BA_ "U_CD4_MY17_Gas_Tx" SG_ 1458 BECMB_AutoSar_Network_Mgmt 1;
BA_ "U_CD4_MY17_Hev_Tx" SG_ 1458 BECMB_AutoSar_Network_Mgmt 1;
BA_ "U_CD4_MY17_Phev_Tx" SG_ 1458 BECMB_AutoSar_Network_Mgmt 1;
BA_ "U_P558_MY17_Gas_Tx" SG_ 1458 BECMB_AutoSar_Network_Mgmt 1;
BA_ "U_P558_MY17_Diesel_Tx" SG_ 1458 BECMB_AutoSar_Network_Mgmt 1;
BA_ "U_C489_MY17_Gas_Tx" SG_ 1458 BECMB_AutoSar_Network_Mgmt 1;
BA_ "U_CD43_MY17_Gas_Tx" SG_ 1458 BECMB_AutoSar_Network_Mgmt 1;
BA_ "U_U55x_MY18_Gas_Tx" SG_ 1458 BECMB_AutoSar_Network_Mgmt 1;
BA_ "GenSigStartValue" SG_ 1110 RstrnMdulePw_D_Falt 1;
BA_ "U_CD4_MY17_Diesel_Tx" SG_ 1110 RstrnMdulePw_D_Falt 1;
BA_ "U_CD4_MY17_Gas_Tx" SG_ 1110 RstrnMdulePw_D_Falt 1;
BA_ "U_CD4_MY17_Hev_Tx" SG_ 1110 RstrnMdulePw_D_Falt 1;
BA_ "U_CD4_MY17_Phev_Tx" SG_ 1110 RstrnMdulePw_D_Falt 1;
BA_ "U_P558_MY17_Gas_Tx" SG_ 1110 RstrnMdulePw_D_Falt 1;
BA_ "U_P558_MY17_Diesel_Tx" SG_ 1110 RstrnMdulePw_D_Falt 1;
BA_ "U_C489_MY17_Gas_Tx" SG_ 1110 RstrnMdulePw_D_Falt 1;
BA_ "U_CD43_MY17_Gas_Tx" SG_ 1110 RstrnMdulePw_D_Falt 1;
BA_ "U_U55x_MY18_Gas_Tx" SG_ 1110 RstrnMdulePw_D_Falt 1;
BA_ "GenSigSendType" SG_ 1835 TesterPhysicalResBECMB_EPM 3;
BA_ "U_CD4_MY17_Diesel_Tx" SG_ 1835 TesterPhysicalResBECMB_EPM 1;
BA_ "U_CD4_MY17_Gas_Tx" SG_ 1835 TesterPhysicalResBECMB_EPM 1;
BA_ "U_CD4_MY17_Hev_Tx" SG_ 1835 TesterPhysicalResBECMB_EPM 1;
BA_ "U_CD4_MY17_Phev_Tx" SG_ 1835 TesterPhysicalResBECMB_EPM 1;
BA_ "U_P558_MY17_Gas_Tx" SG_ 1835 TesterPhysicalResBECMB_EPM 1;
BA_ "U_P558_MY17_Diesel_Tx" SG_ 1835 TesterPhysicalResBECMB_EPM 1;
BA_ "U_C489_MY17_Gas_Tx" SG_ 1835 TesterPhysicalResBECMB_EPM 1;
BA_ "U_CD43_MY17_Gas_Tx" SG_ 1835 TesterPhysicalResBECMB_EPM 1;
BA_ "U_U55x_MY18_Gas_Tx" SG_ 1835 TesterPhysicalResBECMB_EPM 1;
BA_ "GenSigTimeoutTime_GWM" SG_ 1071 EngAoutIdl_N_Ntrl 90;
BA_ "U_U55x_MY18_Gas_Tx" SG_ 1071 EngAoutIdl_N_Ntrl 1;
BA_ "U_B515_MCA_MY17_Gas_Tx" SG_ 1071 EngAoutIdl_N_Ntrl 1;
BA_ "U_B515_MCA_MY17_Diesel_Tx" SG_ 1071 EngAoutIdl_N_Ntrl 1;
BA_ "U_CD43_MY17_Gas_Tx" SG_ 1071 EngAoutIdl_N_Ntrl 1;
BA_ "U_CD42_MY16_Diesel_Tx" SG_ 1071 EngAoutIdl_N_Ntrl 1;
BA_ "U_C489_MY17_Gas_Tx" SG_ 1071 EngAoutIdl_N_Ntrl 1;
BA_ "U_V36X_MY16_5_Diesel_Tx" SG_ 1071 EngAoutIdl_N_Ntrl 1;
BA_ "U_P558_MY17_Diesel_Tx" SG_ 1071 EngAoutIdl_N_Ntrl 1;
BA_ "U_P558_MY17_Gas_Tx" SG_ 1071 EngAoutIdl_N_Ntrl 1;
BA_ "U_CD4_MY17_Gas_Tx" SG_ 1071 EngAoutIdl_N_Ntrl 1;
BA_ "U_CD4_MY17_Diesel_Tx" SG_ 1071 EngAoutIdl_N_Ntrl 1;
BA_ "U_CD4_MY14_Gas_Tx" SG_ 1071 EngAoutIdl_N_Ntrl 1;
BA_ "U_CD4_MY14_Diesel_Tx" SG_ 1071 EngAoutIdl_N_Ntrl 1;
BA_ "U_CD43_MY16_Gas_Tx" SG_ 1071 EngAoutIdl_N_Ntrl 1;
BA_ "U_UP375_MY15_Diesel_Tx" SG_ 1071 EngAoutIdl_N_Ntrl 1;
BA_ "U_U502_MY16_Gas_Tx" SG_ 1071 EngAoutIdl_N_Ntrl 1;
BA_ "ContentDependant" SG_ 1071 EngAoutIdl_N_Ntrl 1;
BA_ "CrossOver_InfoCAN" SG_ 1071 EngAoutIdl_N_Ntrl 1;
BA_ "GenSigTimeoutTime_GWM" SG_ 1071 CluPdl_PcRate_Actl 90;
BA_ "U_B515_MCA_MY17_Gas_Tx" SG_ 1071 CluPdl_PcRate_Actl 1;
BA_ "U_B515_MCA_MY17_Diesel_Tx" SG_ 1071 CluPdl_PcRate_Actl 1;
BA_ "U_CD42_MY16_Diesel_Tx" SG_ 1071 CluPdl_PcRate_Actl 1;
BA_ "U_V36X_MY16_5_Diesel_Tx" SG_ 1071 CluPdl_PcRate_Actl 1;
BA_ "U_P558_MY17_Diesel_Tx" SG_ 1071 CluPdl_PcRate_Actl 1;
BA_ "U_P558_MY17_Gas_Tx" SG_ 1071 CluPdl_PcRate_Actl 1;
BA_ "U_CD4_MY17_Gas_Tx" SG_ 1071 CluPdl_PcRate_Actl 1;
BA_ "U_CD4_MY17_Diesel_Tx" SG_ 1071 CluPdl_PcRate_Actl 1;
BA_ "U_CD4_MY14_Gas_Tx" SG_ 1071 CluPdl_PcRate_Actl 1;
BA_ "U_CD4_MY14_Diesel_Tx" SG_ 1071 CluPdl_PcRate_Actl 1;
BA_ "U_UP375_MY15_Diesel_Tx" SG_ 1071 CluPdl_PcRate_Actl 1;
BA_ "ContentDependant" SG_ 1071 CluPdl_PcRate_Actl 1;
BA_ "CrossOver_InfoCAN" SG_ 1071 CluPdl_PcRate_Actl 1;
BA_ "GenSigTimeoutTime_GWM" SG_ 1071 CluPdlPos_Pc_Meas 90;
BA_ "U_B515_MCA_MY17_Gas_Tx" SG_ 1071 CluPdlPos_Pc_Meas 1;
BA_ "U_B515_MCA_MY17_Diesel_Tx" SG_ 1071 CluPdlPos_Pc_Meas 1;
BA_ "U_CD42_MY16_Diesel_Tx" SG_ 1071 CluPdlPos_Pc_Meas 1;
BA_ "U_V36X_MY16_5_Diesel_Tx" SG_ 1071 CluPdlPos_Pc_Meas 1;
BA_ "U_P558_MY17_Diesel_Tx" SG_ 1071 CluPdlPos_Pc_Meas 1;
BA_ "U_P558_MY17_Gas_Tx" SG_ 1071 CluPdlPos_Pc_Meas 1;
BA_ "U_CD4_MY17_Gas_Tx" SG_ 1071 CluPdlPos_Pc_Meas 1;
BA_ "U_CD4_MY17_Diesel_Tx" SG_ 1071 CluPdlPos_Pc_Meas 1;
BA_ "U_CD4_MY14_Gas_Tx" SG_ 1071 CluPdlPos_Pc_Meas 1;
BA_ "U_CD4_MY14_Diesel_Tx" SG_ 1071 CluPdlPos_Pc_Meas 1;
BA_ "U_UP375_MY15_Diesel_Tx" SG_ 1071 CluPdlPos_Pc_Meas 1;
BA_ "ContentDependant" SG_ 1071 CluPdlPos_Pc_Meas 1;
BA_ "CrossOver_InfoCAN" SG_ 1071 CluPdlPos_Pc_Meas 1;
BA_ "GenSigTimeoutTime_GWM" SG_ 1071 CluPdlPosPcMeas_D_Qf 90;
BA_ "U_B515_MCA_MY17_Gas_Tx" SG_ 1071 CluPdlPosPcMeas_D_Qf 1;
BA_ "U_B515_MCA_MY17_Diesel_Tx" SG_ 1071 CluPdlPosPcMeas_D_Qf 1;
BA_ "U_CD42_MY16_Gas_Tx" SG_ 1071 CluPdlPosPcMeas_D_Qf 1;
BA_ "U_CD42_MY16_Diesel_Tx" SG_ 1071 CluPdlPosPcMeas_D_Qf 1;
BA_ "U_V36X_MY16_5_Diesel_Tx" SG_ 1071 CluPdlPosPcMeas_D_Qf 1;
BA_ "U_P558_MY17_Diesel_Tx" SG_ 1071 CluPdlPosPcMeas_D_Qf 1;
BA_ "U_P558_MY17_Gas_Tx" SG_ 1071 CluPdlPosPcMeas_D_Qf 1;
BA_ "U_CD4_MY17_Gas_Tx" SG_ 1071 CluPdlPosPcMeas_D_Qf 1;
BA_ "U_CD4_MY17_Diesel_Tx" SG_ 1071 CluPdlPosPcMeas_D_Qf 1;
BA_ "U_CD4_MY14_Gas_Tx" SG_ 1071 CluPdlPosPcMeas_D_Qf 1;
BA_ "U_CD4_MY14_Diesel_Tx" SG_ 1071 CluPdlPosPcMeas_D_Qf 1;
BA_ "U_UP375_MY15_Diesel_Tx" SG_ 1071 CluPdlPosPcMeas_D_Qf 1;
BA_ "ContentDependant" SG_ 1071 CluPdlPosPcMeas_D_Qf 1;
BA_ "GenSigStartValue" SG_ 1071 CluPdlPosPcMeas_D_Qf 1;
BA_ "CrossOver_InfoCAN" SG_ 1071 CluPdlPosPcMeas_D_Qf 1;
BA_ "U_C489_MY14_Gas_Tx" SG_ 2017 TesterPhysicalReqTCM 1;
BA_ "U_S550_MY15_Gas_Tx" SG_ 2017 TesterPhysicalReqTCM 1;
BA_ "U_P552_MY15_Gas_Tx" SG_ 2017 TesterPhysicalReqTCM 1;
BA_ "U_CD42_MY15_Gas_Tx" SG_ 2017 TesterPhysicalReqTCM 1;
BA_ "U_CD42_MY15_Diesel_Tx" SG_ 2017 TesterPhysicalReqTCM 1;
BA_ "U_CD4_MY13_Phev_Tx" SG_ 2017 TesterPhysicalReqTCM 1;
BA_ "U_CD4_MY13_Hev_Tx" SG_ 2017 TesterPhysicalReqTCM 1;
BA_ "U_CD4_MY13_Gas_Tx" SG_ 2017 TesterPhysicalReqTCM 1;
BA_ "U_CD4_MY13_Diesel_Tx" SG_ 2017 TesterPhysicalReqTCM 1;
BA_ "U_CD42_MY16_Diesel_Rx" SG_ 2017 TesterPhysicalReqTCM 1;
BA_ "U_V36X_MY16_5_Diesel_Rx" SG_ 2017 TesterPhysicalReqTCM 1;
BA_ "U_P558_MY17_Diesel_Rx" SG_ 2017 TesterPhysicalReqTCM 1;
BA_ "U_CD4_MY17_Diesel_Rx" SG_ 2017 TesterPhysicalReqTCM 1;
BA_ "U_CD4_MY14_Diesel_Rx" SG_ 2017 TesterPhysicalReqTCM 1;
BA_ "U_UP375_MY15_Diesel_Rx" SG_ 2017 TesterPhysicalReqTCM 1;
BA_ "U_CD42_MY15_Diesel_Rx" SG_ 2017 TesterPhysicalReqTCM 1;
BA_ "U_CD4_MY13_Diesel_Rx" SG_ 2017 TesterPhysicalReqTCM 1;
BA_ "GenSigSendType" SG_ 2017 TesterPhysicalReqTCM 3;
BA_ "U_CD42_MY16_Diesel_Tx" SG_ 2025 TesterPhysicalResTCM 1;
BA_ "U_V36X_MY16_5_Diesel_Tx" SG_ 2025 TesterPhysicalResTCM 1;
BA_ "U_P558_MY17_Diesel_Tx" SG_ 2025 TesterPhysicalResTCM 1;
BA_ "U_CD4_MY17_Diesel_Tx" SG_ 2025 TesterPhysicalResTCM 1;
BA_ "U_CD4_MY14_Diesel_Tx" SG_ 2025 TesterPhysicalResTCM 1;
BA_ "U_UP375_MY15_Diesel_Tx" SG_ 2025 TesterPhysicalResTCM 1;
BA_ "U_CD42_MY15_Diesel_Tx" SG_ 2025 TesterPhysicalResTCM 1;
BA_ "U_CD4_MY13_Diesel_Tx" SG_ 2025 TesterPhysicalResTCM 1;
BA_ "U_C489_MY14_Gas_Rx" SG_ 2025 TesterPhysicalResTCM 1;
BA_ "U_S550_MY15_Gas_Rx" SG_ 2025 TesterPhysicalResTCM 1;
BA_ "U_P552_MY15_Gas_Rx" SG_ 2025 TesterPhysicalResTCM 1;
BA_ "U_CD42_MY15_Gas_Rx" SG_ 2025 TesterPhysicalResTCM 1;
BA_ "U_CD42_MY15_Diesel_Rx" SG_ 2025 TesterPhysicalResTCM 1;
BA_ "U_CD4_MY13_Phev_Rx" SG_ 2025 TesterPhysicalResTCM 1;
BA_ "U_CD4_MY13_Hev_Rx" SG_ 2025 TesterPhysicalResTCM 1;
BA_ "U_CD4_MY13_Gas_Rx" SG_ 2025 TesterPhysicalResTCM 1;
BA_ "U_CD4_MY13_Diesel_Rx" SG_ 2025 TesterPhysicalResTCM 1;
BA_ "GenSigSendType" SG_ 2025 TesterPhysicalResTCM 3;
BA_ "U_CD42_MY16_Diesel_Tx" SG_ 1701 UUDTTCMResponse2 1;
BA_ "U_V36X_MY16_5_Diesel_Tx" SG_ 1701 UUDTTCMResponse2 1;
BA_ "U_P558_MY17_Diesel_Tx" SG_ 1701 UUDTTCMResponse2 1;
BA_ "U_CD4_MY17_Diesel_Tx" SG_ 1701 UUDTTCMResponse2 1;
BA_ "U_CD4_MY14_Diesel_Tx" SG_ 1701 UUDTTCMResponse2 1;
BA_ "U_UP375_MY15_Diesel_Tx" SG_ 1701 UUDTTCMResponse2 1;
BA_ "U_CD42_MY15_Diesel_Tx" SG_ 1701 UUDTTCMResponse2 1;
BA_ "U_CD4_MY13_Diesel_Tx" SG_ 1701 UUDTTCMResponse2 1;
BA_ "U_C489_MY14_Gas_Rx" SG_ 1701 UUDTTCMResponse2 1;
BA_ "U_S550_MY15_Gas_Rx" SG_ 1701 UUDTTCMResponse2 1;
BA_ "U_P552_MY15_Gas_Rx" SG_ 1701 UUDTTCMResponse2 1;
BA_ "U_CD42_MY15_Gas_Rx" SG_ 1701 UUDTTCMResponse2 1;
BA_ "U_CD42_MY15_Diesel_Rx" SG_ 1701 UUDTTCMResponse2 1;
BA_ "U_CD4_MY13_Phev_Rx" SG_ 1701 UUDTTCMResponse2 1;
BA_ "U_CD4_MY13_Hev_Rx" SG_ 1701 UUDTTCMResponse2 1;
BA_ "U_CD4_MY13_Gas_Rx" SG_ 1701 UUDTTCMResponse2 1;
BA_ "U_CD4_MY13_Diesel_Rx" SG_ 1701 UUDTTCMResponse2 1;
BA_ "GenSigSendType" SG_ 1701 UUDTTCMResponse2 3;
BA_ "U_CD42_MY16_Diesel_Tx" SG_ 1700 UUDTTCMResponse1 1;
BA_ "U_V36X_MY16_5_Diesel_Tx" SG_ 1700 UUDTTCMResponse1 1;
BA_ "U_P558_MY17_Diesel_Tx" SG_ 1700 UUDTTCMResponse1 1;
BA_ "U_CD4_MY17_Diesel_Tx" SG_ 1700 UUDTTCMResponse1 1;
BA_ "U_CD4_MY14_Diesel_Tx" SG_ 1700 UUDTTCMResponse1 1;
BA_ "U_UP375_MY15_Diesel_Tx" SG_ 1700 UUDTTCMResponse1 1;
BA_ "U_CD42_MY15_Diesel_Tx" SG_ 1700 UUDTTCMResponse1 1;
BA_ "U_CD4_MY13_Diesel_Tx" SG_ 1700 UUDTTCMResponse1 1;
BA_ "U_C489_MY14_Gas_Rx" SG_ 1700 UUDTTCMResponse1 1;
BA_ "U_S550_MY15_Gas_Rx" SG_ 1700 UUDTTCMResponse1 1;
BA_ "U_P552_MY15_Gas_Rx" SG_ 1700 UUDTTCMResponse1 1;
BA_ "U_CD42_MY15_Gas_Rx" SG_ 1700 UUDTTCMResponse1 1;
BA_ "U_CD42_MY15_Diesel_Rx" SG_ 1700 UUDTTCMResponse1 1;
BA_ "U_CD4_MY13_Phev_Rx" SG_ 1700 UUDTTCMResponse1 1;
BA_ "U_CD4_MY13_Hev_Rx" SG_ 1700 UUDTTCMResponse1 1;
BA_ "U_CD4_MY13_Gas_Rx" SG_ 1700 UUDTTCMResponse1 1;
BA_ "U_CD4_MY13_Diesel_Rx" SG_ 1700 UUDTTCMResponse1 1;
BA_ "GenSigSendType" SG_ 1700 UUDTTCMResponse1 3;
BA_ "U_CD42_MY16_Diesel_Tx" SG_ 561 TrnMsgTxt2_D_Rq 1;
BA_ "U_CD4_MY17_Diesel_Tx" SG_ 561 TrnMsgTxt2_D_Rq 1;
BA_ "U_CD4_MY14_Diesel_Tx" SG_ 561 TrnMsgTxt2_D_Rq 1;
BA_ "U_CD42_MY15_Diesel_Tx" SG_ 561 TrnMsgTxt2_D_Rq 1;
BA_ "U_CD4_MY13_Diesel_Tx" SG_ 561 TrnMsgTxt2_D_Rq 1;
BA_ "CrossOver_InfoCAN" SG_ 561 TrnMsgTxt2_D_Rq 1;
BA_ "U_CD42_MY16_Diesel_Tx" SG_ 561 TrnMsgTxt_D_Rq 1;
BA_ "U_CD4_MY17_Diesel_Tx" SG_ 561 TrnMsgTxt_D_Rq 1;
BA_ "U_CD4_MY14_Diesel_Tx" SG_ 561 TrnMsgTxt_D_Rq 1;
BA_ "U_CD42_MY15_Diesel_Tx" SG_ 561 TrnMsgTxt_D_Rq 1;
BA_ "U_CD4_MY13_Diesel_Tx" SG_ 561 TrnMsgTxt_D_Rq 1;
BA_ "CrossOver_InfoCAN" SG_ 561 TrnMsgTxt_D_Rq 1;
BA_ "U_CD42_MY16_Diesel_Tx" SG_ 370 GearPos_D_Actl 1;
BA_ "U_V36X_MY16_5_Diesel_Tx" SG_ 370 GearPos_D_Actl 1;
BA_ "U_P558_MY17_Diesel_Tx" SG_ 370 GearPos_D_Actl 1;
BA_ "U_CD4_MY17_Diesel_Tx" SG_ 370 GearPos_D_Actl 1;
BA_ "U_CD4_MY14_Diesel_Tx" SG_ 370 GearPos_D_Actl 1;
BA_ "U_UP375_MY15_Diesel_Tx" SG_ 370 GearPos_D_Actl 1;
BA_ "U_CD42_MY15_Diesel_Tx" SG_ 370 GearPos_D_Actl 1;
BA_ "U_CD4_MY13_Diesel_Tx" SG_ 370 GearPos_D_Actl 1;
BA_ "U_CD42_MY16_Diesel_Rx" SG_ 370 GearPos_D_Actl 1;
BA_ "U_V36X_MY16_5_Diesel_Rx" SG_ 370 GearPos_D_Actl 1;
BA_ "U_P558_MY17_Diesel_Rx" SG_ 370 GearPos_D_Actl 1;
BA_ "U_CD4_MY14_Diesel_Rx" SG_ 370 GearPos_D_Actl 1;
BA_ "U_UP375_MY15_Diesel_Rx" SG_ 370 GearPos_D_Actl 1;
BA_ "U_CD42_MY15_Diesel_Rx" SG_ 370 GearPos_D_Actl 1;
BA_ "GenSigStartValue" SG_ 370 GearPos_D_Actl 15;
BA_ "GenSigStartValue" SG_ 1440 TCM_GWOnBoardTester 255;
BA_ "ContentDependant" SG_ 1440 TCM_GWOnBoardTester 1;
BA_ "U_CD4_MY17_Diesel_Rx" SG_ 1440 TCM_GWOnBoardTester 1;
BA_ "U_CD4_MY17_Gas_Rx" SG_ 1440 TCM_GWOnBoardTester 1;
BA_ "U_CD4_MY17_Hev_Rx" SG_ 1440 TCM_GWOnBoardTester 1;
BA_ "U_CD4_MY17_Phev_Rx" SG_ 1440 TCM_GWOnBoardTester 1;
BA_ "U_P558_MY17_Gas_Rx" SG_ 1440 TCM_GWOnBoardTester 1;
BA_ "U_P558_MY17_Diesel_Rx" SG_ 1440 TCM_GWOnBoardTester 1;
BA_ "U_V36X_MY16_5_Diesel_Rx" SG_ 1440 TCM_GWOnBoardTester 1;
BA_ "U_C489_MY17_Gas_Rx" SG_ 1440 TCM_GWOnBoardTester 1;
BA_ "U_CD43_MY17_Gas_Rx" SG_ 1440 TCM_GWOnBoardTester 1;
BA_ "U_P552_MY17_Gas_Rx" SG_ 1440 TCM_GWOnBoardTester 1;
BA_ "U_B515_MCA_MY17_Diesel_Rx" SG_ 1440 TCM_GWOnBoardTester 1;
BA_ "U_B515_MCA_MY17_Gas_Rx" SG_ 1440 TCM_GWOnBoardTester 1;
BA_ "U_U55x_MY18_Gas_Rx" SG_ 1440 TCM_GWOnBoardTester 1;
BA_ "U_P558_MY17_Diesel_Tx" SG_ 1440 TCM_GWOnBoardTester 1;
BA_ "U_V36X_MY16_5_Diesel_Tx" SG_ 1440 TCM_GWOnBoardTester 1;
BA_ "U_P552_MY17_Gas_Tx" SG_ 1440 TCM_GWOnBoardTester 1;
BA_ "U_U55x_MY18_Gas_Tx" SG_ 1440 TCM_GWOnBoardTester 1;
BA_ "GenSigStartValue" SG_ 1440 TCM_GWNMProxy 255;
BA_ "ContentDependant" SG_ 1440 TCM_GWNMProxy 1;
BA_ "U_CD4_MY17_Diesel_Rx" SG_ 1440 TCM_GWNMProxy 1;
BA_ "U_CD4_MY17_Gas_Rx" SG_ 1440 TCM_GWNMProxy 1;
BA_ "U_CD4_MY17_Hev_Rx" SG_ 1440 TCM_GWNMProxy 1;
BA_ "U_CD4_MY17_Phev_Rx" SG_ 1440 TCM_GWNMProxy 1;
BA_ "U_P558_MY17_Gas_Rx" SG_ 1440 TCM_GWNMProxy 1;
BA_ "U_P558_MY17_Diesel_Rx" SG_ 1440 TCM_GWNMProxy 1;
BA_ "U_V36X_MY16_5_Diesel_Rx" SG_ 1440 TCM_GWNMProxy 1;
BA_ "U_C489_MY17_Gas_Rx" SG_ 1440 TCM_GWNMProxy 1;
BA_ "U_CD43_MY17_Gas_Rx" SG_ 1440 TCM_GWNMProxy 1;
BA_ "U_P552_MY17_Gas_Rx" SG_ 1440 TCM_GWNMProxy 1;
BA_ "U_B515_MCA_MY17_Diesel_Rx" SG_ 1440 TCM_GWNMProxy 1;
BA_ "U_B515_MCA_MY17_Gas_Rx" SG_ 1440 TCM_GWNMProxy 1;
BA_ "U_U55x_MY18_Gas_Rx" SG_ 1440 TCM_GWNMProxy 1;
BA_ "U_P558_MY17_Diesel_Tx" SG_ 1440 TCM_GWNMProxy 1;
BA_ "U_V36X_MY16_5_Diesel_Tx" SG_ 1440 TCM_GWNMProxy 1;
BA_ "U_P552_MY17_Gas_Tx" SG_ 1440 TCM_GWNMProxy 1;
BA_ "U_U55x_MY18_Gas_Tx" SG_ 1440 TCM_GWNMProxy 1;
BA_ "GenSigStartValue" SG_ 1440 TCM_AutoSarNMReserved4 255;
BA_ "ContentDependant" SG_ 1440 TCM_AutoSarNMReserved4 1;
BA_ "U_CD4_MY17_Diesel_Rx" SG_ 1440 TCM_AutoSarNMReserved4 1;
BA_ "U_CD4_MY17_Gas_Rx" SG_ 1440 TCM_AutoSarNMReserved4 1;
BA_ "U_CD4_MY17_Hev_Rx" SG_ 1440 TCM_AutoSarNMReserved4 1;
BA_ "U_CD4_MY17_Phev_Rx" SG_ 1440 TCM_AutoSarNMReserved4 1;
BA_ "U_P558_MY17_Gas_Rx" SG_ 1440 TCM_AutoSarNMReserved4 1;
BA_ "U_P558_MY17_Diesel_Rx" SG_ 1440 TCM_AutoSarNMReserved4 1;
BA_ "U_V36X_MY16_5_Diesel_Rx" SG_ 1440 TCM_AutoSarNMReserved4 1;
BA_ "U_C489_MY17_Gas_Rx" SG_ 1440 TCM_AutoSarNMReserved4 1;
BA_ "U_CD43_MY17_Gas_Rx" SG_ 1440 TCM_AutoSarNMReserved4 1;
BA_ "U_P552_MY17_Gas_Rx" SG_ 1440 TCM_AutoSarNMReserved4 1;
BA_ "U_B515_MCA_MY17_Diesel_Rx" SG_ 1440 TCM_AutoSarNMReserved4 1;
BA_ "U_B515_MCA_MY17_Gas_Rx" SG_ 1440 TCM_AutoSarNMReserved4 1;
BA_ "U_U55x_MY18_Gas_Rx" SG_ 1440 TCM_AutoSarNMReserved4 1;
BA_ "U_P558_MY17_Diesel_Tx" SG_ 1440 TCM_AutoSarNMReserved4 1;
BA_ "U_V36X_MY16_5_Diesel_Tx" SG_ 1440 TCM_AutoSarNMReserved4 1;
BA_ "U_P552_MY17_Gas_Tx" SG_ 1440 TCM_AutoSarNMReserved4 1;
BA_ "U_U55x_MY18_Gas_Tx" SG_ 1440 TCM_AutoSarNMReserved4 1;
BA_ "GenSigStartValue" SG_ 1440 TCM_AutoSarNMReserved3 255;
BA_ "ContentDependant" SG_ 1440 TCM_AutoSarNMReserved3 1;
BA_ "U_CD4_MY17_Diesel_Rx" SG_ 1440 TCM_AutoSarNMReserved3 1;
BA_ "U_CD4_MY17_Gas_Rx" SG_ 1440 TCM_AutoSarNMReserved3 1;
BA_ "U_CD4_MY17_Hev_Rx" SG_ 1440 TCM_AutoSarNMReserved3 1;
BA_ "U_CD4_MY17_Phev_Rx" SG_ 1440 TCM_AutoSarNMReserved3 1;
BA_ "U_P558_MY17_Gas_Rx" SG_ 1440 TCM_AutoSarNMReserved3 1;
BA_ "U_P558_MY17_Diesel_Rx" SG_ 1440 TCM_AutoSarNMReserved3 1;
BA_ "U_V36X_MY16_5_Diesel_Rx" SG_ 1440 TCM_AutoSarNMReserved3 1;
BA_ "U_C489_MY17_Gas_Rx" SG_ 1440 TCM_AutoSarNMReserved3 1;
BA_ "U_CD43_MY17_Gas_Rx" SG_ 1440 TCM_AutoSarNMReserved3 1;
BA_ "U_P552_MY17_Gas_Rx" SG_ 1440 TCM_AutoSarNMReserved3 1;
BA_ "U_B515_MCA_MY17_Diesel_Rx" SG_ 1440 TCM_AutoSarNMReserved3 1;
BA_ "U_B515_MCA_MY17_Gas_Rx" SG_ 1440 TCM_AutoSarNMReserved3 1;
BA_ "U_U55x_MY18_Gas_Rx" SG_ 1440 TCM_AutoSarNMReserved3 1;
BA_ "U_P558_MY17_Diesel_Tx" SG_ 1440 TCM_AutoSarNMReserved3 1;
BA_ "U_V36X_MY16_5_Diesel_Tx" SG_ 1440 TCM_AutoSarNMReserved3 1;
BA_ "U_P552_MY17_Gas_Tx" SG_ 1440 TCM_AutoSarNMReserved3 1;
BA_ "U_U55x_MY18_Gas_Tx" SG_ 1440 TCM_AutoSarNMReserved3 1;
BA_ "GenSigStartValue" SG_ 1440 TCM_AutoSarNMReserved2 255;
BA_ "ContentDependant" SG_ 1440 TCM_AutoSarNMReserved2 1;
BA_ "U_CD4_MY17_Diesel_Rx" SG_ 1440 TCM_AutoSarNMReserved2 1;
BA_ "U_CD4_MY17_Gas_Rx" SG_ 1440 TCM_AutoSarNMReserved2 1;
BA_ "U_CD4_MY17_Hev_Rx" SG_ 1440 TCM_AutoSarNMReserved2 1;
BA_ "U_CD4_MY17_Phev_Rx" SG_ 1440 TCM_AutoSarNMReserved2 1;
BA_ "U_P558_MY17_Gas_Rx" SG_ 1440 TCM_AutoSarNMReserved2 1;
BA_ "U_P558_MY17_Diesel_Rx" SG_ 1440 TCM_AutoSarNMReserved2 1;
BA_ "U_V36X_MY16_5_Diesel_Rx" SG_ 1440 TCM_AutoSarNMReserved2 1;
BA_ "U_C489_MY17_Gas_Rx" SG_ 1440 TCM_AutoSarNMReserved2 1;
BA_ "U_CD43_MY17_Gas_Rx" SG_ 1440 TCM_AutoSarNMReserved2 1;
BA_ "U_P552_MY17_Gas_Rx" SG_ 1440 TCM_AutoSarNMReserved2 1;
BA_ "U_B515_MCA_MY17_Diesel_Rx" SG_ 1440 TCM_AutoSarNMReserved2 1;
BA_ "U_B515_MCA_MY17_Gas_Rx" SG_ 1440 TCM_AutoSarNMReserved2 1;
BA_ "U_U55x_MY18_Gas_Rx" SG_ 1440 TCM_AutoSarNMReserved2 1;
BA_ "U_P558_MY17_Diesel_Tx" SG_ 1440 TCM_AutoSarNMReserved2 1;
BA_ "U_V36X_MY16_5_Diesel_Tx" SG_ 1440 TCM_AutoSarNMReserved2 1;
BA_ "U_P552_MY17_Gas_Tx" SG_ 1440 TCM_AutoSarNMReserved2 1;
BA_ "U_U55x_MY18_Gas_Tx" SG_ 1440 TCM_AutoSarNMReserved2 1;
BA_ "GenSigStartValue" SG_ 1440 TCM_AutoSarNMReserved1 255;
BA_ "ContentDependant" SG_ 1440 TCM_AutoSarNMReserved1 1;
BA_ "U_CD4_MY17_Diesel_Rx" SG_ 1440 TCM_AutoSarNMReserved1 1;
BA_ "U_CD4_MY17_Gas_Rx" SG_ 1440 TCM_AutoSarNMReserved1 1;
BA_ "U_CD4_MY17_Hev_Rx" SG_ 1440 TCM_AutoSarNMReserved1 1;
BA_ "U_CD4_MY17_Phev_Rx" SG_ 1440 TCM_AutoSarNMReserved1 1;
BA_ "U_P558_MY17_Gas_Rx" SG_ 1440 TCM_AutoSarNMReserved1 1;
BA_ "U_P558_MY17_Diesel_Rx" SG_ 1440 TCM_AutoSarNMReserved1 1;
BA_ "U_V36X_MY16_5_Diesel_Rx" SG_ 1440 TCM_AutoSarNMReserved1 1;
BA_ "U_C489_MY17_Gas_Rx" SG_ 1440 TCM_AutoSarNMReserved1 1;
BA_ "U_CD43_MY17_Gas_Rx" SG_ 1440 TCM_AutoSarNMReserved1 1;
BA_ "U_P552_MY17_Gas_Rx" SG_ 1440 TCM_AutoSarNMReserved1 1;
BA_ "U_B515_MCA_MY17_Diesel_Rx" SG_ 1440 TCM_AutoSarNMReserved1 1;
BA_ "U_B515_MCA_MY17_Gas_Rx" SG_ 1440 TCM_AutoSarNMReserved1 1;
BA_ "U_U55x_MY18_Gas_Rx" SG_ 1440 TCM_AutoSarNMReserved1 1;
BA_ "U_P558_MY17_Diesel_Tx" SG_ 1440 TCM_AutoSarNMReserved1 1;
BA_ "U_V36X_MY16_5_Diesel_Tx" SG_ 1440 TCM_AutoSarNMReserved1 1;
BA_ "U_P552_MY17_Gas_Tx" SG_ 1440 TCM_AutoSarNMReserved1 1;
BA_ "U_U55x_MY18_Gas_Tx" SG_ 1440 TCM_AutoSarNMReserved1 1;
BA_ "GenSigStartValue" SG_ 1440 TCM_AutoSarNMNodeId 160;
BA_ "ContentDependant" SG_ 1440 TCM_AutoSarNMNodeId 1;
BA_ "U_CD4_MY17_Diesel_Rx" SG_ 1440 TCM_AutoSarNMNodeId 1;
BA_ "U_CD4_MY17_Gas_Rx" SG_ 1440 TCM_AutoSarNMNodeId 1;
BA_ "U_CD4_MY17_Hev_Rx" SG_ 1440 TCM_AutoSarNMNodeId 1;
BA_ "U_CD4_MY17_Phev_Rx" SG_ 1440 TCM_AutoSarNMNodeId 1;
BA_ "U_P558_MY17_Gas_Rx" SG_ 1440 TCM_AutoSarNMNodeId 1;
BA_ "U_P558_MY17_Diesel_Rx" SG_ 1440 TCM_AutoSarNMNodeId 1;
BA_ "U_V36X_MY16_5_Diesel_Rx" SG_ 1440 TCM_AutoSarNMNodeId 1;
BA_ "U_C489_MY17_Gas_Rx" SG_ 1440 TCM_AutoSarNMNodeId 1;
BA_ "U_CD43_MY17_Gas_Rx" SG_ 1440 TCM_AutoSarNMNodeId 1;
BA_ "U_P552_MY17_Gas_Rx" SG_ 1440 TCM_AutoSarNMNodeId 1;
BA_ "U_B515_MCA_MY17_Diesel_Rx" SG_ 1440 TCM_AutoSarNMNodeId 1;
BA_ "U_B515_MCA_MY17_Gas_Rx" SG_ 1440 TCM_AutoSarNMNodeId 1;
BA_ "U_U55x_MY18_Gas_Rx" SG_ 1440 TCM_AutoSarNMNodeId 1;
BA_ "U_P558_MY17_Diesel_Tx" SG_ 1440 TCM_AutoSarNMNodeId 1;
BA_ "U_V36X_MY16_5_Diesel_Tx" SG_ 1440 TCM_AutoSarNMNodeId 1;
BA_ "U_P552_MY17_Gas_Tx" SG_ 1440 TCM_AutoSarNMNodeId 1;
BA_ "U_U55x_MY18_Gas_Tx" SG_ 1440 TCM_AutoSarNMNodeId 1;
BA_ "ContentDependant" SG_ 1440 TCM_AutoSarNMControl 1;
BA_ "U_CD4_MY17_Diesel_Rx" SG_ 1440 TCM_AutoSarNMControl 1;
BA_ "U_CD4_MY17_Gas_Rx" SG_ 1440 TCM_AutoSarNMControl 1;
BA_ "U_CD4_MY17_Hev_Rx" SG_ 1440 TCM_AutoSarNMControl 1;
BA_ "U_CD4_MY17_Phev_Rx" SG_ 1440 TCM_AutoSarNMControl 1;
BA_ "U_P558_MY17_Gas_Rx" SG_ 1440 TCM_AutoSarNMControl 1;
BA_ "U_P558_MY17_Diesel_Rx" SG_ 1440 TCM_AutoSarNMControl 1;
BA_ "U_V36X_MY16_5_Diesel_Rx" SG_ 1440 TCM_AutoSarNMControl 1;
BA_ "U_C489_MY17_Gas_Rx" SG_ 1440 TCM_AutoSarNMControl 1;
BA_ "U_CD43_MY17_Gas_Rx" SG_ 1440 TCM_AutoSarNMControl 1;
BA_ "U_P552_MY17_Gas_Rx" SG_ 1440 TCM_AutoSarNMControl 1;
BA_ "U_B515_MCA_MY17_Diesel_Rx" SG_ 1440 TCM_AutoSarNMControl 1;
BA_ "U_B515_MCA_MY17_Gas_Rx" SG_ 1440 TCM_AutoSarNMControl 1;
BA_ "U_U55x_MY18_Gas_Rx" SG_ 1440 TCM_AutoSarNMControl 1;
BA_ "U_P558_MY17_Diesel_Tx" SG_ 1440 TCM_AutoSarNMControl 1;
BA_ "U_V36X_MY16_5_Diesel_Tx" SG_ 1440 TCM_AutoSarNMControl 1;
BA_ "U_P552_MY17_Gas_Tx" SG_ 1440 TCM_AutoSarNMControl 1;
BA_ "U_U55x_MY18_Gas_Tx" SG_ 1440 TCM_AutoSarNMControl 1;
BA_ "U_CD42_MY16_Diesel_Tx" SG_ 330 TrnAout_W_ActlUnfilt 1;
BA_ "U_V36X_MY16_5_Diesel_Tx" SG_ 330 TrnAout_W_ActlUnfilt 1;
BA_ "U_P558_MY17_Diesel_Tx" SG_ 330 TrnAout_W_ActlUnfilt 1;
BA_ "U_CD4_MY17_Diesel_Tx" SG_ 330 TrnAout_W_ActlUnfilt 1;
BA_ "U_CD4_MY14_Diesel_Tx" SG_ 330 TrnAout_W_ActlUnfilt 1;
BA_ "U_UP375_MY15_Diesel_Tx" SG_ 330 TrnAout_W_ActlUnfilt 1;
BA_ "U_CD42_MY15_Diesel_Tx" SG_ 330 TrnAout_W_ActlUnfilt 1;
BA_ "U_CD4_MY13_Diesel_Tx" SG_ 330 TrnAout_W_ActlUnfilt 1;
BA_ "U_CD42_MY16_Diesel_Rx" SG_ 330 TrnAout_W_ActlUnfilt 1;
BA_ "U_V36X_MY16_5_Diesel_Rx" SG_ 330 TrnAout_W_ActlUnfilt 1;
BA_ "U_P558_MY17_Diesel_Rx" SG_ 330 TrnAout_W_ActlUnfilt 1;
BA_ "U_CD4_MY14_Diesel_Rx" SG_ 330 TrnAout_W_ActlUnfilt 1;
BA_ "U_UP375_MY15_Diesel_Rx" SG_ 330 TrnAout_W_ActlUnfilt 1;
BA_ "U_CD42_MY15_Diesel_Rx" SG_ 330 TrnAout_W_ActlUnfilt 1;
BA_ "U_CD4_MY13_Diesel_Rx" SG_ 330 TrnAout_W_ActlUnfilt 1;
BA_ "Gateway_ID" SG_ 532 PrplWhlTqRqMn_No_Cs 14914;
BA_ "U_V36X_MY16_5_Diesel_Rx" SG_ 532 PrplWhlTqRqMn_No_Cs 1;
BA_ "U_P558_MY17_Diesel_Rx" SG_ 532 PrplWhlTqRqMn_No_Cs 1;
BA_ "U_CD4_MY15_Gas_Rx" SG_ 532 PrplWhlTqRqMn_No_Cs 1;
BA_ "U_CD4_MY14_Phev_Rx" SG_ 532 PrplWhlTqRqMn_No_Cs 1;
BA_ "U_CD4_MY14_Hev_Rx" SG_ 532 PrplWhlTqRqMn_No_Cs 1;
BA_ "U_CD4_MY14_Gas_Rx" SG_ 532 PrplWhlTqRqMn_No_Cs 1;
BA_ "U_CD4_MY14_Diesel_Rx" SG_ 532 PrplWhlTqRqMn_No_Cs 1;
BA_ "U_UP375_MY15_Diesel_Rx" SG_ 532 PrplWhlTqRqMn_No_Cs 1;
BA_ "U_UP375_MY15_Gas_Rx" SG_ 532 PrplWhlTqRqMn_No_Cs 1;
BA_ "U_U502_MY16_Gas_Rx" SG_ 532 PrplWhlTqRqMn_No_Cs 1;
BA_ "U_CD42_MY15_Diesel_Rx" SG_ 532 PrplWhlTqRqMn_No_Cs 1;
BA_ "U_CD4_MY13_Diesel_Rx" SG_ 532 PrplWhlTqRqMn_No_Cs 1;
BA_ "Gateway_ID" SG_ 532 PrplWhlTot_Tq_RqMn 14477;
BA_ "U_V36X_MY16_5_Diesel_Rx" SG_ 532 PrplWhlTot_Tq_RqMn 1;
BA_ "U_P558_MY17_Diesel_Rx" SG_ 532 PrplWhlTot_Tq_RqMn 1;
BA_ "U_CD4_MY15_Gas_Rx" SG_ 532 PrplWhlTot_Tq_RqMn 1;
BA_ "U_CD4_MY14_Phev_Rx" SG_ 532 PrplWhlTot_Tq_RqMn 1;
BA_ "U_CD4_MY14_Hev_Rx" SG_ 532 PrplWhlTot_Tq_RqMn 1;
BA_ "U_CD4_MY14_Gas_Rx" SG_ 532 PrplWhlTot_Tq_RqMn 1;
BA_ "U_CD4_MY14_Diesel_Rx" SG_ 532 PrplWhlTot_Tq_RqMn 1;
BA_ "U_UP375_MY15_Diesel_Rx" SG_ 532 PrplWhlTot_Tq_RqMn 1;
BA_ "U_UP375_MY15_Gas_Rx" SG_ 532 PrplWhlTot_Tq_RqMn 1;
BA_ "U_U502_MY16_Gas_Rx" SG_ 532 PrplWhlTot_Tq_RqMn 1;
BA_ "U_CD42_MY15_Diesel_Rx" SG_ 532 PrplWhlTot_Tq_RqMn 1;
BA_ "U_CD4_MY13_Diesel_Rx" SG_ 532 PrplWhlTot_Tq_RqMn 1;
BA_ "Gateway_ID" SG_ 532 PrplWhlTqRqMn_No_Cnt 14909;
BA_ "U_V36X_MY16_5_Diesel_Rx" SG_ 532 PrplWhlTqRqMn_No_Cnt 1;
BA_ "U_P558_MY17_Diesel_Rx" SG_ 532 PrplWhlTqRqMn_No_Cnt 1;
BA_ "U_CD4_MY15_Gas_Rx" SG_ 532 PrplWhlTqRqMn_No_Cnt 1;
BA_ "U_CD4_MY14_Phev_Rx" SG_ 532 PrplWhlTqRqMn_No_Cnt 1;
BA_ "U_CD4_MY14_Hev_Rx" SG_ 532 PrplWhlTqRqMn_No_Cnt 1;
BA_ "U_CD4_MY14_Gas_Rx" SG_ 532 PrplWhlTqRqMn_No_Cnt 1;
BA_ "U_CD4_MY14_Diesel_Rx" SG_ 532 PrplWhlTqRqMn_No_Cnt 1;
BA_ "U_UP375_MY15_Diesel_Rx" SG_ 532 PrplWhlTqRqMn_No_Cnt 1;
BA_ "U_UP375_MY15_Gas_Rx" SG_ 532 PrplWhlTqRqMn_No_Cnt 1;
BA_ "U_U502_MY16_Gas_Rx" SG_ 532 PrplWhlTqRqMn_No_Cnt 1;
BA_ "U_CD42_MY15_Gas_Rx" SG_ 532 PrplWhlTqRqMn_No_Cnt 1;
BA_ "U_CD42_MY15_Diesel_Rx" SG_ 532 PrplWhlTqRqMn_No_Cnt 1;
BA_ "U_CD4_MY13_Gas_Rx" SG_ 532 PrplWhlTqRqMn_No_Cnt 1;
BA_ "U_CD4_MY13_Diesel_Rx" SG_ 532 PrplWhlTqRqMn_No_Cnt 1;
BA_ "U_U55x_MY18_Gas_Tx" SG_ 1060 SelDrvMdePt_D_Stat 1;
BA_ "U_V408_MY18_Gas_Tx" SG_ 1060 SelDrvMdePt_D_Stat 1;
BA_ "U_V408_MY18_Diesel_Tx" SG_ 1060 SelDrvMdePt_D_Stat 1;
BA_ "U_U55x_MY18_Gas_Tx" SG_ 1060 BpedDrvMsgTxt_B_Dsply 1;
BA_ "U_B515_MCA_MY17_Gas_Tx" SG_ 1060 BpedDrvMsgTxt_B_Dsply 1;
BA_ "U_P552_MY18_Gas_Tx" SG_ 1060 BpedDrvMsgTxt_B_Dsply 1;
BA_ "U_P552_MY17_Gas_Tx" SG_ 1060 BpedDrvMsgTxt_B_Dsply 1;
BA_ "U_C489_MY17_Gas_Tx" SG_ 1060 BpedDrvMsgTxt_B_Dsply 1;
BA_ "U_P558_MY17_Diesel_Tx" SG_ 1060 BpedDrvMsgTxt_B_Dsply 1;
BA_ "U_P558_MY17_Gas_Tx" SG_ 1060 BpedDrvMsgTxt_B_Dsply 1;
BA_ "U_P558_MY17_Gas_Rx" SG_ 1081 TrlrHitchLamp_D_Rq2_UB 1;
BA_ "U_P558_MY17_Diesel_Rx" SG_ 1081 TrlrHitchLamp_D_Rq2_UB 1;
BA_ "U_CD43_MY17_Gas_Rx" SG_ 1081 TrlrHitchLamp_D_Rq2_UB 1;
BA_ "U_U55x_MY18_Gas_Rx" SG_ 1081 TrlrHitchLamp_D_Rq2_UB 1;
BA_ "U_CD4_MY19_Diesel_Rx" SG_ 1081 TrlrHitchLamp_D_Rq2_UB 1;
BA_ "U_CD4_MY19_Gas_Rx" SG_ 1081 TrlrHitchLamp_D_Rq2_UB 1;
BA_ "U_CD4_MY19_Hev_Rx" SG_ 1081 TrlrHitchLamp_D_Rq2_UB 1;
BA_ "U_CD4_MY19_Phev_Rx" SG_ 1081 TrlrHitchLamp_D_Rq2_UB 1;
BA_ "U_S550_MY18_Gas_Rx" SG_ 1081 TrlrHitchLamp_D_Rq2_UB 1;
BA_ "U_V408_MY18_Gas_Rx" SG_ 1081 TrlrHitchLamp_D_Rq2_UB 1;
BA_ "U_V408_MY18_Diesel_Rx" SG_ 1081 TrlrHitchLamp_D_Rq2_UB 1;
BA_ "U_V36X_MY19_Rx" SG_ 1081 TrlrHitchLamp_D_Rq2_UB 1;
BA_ "U_P552_MY18_5_Gas_Rx" SG_ 1081 TrlrHitchLamp_D_Rq2_UB 1;
BA_ "U_P552_MY18_5_Diesel_Rx" SG_ 1081 TrlrHitchLamp_D_Rq2_UB 1;
BA_ "U_V363E_N_MY19_5_20_Gas_Rx" SG_ 1081 TrlrHitchLamp_D_Rq2_UB 1;
BA_ "U_V363E_N_MY19_5_20_Diesel_Rx" SG_ 1081 TrlrHitchLamp_D_Rq2_UB 1;
BA_ "GenSigSendType" SG_ 1081 TrlrHitchLamp_D_Rq2 3;
BA_ "U_P558_MY17_Gas_Rx" SG_ 1081 TrlrHitchLamp_D_Rq2 1;
BA_ "U_P558_MY17_Diesel_Rx" SG_ 1081 TrlrHitchLamp_D_Rq2 1;
BA_ "U_CD43_MY17_Gas_Rx" SG_ 1081 TrlrHitchLamp_D_Rq2 1;
BA_ "U_U55x_MY18_Gas_Rx" SG_ 1081 TrlrHitchLamp_D_Rq2 1;
BA_ "U_CD4_MY19_Diesel_Rx" SG_ 1081 TrlrHitchLamp_D_Rq2 1;
BA_ "U_CD4_MY19_Gas_Rx" SG_ 1081 TrlrHitchLamp_D_Rq2 1;
BA_ "U_CD4_MY19_Hev_Rx" SG_ 1081 TrlrHitchLamp_D_Rq2 1;
BA_ "U_CD4_MY19_Phev_Rx" SG_ 1081 TrlrHitchLamp_D_Rq2 1;
BA_ "U_S550_MY18_Gas_Rx" SG_ 1081 TrlrHitchLamp_D_Rq2 1;
BA_ "U_V408_MY18_Gas_Rx" SG_ 1081 TrlrHitchLamp_D_Rq2 1;
BA_ "U_V408_MY18_Diesel_Rx" SG_ 1081 TrlrHitchLamp_D_Rq2 1;
BA_ "U_V36X_MY19_Rx" SG_ 1081 TrlrHitchLamp_D_Rq2 1;
BA_ "U_P552_MY18_5_Gas_Rx" SG_ 1081 TrlrHitchLamp_D_Rq2 1;
BA_ "U_P552_MY18_5_Diesel_Rx" SG_ 1081 TrlrHitchLamp_D_Rq2 1;
BA_ "U_V363E_N_MY19_5_20_Gas_Rx" SG_ 1081 TrlrHitchLamp_D_Rq2 1;
BA_ "U_V363E_N_MY19_5_20_Diesel_Rx" SG_ 1081 TrlrHitchLamp_D_Rq2 1;
BA_ "CrossOver_InfoCAN" SG_ 1081 BrkBstrVac_D_Stat_UB 1;
BA_ "GenSigSendType" SG_ 1081 BrkBstrVac_D_Stat 3;
BA_ "U_U55x_MY18_Gas_Rx" SG_ 1081 SelDrvMdePt_D_Rq_UB 1;
BA_ "GenSigSendType" SG_ 1081 SelDrvMdePt_D_Rq 3;
BA_ "U_U55x_MY18_Gas_Rx" SG_ 1081 SelDrvMdePt_D_Rq 1;
BA_ "U_V408_MY18_Gas_Rx" SG_ 1081 SelDrvMdePt_D_Rq 1;
BA_ "U_V408_MY18_Diesel_Rx" SG_ 1081 SelDrvMdePt_D_Rq 1;
BA_ "GenSigStartValue" SG_ 1081 W2S_LAMP_OK 1;
BA_ "GenSigSendType" SG_ 1081 W2S_LAMP_OK 3;
BA_ "U_V36X_MY16_5_Diesel_Rx" SG_ 1081 RearPassWindowPos_UB 1;
BA_ "U_P558_MY17_Diesel_Rx" SG_ 1081 RearPassWindowPos_UB 1;
BA_ "U_P558_MY17_Gas_Rx" SG_ 1081 RearPassWindowPos_UB 1;
BA_ "U_CD4_MY15_Phev_Rx" SG_ 1081 RearPassWindowPos_UB 1;
BA_ "U_CD4_MY15_Hev_Rx" SG_ 1081 RearPassWindowPos_UB 1;
BA_ "U_CD4_MY15_Gas_Rx" SG_ 1081 RearPassWindowPos_UB 1;
BA_ "U_CD4_MY15_Diesel_Rx" SG_ 1081 RearPassWindowPos_UB 1;
BA_ "U_UP375_MY15_Diesel_Rx" SG_ 1081 RearPassWindowPos_UB 1;
BA_ "U_UP375_MY15_Gas_Rx" SG_ 1081 RearPassWindowPos_UB 1;
BA_ "U_S550_MY15_Gas_Rx" SG_ 1081 RearPassWindowPos_UB 1;
BA_ "U_CD42_MY15_Gas_Rx" SG_ 1081 RearPassWindowPos_UB 1;
BA_ "U_CD42_MY15_Diesel_Rx" SG_ 1081 RearPassWindowPos_UB 1;
BA_ "Gateway_ID" SG_ 1081 RearPassWindowPos 26543;
BA_ "U_V36X_MY16_5_Diesel_Rx" SG_ 1081 RearPassWindowPos 1;
BA_ "U_P558_MY17_Diesel_Rx" SG_ 1081 RearPassWindowPos 1;
BA_ "U_P558_MY17_Gas_Rx" SG_ 1081 RearPassWindowPos 1;
BA_ "U_CD4_MY15_Phev_Rx" SG_ 1081 RearPassWindowPos 1;
BA_ "U_CD4_MY15_Hev_Rx" SG_ 1081 RearPassWindowPos 1;
BA_ "U_CD4_MY15_Gas_Rx" SG_ 1081 RearPassWindowPos 1;
BA_ "U_CD4_MY15_Diesel_Rx" SG_ 1081 RearPassWindowPos 1;
BA_ "U_UP375_MY15_Diesel_Rx" SG_ 1081 RearPassWindowPos 1;
BA_ "U_UP375_MY15_Gas_Rx" SG_ 1081 RearPassWindowPos 1;
BA_ "U_S550_MY15_Gas_Rx" SG_ 1081 RearPassWindowPos 1;
BA_ "U_CD42_MY15_Gas_Rx" SG_ 1081 RearPassWindowPos 1;
BA_ "U_CD42_MY15_Diesel_Rx" SG_ 1081 RearPassWindowPos 1;
BA_ "WakeupSignal" SG_ 1081 RearPassWindowPos 1;
BA_ "GenSigSendType" SG_ 1081 RearPassWindowPos 3;
BA_ "U_V36X_MY16_5_Diesel_Rx" SG_ 1081 RearDriverWindowPos_UB 1;
BA_ "U_P558_MY17_Diesel_Rx" SG_ 1081 RearDriverWindowPos_UB 1;
BA_ "U_P558_MY17_Gas_Rx" SG_ 1081 RearDriverWindowPos_UB 1;
BA_ "U_CD4_MY15_Phev_Rx" SG_ 1081 RearDriverWindowPos_UB 1;
BA_ "U_CD4_MY15_Hev_Rx" SG_ 1081 RearDriverWindowPos_UB 1;
BA_ "U_CD4_MY15_Gas_Rx" SG_ 1081 RearDriverWindowPos_UB 1;
BA_ "U_CD4_MY15_Diesel_Rx" SG_ 1081 RearDriverWindowPos_UB 1;
BA_ "U_UP375_MY15_Diesel_Rx" SG_ 1081 RearDriverWindowPos_UB 1;
BA_ "U_UP375_MY15_Gas_Rx" SG_ 1081 RearDriverWindowPos_UB 1;
BA_ "U_S550_MY15_Gas_Rx" SG_ 1081 RearDriverWindowPos_UB 1;
BA_ "U_CD42_MY15_Gas_Rx" SG_ 1081 RearDriverWindowPos_UB 1;
BA_ "U_CD42_MY15_Diesel_Rx" SG_ 1081 RearDriverWindowPos_UB 1;
BA_ "Gateway_ID" SG_ 1081 RearDriverWindowPos 26542;
BA_ "U_V36X_MY16_5_Diesel_Rx" SG_ 1081 RearDriverWindowPos 1;
BA_ "U_P558_MY17_Diesel_Rx" SG_ 1081 RearDriverWindowPos 1;
BA_ "U_P558_MY17_Gas_Rx" SG_ 1081 RearDriverWindowPos 1;
BA_ "U_CD4_MY15_Phev_Rx" SG_ 1081 RearDriverWindowPos 1;
BA_ "U_CD4_MY15_Hev_Rx" SG_ 1081 RearDriverWindowPos 1;
BA_ "U_CD4_MY15_Gas_Rx" SG_ 1081 RearDriverWindowPos 1;
BA_ "U_CD4_MY15_Diesel_Rx" SG_ 1081 RearDriverWindowPos 1;
BA_ "U_UP375_MY15_Diesel_Rx" SG_ 1081 RearDriverWindowPos 1;
BA_ "U_UP375_MY15_Gas_Rx" SG_ 1081 RearDriverWindowPos 1;
BA_ "U_S550_MY15_Gas_Rx" SG_ 1081 RearDriverWindowPos 1;
BA_ "U_CD42_MY15_Gas_Rx" SG_ 1081 RearDriverWindowPos 1;
BA_ "U_CD42_MY15_Diesel_Rx" SG_ 1081 RearDriverWindowPos 1;
BA_ "WakeupSignal" SG_ 1081 RearDriverWindowPos 1;
BA_ "GenSigSendType" SG_ 1081 RearDriverWindowPos 3;
BA_ "U_V36X_MY16_5_Diesel_Rx" SG_ 1081 PassWindowPosition_UB 1;
BA_ "U_P558_MY17_Diesel_Rx" SG_ 1081 PassWindowPosition_UB 1;
BA_ "U_P558_MY17_Gas_Rx" SG_ 1081 PassWindowPosition_UB 1;
BA_ "U_CD4_MY15_Phev_Rx" SG_ 1081 PassWindowPosition_UB 1;
BA_ "U_CD4_MY15_Hev_Rx" SG_ 1081 PassWindowPosition_UB 1;
BA_ "U_CD4_MY15_Gas_Rx" SG_ 1081 PassWindowPosition_UB 1;
BA_ "U_CD4_MY15_Diesel_Rx" SG_ 1081 PassWindowPosition_UB 1;
BA_ "U_UP375_MY15_Diesel_Rx" SG_ 1081 PassWindowPosition_UB 1;
BA_ "U_UP375_MY15_Gas_Rx" SG_ 1081 PassWindowPosition_UB 1;
BA_ "U_S550_MY15_Gas_Rx" SG_ 1081 PassWindowPosition_UB 1;
BA_ "U_CD42_MY15_Gas_Rx" SG_ 1081 PassWindowPosition_UB 1;
BA_ "U_CD42_MY15_Diesel_Rx" SG_ 1081 PassWindowPosition_UB 1;
BA_ "Gateway_ID" SG_ 1081 PassWindowPosition 26540;
BA_ "U_V36X_MY16_5_Diesel_Rx" SG_ 1081 PassWindowPosition 1;
BA_ "U_P558_MY17_Diesel_Rx" SG_ 1081 PassWindowPosition 1;
BA_ "U_P558_MY17_Gas_Rx" SG_ 1081 PassWindowPosition 1;
BA_ "U_CD4_MY15_Phev_Rx" SG_ 1081 PassWindowPosition 1;
BA_ "U_CD4_MY15_Hev_Rx" SG_ 1081 PassWindowPosition 1;
BA_ "U_CD4_MY15_Gas_Rx" SG_ 1081 PassWindowPosition 1;
BA_ "U_CD4_MY15_Diesel_Rx" SG_ 1081 PassWindowPosition 1;
BA_ "U_UP375_MY15_Diesel_Rx" SG_ 1081 PassWindowPosition 1;
BA_ "U_UP375_MY15_Gas_Rx" SG_ 1081 PassWindowPosition 1;
BA_ "U_S550_MY15_Gas_Rx" SG_ 1081 PassWindowPosition 1;
BA_ "U_CD42_MY15_Gas_Rx" SG_ 1081 PassWindowPosition 1;
BA_ "U_CD42_MY15_Diesel_Rx" SG_ 1081 PassWindowPosition 1;
BA_ "WakeupSignal" SG_ 1081 PassWindowPosition 1;
BA_ "GenSigSendType" SG_ 1081 PassWindowPosition 3;
BA_ "U_V36X_MY16_5_Diesel_Rx" SG_ 1081 DriverWindowPosition_UB 1;
BA_ "U_P558_MY17_Diesel_Rx" SG_ 1081 DriverWindowPosition_UB 1;
BA_ "U_P558_MY17_Gas_Rx" SG_ 1081 DriverWindowPosition_UB 1;
BA_ "U_CD4_MY15_Phev_Rx" SG_ 1081 DriverWindowPosition_UB 1;
BA_ "U_CD4_MY15_Hev_Rx" SG_ 1081 DriverWindowPosition_UB 1;
BA_ "U_CD4_MY15_Gas_Rx" SG_ 1081 DriverWindowPosition_UB 1;
BA_ "U_CD4_MY15_Diesel_Rx" SG_ 1081 DriverWindowPosition_UB 1;
BA_ "U_UP375_MY15_Diesel_Rx" SG_ 1081 DriverWindowPosition_UB 1;
BA_ "U_UP375_MY15_Gas_Rx" SG_ 1081 DriverWindowPosition_UB 1;
BA_ "U_S550_MY15_Gas_Rx" SG_ 1081 DriverWindowPosition_UB 1;
BA_ "U_CD42_MY15_Gas_Rx" SG_ 1081 DriverWindowPosition_UB 1;
BA_ "U_CD42_MY15_Diesel_Rx" SG_ 1081 DriverWindowPosition_UB 1;
BA_ "Gateway_ID" SG_ 1081 DriverWindowPosition 26541;
BA_ "U_V36X_MY16_5_Diesel_Rx" SG_ 1081 DriverWindowPosition 1;
BA_ "U_P558_MY17_Diesel_Rx" SG_ 1081 DriverWindowPosition 1;
BA_ "U_P558_MY17_Gas_Rx" SG_ 1081 DriverWindowPosition 1;
BA_ "U_CD4_MY15_Phev_Rx" SG_ 1081 DriverWindowPosition 1;
BA_ "U_CD4_MY15_Hev_Rx" SG_ 1081 DriverWindowPosition 1;
BA_ "U_CD4_MY15_Gas_Rx" SG_ 1081 DriverWindowPosition 1;
BA_ "U_CD4_MY15_Diesel_Rx" SG_ 1081 DriverWindowPosition 1;
BA_ "U_UP375_MY15_Diesel_Rx" SG_ 1081 DriverWindowPosition 1;
BA_ "U_UP375_MY15_Gas_Rx" SG_ 1081 DriverWindowPosition 1;
BA_ "U_S550_MY15_Gas_Rx" SG_ 1081 DriverWindowPosition 1;
BA_ "U_CD42_MY15_Gas_Rx" SG_ 1081 DriverWindowPosition 1;
BA_ "U_CD42_MY15_Diesel_Rx" SG_ 1081 DriverWindowPosition 1;
BA_ "WakeupSignal" SG_ 1081 DriverWindowPosition 1;
BA_ "GenSigSendType" SG_ 1081 DriverWindowPosition 3;
VAL_ 1082 EmPrflNo_D_Rq_UB 1 "Fresh_data" 0 "Unchanged_data" ;
VAL_ 1082 EmPrflNo_D_Rq 7 "Unused_3" 6 "Unused_2" 5 "Unused_1" 4 "PERS_4" 3 "PERS_3" 2 "PERS_2" 1 "PERS_1" 0 "Null" ;
VAL_ 1082 EmPrflKeyAssoc_D_Rq_UB 1 "Fresh_data" 0 "Unchanged_data" ;
VAL_ 1082 EmPrflKeyAssoc_D_Rq 7 "NotUsed_3" 6 "DisassociatePhone" 5 "EnterPhoneAssociation" 4 "OverwriteKey" 3 "DisassociateKey" 2 "ExitKeyAssociation" 1 "EnterKeyAssociation" 0 "Null" ;
VAL_ 1082 HMI_HMIMode_St_UB 1 "Fresh_data" 0 "Unchanged_data" ;
VAL_ 1082 HMI_HMIMode_St 7 "NotUsed2" 6 "NotUsed1" 5 "Load_Shed_Active" 0 "Invalid" 1 "OffMode" 2 "On" 3 "Phone" 4 "Climate" ;
VAL_ 1100 GrossTrainWeight_M_Est 255 "Faulty" 254 "NoDataExists" ;
VAL_ 145 VehYawWActl_D_Qf 3 "OK" 2 "Not_Within_Specifications" 1 "No_Data_Exists" 0 "Faulty" ;
VAL_ 145 VehRolWActl_D_Qf 3 "OK" 2 "Not_Within_Specifications" 1 "No_Data_Exists" 0 "Faulty" ;
VAL_ 145 VehYaw_W_Actl 65535 "Faulty" 65534 "NoDataExists" ;
VAL_ 145 VehRol_W_Actl 65535 "Faulty" 65534 "NoDataExists" ;
VAL_ 980 AdbMde1_D_Rq 3 "MarkerLightFlashing" 2 "MarkerLightConstant" 1 "Spot" 0 "None" ;
VAL_ 980 AdbIntns1_D_Rq 3 "Maximum" 2 "Medium" 1 "Low" 0 "Off" ;
VAL_ 980 AdbBrdr1Up_An_Rq 511 "Faulty" 510 "NoDataExists" ;
VAL_ 980 AdbBrdr1Right_An_Rq 2047 "Faulty" 2046 "NoDataExists" ;
VAL_ 980 AdbBrdr1Low_An_Rq 511 "Faulty" 510 "NoDataExists" ;
VAL_ 980 AdbBrdr1Left_An_Rq 2047 "Faulty" 2046 "NoDataExists" ;
VAL_ 985 AdbRampingV_D_Rq 3 "Slow" 2 "Medium" 1 "Fast" 0 "Immediately" ;
VAL_ 985 AdbLampOnOff_D_Rq 3 "BothOn" 2 "LeftOnRightOff" 1 "RightOnLeftOff" 0 "BothOff" ;
VAL_ 985 AdbHiBeamKeepOff_D_Rq 3 "KeepBothOff" 2 "KeepLeftOff" 1 "KeepRightOff" 0 "BothFreeRunning" ;
VAL_ 985 AdbDividedRoad_B_Stat 1 "Yes" 0 "No" ;
VAL_ 985 DasAlrtInfo_D_Dsply 3 "NotUsed" 2 "On" 1 "Off" 0 "Null" ;
VAL_ 985 IaccVLimUnit_D_Rq 3 "NoDataExists" 2 "Mph" 1 "Kph" 0 "Null" ;
VAL_ 985 IaccVLim_D_Rq 183 "NotUsed_3_to_72_toHexFC" 2 "LimitSpeed2_to_178_toHexB2" 255 "Faulty" 254 "NoDataExists" 253 "NotUsed_73" 182 "NotUsed_2" 181 "NotUsed_1" 180 "LimitSpeed_180_kph_mph" 179 "LimitSpeed_179_kph_mph" 1 "LimitSpeed_1_kph_mph" 0 "LimitSpeed_0_kph_mph" ;
VAL_ 985 IsaVLimUnit_D_Rq 3 "NoDataExists" 2 "Mph" 1 "Kph" 0 "Null" ;
VAL_ 985 IsaVLim_D_Rq 183 "NotUsed_3_to_72_toHexFC" 2 "LimitSpeed2_to_178_toHexB2" 255 "Faulty" 254 "NoDataExists" 253 "NotUsed_73" 182 "NotUsed_2" 181 "NotUsed_1" 180 "LimitSpeed_180_kph_mph" 179 "LimitSpeed_179_kph_mph" 1 "LimitSpeed_1_kph_mph" 0 "LimitSpeed_0_kph_mph" ;
VAL_ 962 AdbMde3_D_Rq 3 "MarkerLightFlashing" 2 "MarkerLightConstant" 1 "Spot" 0 "None" ;
VAL_ 962 AdbIntns3_D_Rq 3 "Maximum" 2 "Medium" 1 "Low" 0 "Off" ;
VAL_ 962 AdbBrdr3Up_An_Rq 511 "Faulty" 510 "NoDataExists" ;
VAL_ 962 AdbBrdr3Right_An_Rq 2047 "Faulty" 2046 "NoDataExists" ;
VAL_ 962 AdbBrdr3Low_An_Rq 511 "Faulty" 510 "NoDataExists" ;
VAL_ 962 AdbBrdr3Left_An_Rq 2047 "Faulty" 2046 "NoDataExists" ;
VAL_ 961 AdbMde2_D_Rq 3 "MarkerLightFlashing" 2 "MarkerLightConstant" 1 "Spot" 0 "None" ;
VAL_ 961 AdbIntns2_D_Rq 3 "Maximum" 2 "Medium" 1 "Low" 0 "Off" ;
VAL_ 961 AdbBrdr2Up_An_Rq 511 "Faulty" 510 "NoDataExists" ;
VAL_ 961 AdbBrdr2Right_An_Rq 2047 "Faulty" 2046 "NoDataExists" ;
VAL_ 961 AdbBrdr2Low_An_Rq 511 "Faulty" 510 "NoDataExists" ;
VAL_ 961 AdbBrdr2Left_An_Rq 2047 "Faulty" 2046 "NoDataExists" ;
VAL_ 984 AhbHiBeam_D_Rq 3 "NotUsed" 2 "HIghBeamRecommended" 1 "LowBeamRecommended" 0 "DeactivatedUnavailable" ;
VAL_ 984 AhbcStat_B_Dsply 1 "On" 0 "Off" ;
VAL_ 984 AhbcHiBeam_D_Rq 3 "Deactivated_Unavailabl" 2 "Unused" 1 "Main_HighBeamRecommend" 0 "Dipped_LowBeamRecommend" ;
VAL_ 984 DasWarn_D_Dsply 3 "Undefined" 2 "Warning_Level_2" 1 "Warning_Level_1" 0 "No_Warning" ;
VAL_ 984 DasStats_D_Dsply 3 "Available" 2 "Unavailable_Other" 1 "Feedback_due_to_Speed" 0 "Off" ;
VAL_ 984 DasAlrtLvl_D_Dsply 5 "Alertness_Level_5" 4 "Alertness_Level_4" 3 "Alertness_Level_3" 2 "Alertness_Level_2" 1 "Alertness_Level_1" 0 "Undefined" ;
VAL_ 984 CamraStats_D_Dsply 3 "FrtCam_TempUnavailOther" 2 "FrtCam_TempUnavailVisibile" 1 "Front_Camera_Service_Reqd" 0 "Front_Camera_OK" ;
VAL_ 984 CamraDefog_B_Req 1 "On" 0 "Off" ;
VAL_ 984 LaHandsOff_D_Dsply 3 "Suppressed" 2 "Level2" 1 "Level1" 0 "HandsOn" ;
VAL_ 984 LaDenyStats_B_Dsply 1 "Unavailable" 0 "Available" ;
VAL_ 984 LaActvStats_D_Dsply 31 "Unused7" 30 "LA_Off" 29 "Unused5" 28 "Unused4" 27 "Unused3" 26 "Unused2" 25 "Unused1" 24 "InerveneLeft_InterveneRght" 23 "WarnLeft_InterveneRight" 22 "SuppressLeft_InterveneRght" 21 "AvailLeft_InterveneRhtt" 20 "NoLeft_InterveneRight" 19 "InterveneLeft_WarnRight" 18 "WarnLeft_WarnRight" 17 "SuppressLeft_WarnRight" 16 "AvailableLeft_WarnRight" 15 "NoLeft_WarnRight" 14 "InterveneLeft_SuppressRght" 13 "WarnLeft_SuppressRight" 12 "SuppressLeft_SuppressRight" 11 "AvailLeft_SuppressRight" 10 "NoLeft_SuppressRight" 9 "InterveneLeft_AvailRight" 8 "WarnLeft_AvailRight" 7 "SuppressLeft_AvailRight" 6 "AvailableLeft_AvailRight" 5 "NoLeft_AvailableRight" 4 "InterveneLeft_NoRight" 3 "WarnLeft_NoRight" 2 "SuppressLeft_NoRight" 1 "AvailableLeft_NoRight" 0 "NoLeft_NoRight" ;
VAL_ 984 PersIndexIpma_D_Actl 7 "Unused_3" 6 "Unused_2" 5 "Unused_1" 4 "Vehicle" 3 "PERS_4" 2 "PERS_3" 1 "PERS_2" 0 "PERS_1" ;
VAL_ 945 KeyOffMde_D_Actl 15 "NotUsed_11" 14 "NotUsed_10" 13 "NotUsed_9" 12 "NotUsed_8" 11 "NotUsed_7" 10 "NotUsed_6" 9 "NotUsed_5" 8 "NotUsed_4" 7 "NotUsed_3" 6 "NotUsed_2" 5 "NotUsed_1" 4 "CriticalBattery" 3 "Hibernate" 2 "TransportPower" 1 "FactoryPower" 0 "NormalPower" ;
VAL_ 360 GsmSrvcRqd_B_Rq 1 "Yes" 0 "No" ;
VAL_ 360 TrnGearPwmFalt_B_Actl 1 "Yes" 0 "No" ;
VAL_ 360 GearButtnStuck_B_Actl 1 "Yes" 0 "No" ;
VAL_ 1053 VehStab_D_Stat 15 "Faulty" 14 "No_Data_Exists" 13 "NotUsed6" 12 "NotUsed5" 11 "NotUsed4" 10 "NotUsed3" 9 "NotUsed2" 8 "NotUsed1" 7 "High_SSRA_no_OS" 6 "Straight" 5 "Post_Oversteer" 4 "Post_Transition" 3 "Countersteer" 2 "Understeer" 1 "Oversteer" 0 "Linear" ;
VAL_ 92 TrnValidGear_D_Cnfm 3 "Accept" 2 "Reject" 1 "Internal_Request" 0 "No_Command" ;
VAL_ 92 TrnSbwSysHlth_D_Actl 3 "OK" 2 "Degraded" 1 "No_Data_Exists" 0 "Faulty" ;
VAL_ 92 TrnNtrlTowCmd_D_Actl 3 "NotUsed" 2 "Neutral_Tow_Entry" 1 "Car_Wash_Mode" 0 "Normal_Mode" ;
VAL_ 92 TrnLvrV_D_Rq 3 "Full_Speed" 2 "Aggressive" 1 "Normal" 0 "Quiet" ;
VAL_ 92 TrnGear_D_RqPt 7 "Fault" 6 "NotUsed" 5 "Manual" 4 "Drive" 3 "Neutral" 2 "Reverse" 1 "Park" 0 "No_Gear" ;
VAL_ 92 TrnGearNtmAllow_B_Stat 1 "Yes" 0 "No" ;
VAL_ 92 TrnGearMsgTxt_D_Rq 31 "Message_31" 30 "Message_30" 29 "Message_29" 28 "Message_28" 27 "Message_27" 26 "Message_26" 25 "Message_25" 24 "Message_24" 23 "Message_23" 22 "Message_22" 21 "Message_21" 20 "Message_20" 19 "Message_19" 18 "Message_18" 17 "Message_17" 16 "Message_16" 15 "Message_15" 14 "Message_14" 13 "Message_13" 12 "Message_12" 11 "Message_11" 10 "Message_10" 9 "Message_9" 8 "Message_8" 7 "Message_7" 6 "Message_6" 5 "Message_5" 4 "Message_4" 3 "Message_3" 2 "Message_2" 1 "Message_1" 0 "NoMessage" ;
VAL_ 92 TrnGearCmd_Pc_ActlPt 1023 "Fault" ;
VAL_ 92 TrnDtpCmd_D_Actl 7 "NotUsed4" 6 "NotUsed3" 5 "NotUsed2" 4 "Relatch" 3 "Deploy" 2 "Self_Test" 1 "No_Command" 0 "NotUsed1" ;
VAL_ 92 TrnCmdState_B_Actl 1 "Yes" 0 "No" ;
VAL_ 92 PrkBrkActv_D_RqTrnGear 3 "NotUsed2" 2 "RequestParkBrakeEngage" 1 "NoRequest" 0 "NotUsed1" ;
VAL_ 92 GearSelLck_D_Rq 3 "PreventionBlocker" 2 "Unlock" 1 "Lock" 0 "Null" ;
VAL_ 381 WaterInFuel 1 "On" 0 "Off" ;
VAL_ 381 GlowIndication 1 "On" 0 "Off" ;
VAL_ 380 WhlRearDual_D_Stat 3 "NotUsed" 2 "Dual" 1 "Single" 0 "NoDataExists" ;
VAL_ 380 EngExhBrkOnLamp_B_Rq 1 "On" 0 "Off" ;
VAL_ 380 EngExhBrkAutoLamp_B_Rq 1 "On" 0 "Off" ;
VAL_ 373 DieslPrtc2_D_RqDsply 15 "NotUsed4" 14 "NotUsed3" 13 "NotUsed2" 12 "NotUsed1" 11 "OCR_ExhFilterClean_Stopped" 10 "OCR_ExhFilterCleaned" 9 "RgnOff_AtLimit" 8 "RgnOff_Overloaded" 7 "RgnOff_Loaded" 6 "Exhaust_Filter_Full" 5 "DPF_Overlimit" 4 "DPF_AtLimit" 3 "ExhFilter_Drive_Completed" 2 "Cleaning_Exhaust_Filter" 1 "DPF_Overloaded" 0 "DPF_Normal_Operation" ;
VAL_ 373 DieslPrtcRgen_D_Actl 3 "Undefined" 2 "Regen_Level_2" 1 "Regen_Level_1" 0 "No_regen" ;
VAL_ 373 EngFuelCutFull_B_Allw 1 "Yes" 0 "No" ;
VAL_ 373 EngTeColdPrtct_D_Stats 3 "Engine_Warm_RdcPwr" 2 "OK_to_Drive" 1 "Engine_Warm_PlsWait" 0 "Normal_Operation" ;
VAL_ 373 EngExhOvrTe_B_RqDsply 1 "Active" 0 "Inactive" ;
VAL_ 355 AutoRgenTxt_B_RqDsply 1 "AutExhFilterCleanOFF" 0 "AutExhFilterCleanON" ;
VAL_ 355 AccFllwMdeActv_B_Actl 1 "Active" 0 "Inactive" ;
VAL_ 355 ManRgenTxt_D_RqDsply 7 "NotUsed3" 6 "NotUsed2" 5 "NotUsed1" 4 "Cleaning_Aborted_Stopped" 3 "Cleaning_Completed" 2 "Cleaning_In_Progress" 1 "Cleaning_Allowed" 0 "Cleaning_Not_Allowed" ;
VAL_ 355 ManRgenSoot_Pc_RqDsply 127 "Fault" ;
VAL_ 355 DieslMsgTxt_D_Rq 3 "NotUsed2" 2 "NotUsed1" 1 "ReducedEnginePower" 0 "NoMessage" ;
VAL_ 332 UreaQltySys_D_RqDsply 7 "Undefined" 6 "ZZ_Overrides" 5 "EngineIdled" 4 "Engine_Idle_Upon_Refuel" 3 "SPEED_LIMITED_to_YY_mph" 2 "YY_MPH_MAX_UPON_Restart" 1 "CONTAMINATED_ExhFluid" 0 "NoQualityProblem" ;
VAL_ 332 UreaLvlTxt_D_RqDsply 11 "System_Error" 10 "Engine_Idled_See_Manual" 9 "Engine_Idled_Upon_Refuel" 8 "Speed_Limited_To_YY_mph" 7 "YYmph_Max_Upon_Restart" 6 "Speed_Limited_To_YY_mph" 5 "YYmph_Max_Upon_Restart" 4 "SpdLimtd_YYmph_In_XXmiles" 3 "ExFlRange_XXMiles_ScndWarn" 2 "Exh_Fluid_Range_XX_Miles" 1 "Exh_Fluid_Under_Half_Full" 0 "Exh_Fluid_Over_Half_Full" ;
VAL_ 1110 RstrnMdulePw_D_Falt 3 "NotUsed_1" 2 "NoFault" 1 "Fault" 0 "Null" ;
VAL_ 1071 CluPdlPosPcMeas_D_Qf 3 "OK" 2 "Not_Within_Specifications" 1 "No_Data_Exists" 0 "Faulty" ;
VAL_ 561 TrnMsgTxt2_D_Rq 7 "NotUsed3" 6 "NotUsed2" 5 "NotUsed1" 4 "TransTooHot_LoudChime" 3 "PressBrake_LoudChime" 2 "PressBrake_SoftChime" 1 "PressBrake_NoChime" 0 "NoText_NoChime" ;
VAL_ 561 TrnMsgTxt_D_Rq 15 "Message_15" 14 "Message_14" 13 "Message_13" 12 "Message_12" 11 "Message_11" 10 "Message_10" 9 "Message_9" 8 "Message_8" 7 "Message_7" 6 "Message_6" 5 "Message_5" 4 "Message_4" 3 "Message_3" 2 "Message_2" 1 "Message_1" 0 "NoMessage" ;
VAL_ 370 GearPos_D_Actl 15 "Unknown" 14 "Reverse" 13 "Undefined_5" 12 "Undefined_4" 11 "Undefined_3" 10 "Tenth" 9 "Ninth" 8 "Eighth" 7 "Seventh" 6 "Sixth" 5 "Fifth" 4 "Fourth" 3 "Third" 2 "Second" 1 "First" 0 "Neutral" ;
VAL_ 330 TrnAout_W_ActlUnfilt 32767 "Fault" 32766 "Unknown" ;
VAL_ 1060 BpedDrvMsgTxt_B_Dsply 1 "On" 0 "Off" ;
VAL_ 1081 TrlrHitchLamp_D_Rq2_UB 1 "Fresh_data" 0 "Unchanged_data" ;
VAL_ 1081 TrlrHitchLamp_D_Rq2 1 "On" 0 "Off" ;
VAL_ 1081 BrkBstrVac_D_Stat_UB 1 "Fresh_data" 0 "Unchanged_data" ;
VAL_ 1081 BrkBstrVac_D_Stat 3 "NotUsed" 2 "BoosterVacEstimator" 1 "BoosterVacSensor" 0 "NoBoosterVacuumMonitor" ;
VAL_ 1081 SelDrvMdePt_D_Rq_UB 1 "Fresh_data" 0 "Unchanged_data" ;
VAL_ 1081 SelDrvMdePt_D_Rq 31 "NotUsed16" 30 "NotUsed15" 29 "NotUsed14" 28 "NotUsed13" 27 "NotUsed12" 26 "NotUsed11" 25 "NotUsed10" 24 "NotUsed9" 23 "NotUsed8" 22 "NotUsed7" 21 "NotUsed6" 20 "NotUsed5" 19 "NotUsed4" 18 "NotUsed3" 17 "NotUsed2" 16 "NotUsed1" 15 "HighSpeedDesertMode_Baja" 14 "SportAdaptiveMode" 13 "NotAvailable_13" 12 "NotAvailable_12" 11 "NotAvailable_11" 10 "NotAvailable_10" 9 "RockCrawlMode" 8 "MudRutsMode" 7 "SandMode" 6 "EconomyMode" 5 "GrassGravelSnow" 4 "NotAvailable_04" 3 "TowHaulMode" 2 "NotAvailable_02" 1 "SportMode" 0 "NormalMode" ;
VAL_ 1081 W2S_LAMP_OK_UB 1 "Fresh_data" 0 "Unchanged_data" ;
VAL_ 1081 W2S_LAMP_OK 1 "Yes" 0 "No" ;
VAL_ 1081 RearPassWindowPos_UB 1 "Fresh_data" 0 "Unchanged_data" ;
VAL_ 1081 RearPassWindowPos 7 "Unused2" 6 "Unused1" 5 "Fully_Open" 4 "Bet60Percent_FullyOpen" 3 "Bet10Percent_60Percent" 2 "BetFully_10PercentOpen" 1 "Fully_Closed" 0 "Undefined" ;
VAL_ 1081 RearDriverWindowPos_UB 1 "Fresh_data" 0 "Unchanged_data" ;
VAL_ 1081 RearDriverWindowPos 7 "Unused2" 6 "Unused1" 5 "Fully_Open" 4 "Bet60Percent_FullyOpen" 3 "Bet10Percent_60Percent" 2 "BetFully_10PercentOpen" 1 "Fully_Closed" 0 "Undefined" ;
VAL_ 1081 PassWindowPosition_UB 1 "Fresh_data" 0 "Unchanged_data" ;
VAL_ 1081 PassWindowPosition 7 "Unused2" 6 "Unused1" 5 "Fully_Open" 4 "Bet60Percent_FullyOpen" 3 "Bet10Percent_60Percent" 2 "BetFully_10PercentOpen" 1 "Fully_Closed" 0 "Undefined" ;
VAL_ 1081 DriverWindowPosition_UB 1 "Fresh_data" 0 "Unchanged_data" ;
VAL_ 1081 DriverWindowPosition 7 "Unused2" 6 "Unused1" 5 "Fully_Open" 4 "Bet60Percent_FullyOpen" 3 "Bet10Percent_60Percent" 2 "BetFully_10PercentOpen" 1 "Fully_Closed" 0 "Undefined" ;
